VERSION ""

NS_ :

BS_:
BU_: MRR

BO_ 307 MRR_Detection_020: 64 MRR
   SG_ CAN_DET_CONFID_AZIMUTH_20_01 : 33|2@0+ (1,0) [0|3] "" IFV_VFP
   SG_ CAN_DET_SUPER_RES_TARGET_20_01 : 56|1@0+ (1,0) [0|1] "" IFV_VFP
   SG_ CAN_DET_NEW_SIGNAL_20_01 : 62|6@0+ (1,0) [0|64] "" IFV_VFP
   SG_ CAN_DET_ND_TARGET_20_01 : 48|1@0+ (1,0) [0|1] "" IFV_VFP
   SG_ CAN_DET_HOST_VEH_CLUTTER_20_01 : 49|1@0+ (1,0) [0|1] "" IFV_VFP
   SG_ CAN_DET_VALID_LEVEL_20_01 : 0|1@0+ (1,0) [0|1] "" IFV_VFP
   SG_ CAN_DET_AZIMUTH_20_01 : 47|14@0+ (0.0003834,-3.1416) [-3.1416|3.13964] "rad" IFV_VFP
   SG_ CAN_DET_RANGE_20_01 : 31|14@0+ (0.015625,0) [0|255.984] "m" IFV_VFP
   SG_ CAN_DET_RANGE_RATE_20_01 : 15|14@0+ (0.015625,-128) [-128|127.984] "m/s" IFV_VFP
   SG_ CAN_DET_AMPLITUDE_20_01 : 7|7@0+ (1,-64) [-64|63] "dBsm" IFV_VFP
   SG_ CAN_SCAN_INDEX_2LSB_20_01 : 17|2@0+ (1,0) [0|3] "" IFV_VFP
   SG_ CAN_DET_CONFID_AZIMUTH_20_02 : 105|2@0+ (1,0) [0|3] "" IFV_VFP
   SG_ CAN_DET_SUPER_RES_TARGET_20_02 : 128|1@0+ (1,0) [0|1] "" IFV_VFP
   SG_ CAN_DET_NEW_SIGNAL_20_02 : 134|6@0+ (1,0) [0|64] "" IFV_VFP
   SG_ CAN_DET_ND_TARGET_20_02 : 120|1@0+ (1,0) [0|1] "" IFV_VFP
   SG_ CAN_DET_HOST_VEH_CLUTTER_20_02 : 121|1@0+ (1,0) [0|1] "" IFV_VFP
   SG_ CAN_DET_VALID_LEVEL_20_02 : 72|1@0+ (1,0) [0|1] "" IFV_VFP
   SG_ CAN_DET_AZIMUTH_20_02 : 119|14@0+ (0.0003834,-3.1416) [-3.1416|3.13964] "rad" IFV_VFP
   SG_ CAN_DET_RANGE_20_02 : 103|14@0+ (0.015625,0) [0|255.984] "m" IFV_VFP
   SG_ CAN_DET_RANGE_RATE_20_02 : 87|14@0+ (0.015625,-128) [-128|127.984] "m/s" IFV_VFP
   SG_ CAN_DET_AMPLITUDE_20_02 : 79|7@0+ (1,-64) [-64|63] "dBsm" IFV_VFP
   SG_ CAN_SCAN_INDEX_2LSB_20_02 : 89|2@0+ (1,0) [0|3] "" IFV_VFP
   SG_ CAN_DET_CONFID_AZIMUTH_20_03 : 177|2@0+ (1,0) [0|3] "" IFV_VFP
   SG_ CAN_DET_SUPER_RES_TARGET_20_03 : 200|1@0+ (1,0) [0|1] "" IFV_VFP
   SG_ CAN_DET_NEW_SIGNAL_20_03 : 206|6@0+ (1,0) [0|64] "" IFV_VFP
   SG_ CAN_DET_ND_TARGET_20_03 : 192|1@0+ (1,0) [0|1] "" IFV_VFP
   SG_ CAN_DET_HOST_VEH_CLUTTER_20_03 : 193|1@0+ (1,0) [0|1] "" IFV_VFP
   SG_ CAN_DET_VALID_LEVEL_20_03 : 144|1@0+ (1,0) [0|1] "" IFV_VFP
   SG_ CAN_DET_AZIMUTH_20_03 : 191|14@0+ (0.0003834,-3.1416) [-3.1416|3.13964] "rad" IFV_VFP
   SG_ CAN_DET_RANGE_20_03 : 175|14@0+ (0.015625,0) [0|255.984] "m" IFV_VFP
   SG_ CAN_DET_RANGE_RATE_20_03 : 159|14@0+ (0.015625,-128) [-128|127.984] "m/s" IFV_VFP
   SG_ CAN_DET_AMPLITUDE_20_03 : 151|7@0+ (1,-64) [-64|63] "dBsm" IFV_VFP
   SG_ CAN_SCAN_INDEX_2LSB_20_03 : 161|2@0+ (1,0) [0|3] "" IFV_VFP
   SG_ CAN_DET_CONFID_AZIMUTH_20_04 : 249|2@0+ (1,0) [0|3] "" IFV_VFP
   SG_ CAN_DET_SUPER_RES_TARGET_20_04 : 272|1@0+ (1,0) [0|1] "" IFV_VFP
   SG_ CAN_DET_NEW_SIGNAL_20_04 : 278|6@0+ (1,0) [0|64] "" IFV_VFP
   SG_ CAN_DET_ND_TARGET_20_04 : 264|1@0+ (1,0) [0|1] "" IFV_VFP
   SG_ CAN_DET_HOST_VEH_CLUTTER_20_04 : 265|1@0+ (1,0) [0|1] "" IFV_VFP
   SG_ CAN_DET_VALID_LEVEL_20_04 : 216|1@0+ (1,0) [0|1] "" IFV_VFP
   SG_ CAN_DET_AZIMUTH_20_04 : 263|14@0+ (0.0003834,-3.1416) [-3.1416|3.13964] "rad" IFV_VFP
   SG_ CAN_DET_RANGE_20_04 : 247|14@0+ (0.015625,0) [0|255.984] "m" IFV_VFP
   SG_ CAN_DET_RANGE_RATE_20_04 : 231|14@0+ (0.015625,-128) [-128|127.984] "m/s" IFV_VFP
   SG_ CAN_DET_AMPLITUDE_20_04 : 223|7@0+ (1,-64) [-64|63] "dBsm" IFV_VFP
   SG_ CAN_SCAN_INDEX_2LSB_20_04 : 233|2@0+ (1,0) [0|3] "" IFV_VFP
   SG_ CAN_DET_CONFID_AZIMUTH_20_05 : 321|2@0+ (1,0) [0|3] "" IFV_VFP
   SG_ CAN_DET_SUPER_RES_TARGET_20_05 : 344|1@0+ (1,0) [0|1] "" IFV_VFP
   SG_ CAN_DET_NEW_SIGNAL_20_05 : 350|6@0+ (1,0) [0|64] "" IFV_VFP
   SG_ CAN_DET_ND_TARGET_20_05 : 336|1@0+ (1,0) [0|1] "" IFV_VFP
   SG_ CAN_DET_HOST_VEH_CLUTTER_20_05 : 337|1@0+ (1,0) [0|1] "" IFV_VFP
   SG_ CAN_DET_VALID_LEVEL_20_05 : 288|1@0+ (1,0) [0|1] "" IFV_VFP
   SG_ CAN_DET_AZIMUTH_20_05 : 335|14@0+ (0.0003834,-3.1416) [-3.1416|3.13964] "rad" IFV_VFP
   SG_ CAN_DET_RANGE_20_05 : 319|14@0+ (0.015625,0) [0|255.984] "m" IFV_VFP
   SG_ CAN_DET_RANGE_RATE_20_05 : 303|14@0+ (0.015625,-128) [-128|127.984] "m/s" IFV_VFP
   SG_ CAN_DET_AMPLITUDE_20_05 : 295|7@0+ (1,-64) [-64|63] "dBsm" IFV_VFP
   SG_ CAN_SCAN_INDEX_2LSB_20_05 : 305|2@0+ (1,0) [0|3] "" IFV_VFP
   SG_ CAN_DET_CONFID_AZIMUTH_20_06 : 393|2@0+ (1,0) [0|3] "" IFV_VFP
   SG_ CAN_DET_SUPER_RES_TARGET_20_06 : 416|1@0+ (1,0) [0|1] "" IFV_VFP
   SG_ CAN_DET_NEW_SIGNAL_20_06 : 422|6@0+ (1,0) [0|64] "" IFV_VFP
   SG_ CAN_DET_ND_TARGET_20_06 : 408|1@0+ (1,0) [0|1] "" IFV_VFP
   SG_ CAN_DET_HOST_VEH_CLUTTER_20_06 : 409|1@0+ (1,0) [0|1] "" IFV_VFP
   SG_ CAN_DET_VALID_LEVEL_20_06 : 360|1@0+ (1,0) [0|1] "" IFV_VFP
   SG_ CAN_DET_AZIMUTH_20_06 : 407|14@0+ (0.0003834,-3.1416) [-3.1416|3.13964] "rad" IFV_VFP
   SG_ CAN_DET_RANGE_20_06 : 391|14@0+ (0.015625,0) [0|255.984] "m" IFV_VFP
   SG_ CAN_DET_RANGE_RATE_20_06 : 375|14@0+ (0.015625,-128) [-128|127.984] "m/s" IFV_VFP
   SG_ CAN_DET_AMPLITUDE_20_06 : 367|7@0+ (1,-64) [-64|63] "dBsm" IFV_VFP
   SG_ CAN_SCAN_INDEX_2LSB_20_06 : 377|2@0+ (1,0) [0|3] "" IFV_VFP

BO_ 306 MRR_Detection_019: 64 MRR
   SG_ CAN_DET_CONFID_AZIMUTH_19_01 : 33|2@0+ (1,0) [0|3] "" IFV_VFP
   SG_ CAN_DET_SUPER_RES_TARGET_19_01 : 56|1@0+ (1,0) [0|1] "" IFV_VFP
   SG_ CAN_DET_NEW_SIGNAL_19_01 : 62|6@0+ (1,0) [0|64] "" IFV_VFP
   SG_ CAN_DET_ND_TARGET_19_01 : 48|1@0+ (1,0) [0|1] "" IFV_VFP
   SG_ CAN_DET_HOST_VEH_CLUTTER_19_01 : 49|1@0+ (1,0) [0|1] "" IFV_VFP
   SG_ CAN_DET_VALID_LEVEL_19_01 : 0|1@0+ (1,0) [0|1] "" IFV_VFP
   SG_ CAN_DET_AZIMUTH_19_01 : 47|14@0+ (0.0003834,-3.1416) [-3.1416|3.13964] "rad" IFV_VFP
   SG_ CAN_DET_RANGE_19_01 : 31|14@0+ (0.015625,0) [0|255.984] "m" IFV_VFP
   SG_ CAN_DET_RANGE_RATE_19_01 : 15|14@0+ (0.015625,-128) [-128|127.984] "m/s" IFV_VFP
   SG_ CAN_DET_AMPLITUDE_19_01 : 7|7@0+ (1,-64) [-64|63] "dBsm" IFV_VFP
   SG_ CAN_SCAN_INDEX_2LSB_19_01 : 17|2@0+ (1,0) [0|3] "" IFV_VFP
   SG_ CAN_DET_CONFID_AZIMUTH_19_02 : 105|2@0+ (1,0) [0|3] "" IFV_VFP
   SG_ CAN_DET_SUPER_RES_TARGET_19_02 : 128|1@0+ (1,0) [0|1] "" IFV_VFP
   SG_ CAN_DET_NEW_SIGNAL_19_02 : 134|6@0+ (1,0) [0|64] "" IFV_VFP
   SG_ CAN_DET_ND_TARGET_19_02 : 120|1@0+ (1,0) [0|1] "" IFV_VFP
   SG_ CAN_DET_HOST_VEH_CLUTTER_19_02 : 121|1@0+ (1,0) [0|1] "" IFV_VFP
   SG_ CAN_DET_VALID_LEVEL_19_02 : 72|1@0+ (1,0) [0|1] "" IFV_VFP
   SG_ CAN_DET_AZIMUTH_19_02 : 119|14@0+ (0.0003834,-3.1416) [-3.1416|3.13964] "rad" IFV_VFP
   SG_ CAN_DET_RANGE_19_02 : 103|14@0+ (0.015625,0) [0|255.984] "m" IFV_VFP
   SG_ CAN_DET_RANGE_RATE_19_02 : 87|14@0+ (0.015625,-128) [-128|127.984] "m/s" IFV_VFP
   SG_ CAN_DET_AMPLITUDE_19_02 : 79|7@0+ (1,-64) [-64|63] "dBsm" IFV_VFP
   SG_ CAN_SCAN_INDEX_2LSB_19_02 : 89|2@0+ (1,0) [0|3] "" IFV_VFP
   SG_ CAN_DET_CONFID_AZIMUTH_19_03 : 177|2@0+ (1,0) [0|3] "" IFV_VFP
   SG_ CAN_DET_SUPER_RES_TARGET_19_03 : 200|1@0+ (1,0) [0|1] "" IFV_VFP
   SG_ CAN_DET_NEW_SIGNAL_19_03 : 206|6@0+ (1,0) [0|64] "" IFV_VFP
   SG_ CAN_DET_ND_TARGET_19_03 : 192|1@0+ (1,0) [0|1] "" IFV_VFP
   SG_ CAN_DET_HOST_VEH_CLUTTER_19_03 : 193|1@0+ (1,0) [0|1] "" IFV_VFP
   SG_ CAN_DET_VALID_LEVEL_19_03 : 144|1@0+ (1,0) [0|1] "" IFV_VFP
   SG_ CAN_DET_AZIMUTH_19_03 : 191|14@0+ (0.0003834,-3.1416) [-3.1416|3.13964] "rad" IFV_VFP
   SG_ CAN_DET_RANGE_19_03 : 175|14@0+ (0.015625,0) [0|255.984] "m" IFV_VFP
   SG_ CAN_DET_RANGE_RATE_19_03 : 159|14@0+ (0.015625,-128) [-128|127.984] "m/s" IFV_VFP
   SG_ CAN_DET_AMPLITUDE_19_03 : 151|7@0+ (1,-64) [-64|63] "dBsm" IFV_VFP
   SG_ CAN_SCAN_INDEX_2LSB_19_03 : 161|2@0+ (1,0) [0|3] "" IFV_VFP
   SG_ CAN_DET_CONFID_AZIMUTH_19_04 : 249|2@0+ (1,0) [0|3] "" IFV_VFP
   SG_ CAN_DET_SUPER_RES_TARGET_19_04 : 272|1@0+ (1,0) [0|1] "" IFV_VFP
   SG_ CAN_DET_NEW_SIGNAL_19_04 : 278|6@0+ (1,0) [0|64] "" IFV_VFP
   SG_ CAN_DET_ND_TARGET_19_04 : 264|1@0+ (1,0) [0|1] "" IFV_VFP
   SG_ CAN_DET_HOST_VEH_CLUTTER_19_04 : 265|1@0+ (1,0) [0|1] "" IFV_VFP
   SG_ CAN_DET_VALID_LEVEL_19_04 : 216|1@0+ (1,0) [0|1] "" IFV_VFP
   SG_ CAN_DET_AZIMUTH_19_04 : 263|14@0+ (0.0003834,-3.1416) [-3.1416|3.13964] "rad" IFV_VFP
   SG_ CAN_DET_RANGE_19_04 : 247|14@0+ (0.015625,0) [0|255.984] "m" IFV_VFP
   SG_ CAN_DET_RANGE_RATE_19_04 : 231|14@0+ (0.015625,-128) [-128|127.984] "m/s" IFV_VFP
   SG_ CAN_DET_AMPLITUDE_19_04 : 223|7@0+ (1,-64) [-64|63] "dBsm" IFV_VFP
   SG_ CAN_SCAN_INDEX_2LSB_19_04 : 233|2@0+ (1,0) [0|3] "" IFV_VFP
   SG_ CAN_DET_CONFID_AZIMUTH_19_05 : 321|2@0+ (1,0) [0|3] "" IFV_VFP
   SG_ CAN_DET_SUPER_RES_TARGET_19_05 : 344|1@0+ (1,0) [0|1] "" IFV_VFP
   SG_ CAN_DET_NEW_SIGNAL_19_05 : 350|6@0+ (1,0) [0|64] "" IFV_VFP
   SG_ CAN_DET_ND_TARGET_19_05 : 336|1@0+ (1,0) [0|1] "" IFV_VFP
   SG_ CAN_DET_HOST_VEH_CLUTTER_19_05 : 337|1@0+ (1,0) [0|1] "" IFV_VFP
   SG_ CAN_DET_VALID_LEVEL_19_05 : 288|1@0+ (1,0) [0|1] "" IFV_VFP
   SG_ CAN_DET_AZIMUTH_19_05 : 335|14@0+ (0.0003834,-3.1416) [-3.1416|3.13964] "rad" IFV_VFP
   SG_ CAN_DET_RANGE_19_05 : 319|14@0+ (0.015625,0) [0|255.984] "m" IFV_VFP
   SG_ CAN_DET_RANGE_RATE_19_05 : 303|14@0+ (0.015625,-128) [-128|127.984] "m/s" IFV_VFP
   SG_ CAN_DET_AMPLITUDE_19_05 : 295|7@0+ (1,-64) [-64|63] "dBsm" IFV_VFP
   SG_ CAN_SCAN_INDEX_2LSB_19_05 : 305|2@0+ (1,0) [0|3] "" IFV_VFP
   SG_ CAN_DET_CONFID_AZIMUTH_19_06 : 393|2@0+ (1,0) [0|3] "" IFV_VFP
   SG_ CAN_DET_SUPER_RES_TARGET_19_06 : 416|1@0+ (1,0) [0|1] "" IFV_VFP
   SG_ CAN_DET_NEW_SIGNAL_19_06 : 422|6@0+ (1,0) [0|64] "" IFV_VFP
   SG_ CAN_DET_ND_TARGET_19_06 : 408|1@0+ (1,0) [0|1] "" IFV_VFP
   SG_ CAN_DET_HOST_VEH_CLUTTER_19_06 : 409|1@0+ (1,0) [0|1] "" IFV_VFP
   SG_ CAN_DET_VALID_LEVEL_19_06 : 360|1@0+ (1,0) [0|1] "" IFV_VFP
   SG_ CAN_DET_AZIMUTH_19_06 : 407|14@0+ (0.0003834,-3.1416) [-3.1416|3.13964] "rad" IFV_VFP
   SG_ CAN_DET_RANGE_19_06 : 391|14@0+ (0.015625,0) [0|255.984] "m" IFV_VFP
   SG_ CAN_DET_RANGE_RATE_19_06 : 375|14@0+ (0.015625,-128) [-128|127.984] "m/s" IFV_VFP
   SG_ CAN_DET_AMPLITUDE_19_06 : 367|7@0+ (1,-64) [-64|63] "dBsm" IFV_VFP
   SG_ CAN_SCAN_INDEX_2LSB_19_06 : 377|2@0+ (1,0) [0|3] "" IFV_VFP

BO_ 305 MRR_Detection_018: 64 MRR
   SG_ CAN_DET_CONFID_AZIMUTH_18_01 : 33|2@0+ (1,0) [0|3] "" IFV_VFP
   SG_ CAN_DET_SUPER_RES_TARGET_18_01 : 56|1@0+ (1,0) [0|1] "" IFV_VFP
   SG_ CAN_DET_NEW_SIGNAL_18_01 : 62|6@0+ (1,0) [0|64] "" IFV_VFP
   SG_ CAN_DET_ND_TARGET_18_01 : 48|1@0+ (1,0) [0|1] "" IFV_VFP
   SG_ CAN_DET_HOST_VEH_CLUTTER_18_01 : 49|1@0+ (1,0) [0|1] "" IFV_VFP
   SG_ CAN_DET_VALID_LEVEL_18_01 : 0|1@0+ (1,0) [0|1] "" IFV_VFP
   SG_ CAN_DET_AZIMUTH_18_01 : 47|14@0+ (0.0003834,-3.1416) [-3.1416|3.13964] "rad" IFV_VFP
   SG_ CAN_DET_RANGE_18_01 : 31|14@0+ (0.015625,0) [0|255.984] "m" IFV_VFP
   SG_ CAN_DET_RANGE_RATE_18_01 : 15|14@0+ (0.015625,-128) [-128|127.984] "m/s" IFV_VFP
   SG_ CAN_DET_AMPLITUDE_18_01 : 7|7@0+ (1,-64) [-64|63] "dBsm" IFV_VFP
   SG_ CAN_SCAN_INDEX_2LSB_18_01 : 17|2@0+ (1,0) [0|3] "" IFV_VFP
   SG_ CAN_DET_CONFID_AZIMUTH_18_02 : 105|2@0+ (1,0) [0|3] "" IFV_VFP
   SG_ CAN_DET_SUPER_RES_TARGET_18_02 : 128|1@0+ (1,0) [0|1] "" IFV_VFP
   SG_ CAN_DET_NEW_SIGNAL_18_02 : 134|6@0+ (1,0) [0|64] "" IFV_VFP
   SG_ CAN_DET_ND_TARGET_18_02 : 120|1@0+ (1,0) [0|1] "" IFV_VFP
   SG_ CAN_DET_HOST_VEH_CLUTTER_18_02 : 121|1@0+ (1,0) [0|1] "" IFV_VFP
   SG_ CAN_DET_VALID_LEVEL_18_02 : 72|1@0+ (1,0) [0|1] "" IFV_VFP
   SG_ CAN_DET_AZIMUTH_18_02 : 119|14@0+ (0.0003834,-3.1416) [-3.1416|3.13964] "rad" IFV_VFP
   SG_ CAN_DET_RANGE_18_02 : 103|14@0+ (0.015625,0) [0|255.984] "m" IFV_VFP
   SG_ CAN_DET_RANGE_RATE_18_02 : 87|14@0+ (0.015625,-128) [-128|127.984] "m/s" IFV_VFP
   SG_ CAN_DET_AMPLITUDE_18_02 : 79|7@0+ (1,-64) [-64|63] "dBsm" IFV_VFP
   SG_ CAN_SCAN_INDEX_2LSB_18_02 : 89|2@0+ (1,0) [0|3] "" IFV_VFP
   SG_ CAN_DET_CONFID_AZIMUTH_18_03 : 177|2@0+ (1,0) [0|3] "" IFV_VFP
   SG_ CAN_DET_SUPER_RES_TARGET_18_03 : 200|1@0+ (1,0) [0|1] "" IFV_VFP
   SG_ CAN_DET_NEW_SIGNAL_18_03 : 206|6@0+ (1,0) [0|64] "" IFV_VFP
   SG_ CAN_DET_ND_TARGET_18_03 : 192|1@0+ (1,0) [0|1] "" IFV_VFP
   SG_ CAN_DET_HOST_VEH_CLUTTER_18_03 : 193|1@0+ (1,0) [0|1] "" IFV_VFP
   SG_ CAN_DET_VALID_LEVEL_18_03 : 144|1@0+ (1,0) [0|1] "" IFV_VFP
   SG_ CAN_DET_AZIMUTH_18_03 : 191|14@0+ (0.0003834,-3.1416) [-3.1416|3.13964] "rad" IFV_VFP
   SG_ CAN_DET_RANGE_18_03 : 175|14@0+ (0.015625,0) [0|255.984] "m" IFV_VFP
   SG_ CAN_DET_RANGE_RATE_18_03 : 159|14@0+ (0.015625,-128) [-128|127.984] "m/s" IFV_VFP
   SG_ CAN_DET_AMPLITUDE_18_03 : 151|7@0+ (1,-64) [-64|63] "dBsm" IFV_VFP
   SG_ CAN_SCAN_INDEX_2LSB_18_03 : 161|2@0+ (1,0) [0|3] "" IFV_VFP
   SG_ CAN_DET_CONFID_AZIMUTH_18_04 : 249|2@0+ (1,0) [0|3] "" IFV_VFP
   SG_ CAN_DET_SUPER_RES_TARGET_18_04 : 272|1@0+ (1,0) [0|1] "" IFV_VFP
   SG_ CAN_DET_NEW_SIGNAL_18_04 : 278|6@0+ (1,0) [0|64] "" IFV_VFP
   SG_ CAN_DET_ND_TARGET_18_04 : 264|1@0+ (1,0) [0|1] "" IFV_VFP
   SG_ CAN_DET_HOST_VEH_CLUTTER_18_04 : 265|1@0+ (1,0) [0|1] "" IFV_VFP
   SG_ CAN_DET_VALID_LEVEL_18_04 : 216|1@0+ (1,0) [0|1] "" IFV_VFP
   SG_ CAN_DET_AZIMUTH_18_04 : 263|14@0+ (0.0003834,-3.1416) [-3.1416|3.13964] "rad" IFV_VFP
   SG_ CAN_DET_RANGE_18_04 : 247|14@0+ (0.015625,0) [0|255.984] "m" IFV_VFP
   SG_ CAN_DET_RANGE_RATE_18_04 : 231|14@0+ (0.015625,-128) [-128|127.984] "m/s" IFV_VFP
   SG_ CAN_DET_AMPLITUDE_18_04 : 223|7@0+ (1,-64) [-64|63] "dBsm" IFV_VFP
   SG_ CAN_SCAN_INDEX_2LSB_18_04 : 233|2@0+ (1,0) [0|3] "" IFV_VFP
   SG_ CAN_DET_CONFID_AZIMUTH_18_05 : 321|2@0+ (1,0) [0|3] "" IFV_VFP
   SG_ CAN_DET_SUPER_RES_TARGET_18_05 : 344|1@0+ (1,0) [0|1] "" IFV_VFP
   SG_ CAN_DET_NEW_SIGNAL_18_05 : 350|6@0+ (1,0) [0|64] "" IFV_VFP
   SG_ CAN_DET_ND_TARGET_18_05 : 336|1@0+ (1,0) [0|1] "" IFV_VFP
   SG_ CAN_DET_HOST_VEH_CLUTTER_18_05 : 337|1@0+ (1,0) [0|1] "" IFV_VFP
   SG_ CAN_DET_VALID_LEVEL_18_05 : 288|1@0+ (1,0) [0|1] "" IFV_VFP
   SG_ CAN_DET_AZIMUTH_18_05 : 335|14@0+ (0.0003834,-3.1416) [-3.1416|3.13964] "rad" IFV_VFP
   SG_ CAN_DET_RANGE_18_05 : 319|14@0+ (0.015625,0) [0|255.984] "m" IFV_VFP
   SG_ CAN_DET_RANGE_RATE_18_05 : 303|14@0+ (0.015625,-128) [-128|127.984] "m/s" IFV_VFP
   SG_ CAN_DET_AMPLITUDE_18_05 : 295|7@0+ (1,-64) [-64|63] "dBsm" IFV_VFP
   SG_ CAN_SCAN_INDEX_2LSB_18_05 : 305|2@0+ (1,0) [0|3] "" IFV_VFP
   SG_ CAN_DET_CONFID_AZIMUTH_18_06 : 393|2@0+ (1,0) [0|3] "" IFV_VFP
   SG_ CAN_DET_SUPER_RES_TARGET_18_06 : 416|1@0+ (1,0) [0|1] "" IFV_VFP
   SG_ CAN_DET_NEW_SIGNAL_18_06 : 422|6@0+ (1,0) [0|64] "" IFV_VFP
   SG_ CAN_DET_ND_TARGET_18_06 : 408|1@0+ (1,0) [0|1] "" IFV_VFP
   SG_ CAN_DET_HOST_VEH_CLUTTER_18_06 : 409|1@0+ (1,0) [0|1] "" IFV_VFP
   SG_ CAN_DET_VALID_LEVEL_18_06 : 360|1@0+ (1,0) [0|1] "" IFV_VFP
   SG_ CAN_DET_AZIMUTH_18_06 : 407|14@0+ (0.0003834,-3.1416) [-3.1416|3.13964] "rad" IFV_VFP
   SG_ CAN_DET_RANGE_18_06 : 391|14@0+ (0.015625,0) [0|255.984] "m" IFV_VFP
   SG_ CAN_DET_RANGE_RATE_18_06 : 375|14@0+ (0.015625,-128) [-128|127.984] "m/s" IFV_VFP
   SG_ CAN_DET_AMPLITUDE_18_06 : 367|7@0+ (1,-64) [-64|63] "dBsm" IFV_VFP
   SG_ CAN_SCAN_INDEX_2LSB_18_06 : 377|2@0+ (1,0) [0|3] "" IFV_VFP

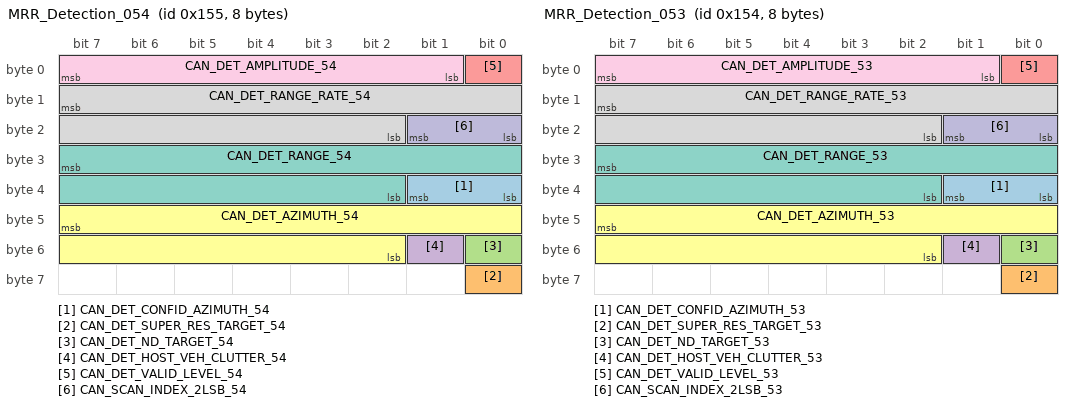
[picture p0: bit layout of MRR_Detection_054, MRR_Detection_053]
BO_ 341 MRR_Detection_054: 8 MRR
   SG_ CAN_DET_CONFID_AZIMUTH_54 : 33|2@0+ (1,0) [0|3] "" IFV_VFP
   SG_ CAN_DET_SUPER_RES_TARGET_54 : 56|1@0+ (1,0) [0|1] "" IFV_VFP
   SG_ CAN_DET_ND_TARGET_54 : 48|1@0+ (1,0) [0|1] "" IFV_VFP
   SG_ CAN_DET_HOST_VEH_CLUTTER_54 : 49|1@0+ (1,0) [0|1] "" IFV_VFP
   SG_ CAN_DET_VALID_LEVEL_54 : 0|1@0+ (1,0) [0|1] "" IFV_VFP
   SG_ CAN_DET_AZIMUTH_54 : 47|14@0+ (0.0003834,-3.1416) [-3.1416|3.13964] "rad" IFV_VFP
   SG_ CAN_DET_RANGE_54 : 31|14@0+ (0.015625,0) [0|255.984] "m" IFV_VFP
   SG_ CAN_DET_RANGE_RATE_54 : 15|14@0+ (0.015625,-128) [-128|127.984] "m/s" IFV_VFP
   SG_ CAN_DET_AMPLITUDE_54 : 7|7@0+ (1,-64) [-64|63] "dBsm" IFV_VFP
   SG_ CAN_SCAN_INDEX_2LSB_54 : 17|2@0+ (1,0) [0|3] "" IFV_VFP

BO_ 340 MRR_Detection_053: 8 MRR
   SG_ CAN_DET_CONFID_AZIMUTH_53 : 33|2@0+ (1,0) [0|3] "" IFV_VFP
   SG_ CAN_DET_SUPER_RES_TARGET_53 : 56|1@0+ (1,0) [0|1] "" IFV_VFP
   SG_ CAN_DET_ND_TARGET_53 : 48|1@0+ (1,0) [0|1] "" IFV_VFP
   SG_ CAN_DET_HOST_VEH_CLUTTER_53 : 49|1@0+ (1,0) [0|1] "" IFV_VFP
   SG_ CAN_DET_VALID_LEVEL_53 : 0|1@0+ (1,0) [0|1] "" IFV_VFP
   SG_ CAN_DET_AZIMUTH_53 : 47|14@0+ (0.0003834,-3.1416) [-3.1416|3.13964] "rad" IFV_VFP
   SG_ CAN_DET_RANGE_53 : 31|14@0+ (0.015625,0) [0|255.984] "m" IFV_VFP
   SG_ CAN_DET_RANGE_RATE_53 : 15|14@0+ (0.015625,-128) [-128|127.984] "m/s" IFV_VFP
   SG_ CAN_DET_AMPLITUDE_53 : 7|7@0+ (1,-64) [-64|63] "dBsm" IFV_VFP
   SG_ CAN_SCAN_INDEX_2LSB_53 : 17|2@0+ (1,0) [0|3] "" IFV_VFP

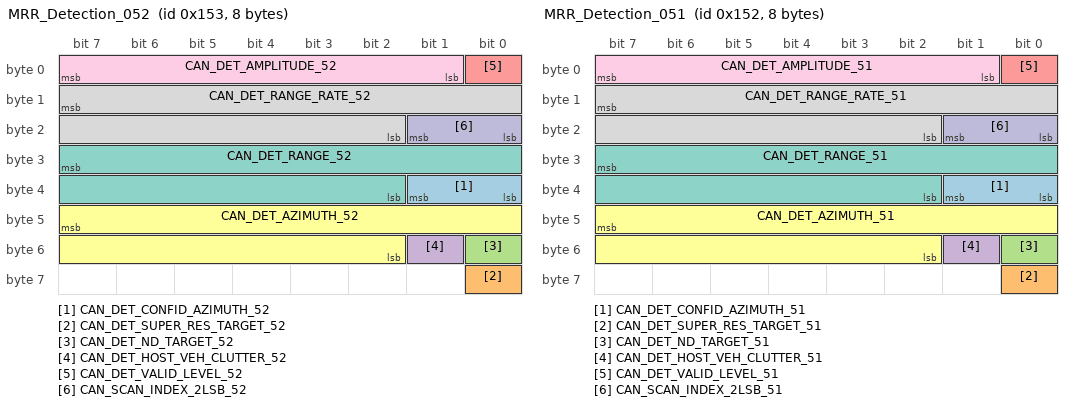
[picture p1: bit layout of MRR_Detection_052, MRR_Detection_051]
BO_ 339 MRR_Detection_052: 8 MRR
   SG_ CAN_DET_CONFID_AZIMUTH_52 : 33|2@0+ (1,0) [0|3] "" IFV_VFP
   SG_ CAN_DET_SUPER_RES_TARGET_52 : 56|1@0+ (1,0) [0|1] "" IFV_VFP
   SG_ CAN_DET_ND_TARGET_52 : 48|1@0+ (1,0) [0|1] "" IFV_VFP
   SG_ CAN_DET_HOST_VEH_CLUTTER_52 : 49|1@0+ (1,0) [0|1] "" IFV_VFP
   SG_ CAN_DET_VALID_LEVEL_52 : 0|1@0+ (1,0) [0|1] "" IFV_VFP
   SG_ CAN_DET_AZIMUTH_52 : 47|14@0+ (0.0003834,-3.1416) [-3.1416|3.13964] "rad" IFV_VFP
   SG_ CAN_DET_RANGE_52 : 31|14@0+ (0.015625,0) [0|255.984] "m" IFV_VFP
   SG_ CAN_DET_RANGE_RATE_52 : 15|14@0+ (0.015625,-128) [-128|127.984] "m/s" IFV_VFP
   SG_ CAN_DET_AMPLITUDE_52 : 7|7@0+ (1,-64) [-64|63] "dBsm" IFV_VFP
   SG_ CAN_SCAN_INDEX_2LSB_52 : 17|2@0+ (1,0) [0|3] "" IFV_VFP

BO_ 338 MRR_Detection_051: 8 MRR
   SG_ CAN_DET_CONFID_AZIMUTH_51 : 33|2@0+ (1,0) [0|3] "" IFV_VFP
   SG_ CAN_DET_SUPER_RES_TARGET_51 : 56|1@0+ (1,0) [0|1] "" IFV_VFP
   SG_ CAN_DET_ND_TARGET_51 : 48|1@0+ (1,0) [0|1] "" IFV_VFP
   SG_ CAN_DET_HOST_VEH_CLUTTER_51 : 49|1@0+ (1,0) [0|1] "" IFV_VFP
   SG_ CAN_DET_VALID_LEVEL_51 : 0|1@0+ (1,0) [0|1] "" IFV_VFP
   SG_ CAN_DET_AZIMUTH_51 : 47|14@0+ (0.0003834,-3.1416) [-3.1416|3.13964] "rad" IFV_VFP
   SG_ CAN_DET_RANGE_51 : 31|14@0+ (0.015625,0) [0|255.984] "m" IFV_VFP
   SG_ CAN_DET_RANGE_RATE_51 : 15|14@0+ (0.015625,-128) [-128|127.984] "m/s" IFV_VFP
   SG_ CAN_DET_AMPLITUDE_51 : 7|7@0+ (1,-64) [-64|63] "dBsm" IFV_VFP
   SG_ CAN_SCAN_INDEX_2LSB_51 : 17|2@0+ (1,0) [0|3] "" IFV_VFP

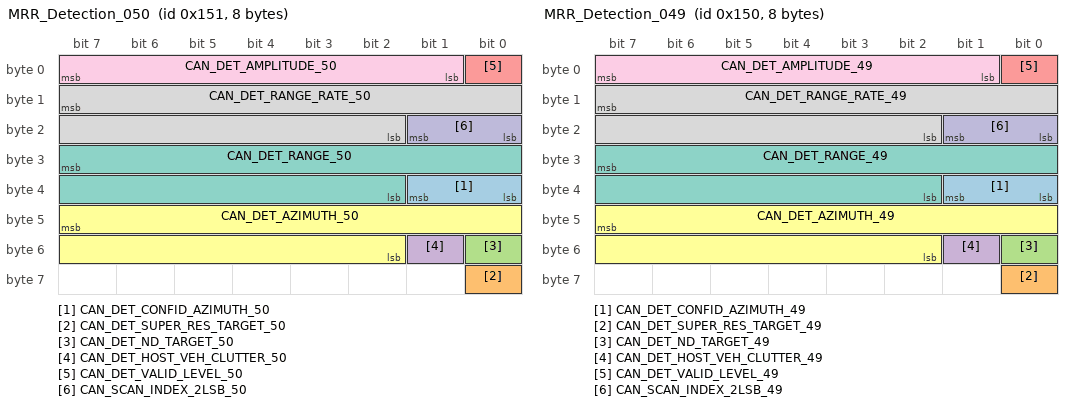
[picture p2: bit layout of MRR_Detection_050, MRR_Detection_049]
BO_ 337 MRR_Detection_050: 8 MRR
   SG_ CAN_DET_CONFID_AZIMUTH_50 : 33|2@0+ (1,0) [0|3] "" IFV_VFP
   SG_ CAN_DET_SUPER_RES_TARGET_50 : 56|1@0+ (1,0) [0|1] "" IFV_VFP
   SG_ CAN_DET_ND_TARGET_50 : 48|1@0+ (1,0) [0|1] "" IFV_VFP
   SG_ CAN_DET_HOST_VEH_CLUTTER_50 : 49|1@0+ (1,0) [0|1] "" IFV_VFP
   SG_ CAN_DET_VALID_LEVEL_50 : 0|1@0+ (1,0) [0|1] "" IFV_VFP
   SG_ CAN_DET_AZIMUTH_50 : 47|14@0+ (0.0003834,-3.1416) [-3.1416|3.13964] "rad" IFV_VFP
   SG_ CAN_DET_RANGE_50 : 31|14@0+ (0.015625,0) [0|255.984] "m" IFV_VFP
   SG_ CAN_DET_RANGE_RATE_50 : 15|14@0+ (0.015625,-128) [-128|127.984] "m/s" IFV_VFP
   SG_ CAN_DET_AMPLITUDE_50 : 7|7@0+ (1,-64) [-64|63] "dBsm" IFV_VFP
   SG_ CAN_SCAN_INDEX_2LSB_50 : 17|2@0+ (1,0) [0|3] "" IFV_VFP

BO_ 336 MRR_Detection_049: 8 MRR
   SG_ CAN_DET_CONFID_AZIMUTH_49 : 33|2@0+ (1,0) [0|3] "" IFV_VFP
   SG_ CAN_DET_SUPER_RES_TARGET_49 : 56|1@0+ (1,0) [0|1] "" IFV_VFP
   SG_ CAN_DET_ND_TARGET_49 : 48|1@0+ (1,0) [0|1] "" IFV_VFP
   SG_ CAN_DET_HOST_VEH_CLUTTER_49 : 49|1@0+ (1,0) [0|1] "" IFV_VFP
   SG_ CAN_DET_VALID_LEVEL_49 : 0|1@0+ (1,0) [0|1] "" IFV_VFP
   SG_ CAN_DET_AZIMUTH_49 : 47|14@0+ (0.0003834,-3.1416) [-3.1416|3.13964] "rad" IFV_VFP
   SG_ CAN_DET_RANGE_49 : 31|14@0+ (0.015625,0) [0|255.984] "m" IFV_VFP
   SG_ CAN_DET_RANGE_RATE_49 : 15|14@0+ (0.015625,-128) [-128|127.984] "m/s" IFV_VFP
   SG_ CAN_DET_AMPLITUDE_49 : 7|7@0+ (1,-64) [-64|63] "dBsm" IFV_VFP
   SG_ CAN_SCAN_INDEX_2LSB_49 : 17|2@0+ (1,0) [0|3] "" IFV_VFP

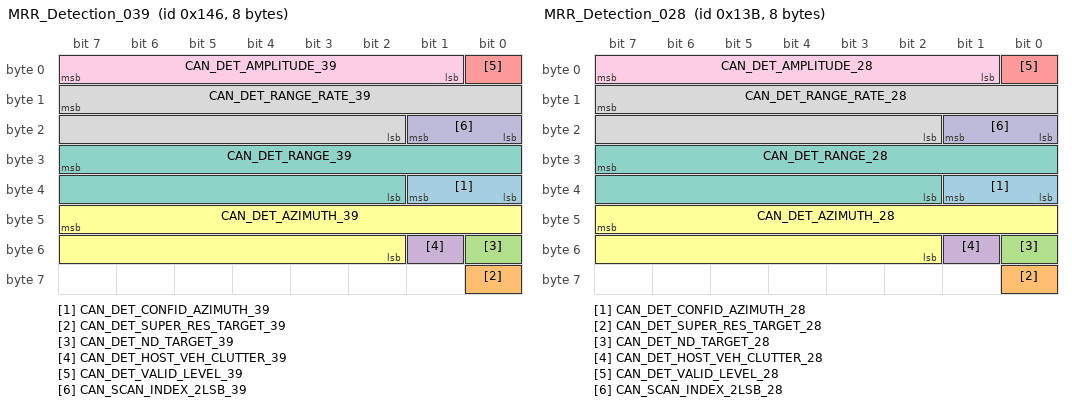
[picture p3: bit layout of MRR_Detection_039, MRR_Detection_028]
BO_ 326 MRR_Detection_039: 8 MRR
   SG_ CAN_DET_CONFID_AZIMUTH_39 : 33|2@0+ (1,0) [0|3] "" IFV_VFP
   SG_ CAN_DET_SUPER_RES_TARGET_39 : 56|1@0+ (1,0) [0|1] "" IFV_VFP
   SG_ CAN_DET_ND_TARGET_39 : 48|1@0+ (1,0) [0|1] "" IFV_VFP
   SG_ CAN_DET_HOST_VEH_CLUTTER_39 : 49|1@0+ (1,0) [0|1] "" IFV_VFP
   SG_ CAN_DET_VALID_LEVEL_39 : 0|1@0+ (1,0) [0|1] "" IFV_VFP
   SG_ CAN_DET_AZIMUTH_39 : 47|14@0+ (0.0003834,-3.1416) [-3.1416|3.13964] "rad" IFV_VFP
   SG_ CAN_DET_RANGE_39 : 31|14@0+ (0.015625,0) [0|255.984] "m" IFV_VFP
   SG_ CAN_DET_RANGE_RATE_39 : 15|14@0+ (0.015625,-128) [-128|127.984] "m/s" IFV_VFP
   SG_ CAN_DET_AMPLITUDE_39 : 7|7@0+ (1,-64) [-64|63] "dBsm" IFV_VFP
   SG_ CAN_SCAN_INDEX_2LSB_39 : 17|2@0+ (1,0) [0|3] "" IFV_VFP

BO_ 315 MRR_Detection_028: 8 MRR
   SG_ CAN_DET_CONFID_AZIMUTH_28 : 33|2@0+ (1,0) [0|3] "" IFV_VFP
   SG_ CAN_DET_SUPER_RES_TARGET_28 : 56|1@0+ (1,0) [0|1] "" IFV_VFP
   SG_ CAN_DET_ND_TARGET_28 : 48|1@0+ (1,0) [0|1] "" IFV_VFP
   SG_ CAN_DET_HOST_VEH_CLUTTER_28 : 49|1@0+ (1,0) [0|1] "" IFV_VFP
   SG_ CAN_DET_VALID_LEVEL_28 : 0|1@0+ (1,0) [0|1] "" IFV_VFP
   SG_ CAN_DET_AZIMUTH_28 : 47|14@0+ (0.0003834,-3.1416) [-3.1416|3.13964] "rad" IFV_VFP
   SG_ CAN_DET_RANGE_28 : 31|14@0+ (0.015625,0) [0|255.984] "m" IFV_VFP
   SG_ CAN_DET_RANGE_RATE_28 : 15|14@0+ (0.015625,-128) [-128|127.984] "m/s" IFV_VFP
   SG_ CAN_DET_AMPLITUDE_28 : 7|7@0+ (1,-64) [-64|63] "dBsm" IFV_VFP
   SG_ CAN_SCAN_INDEX_2LSB_28 : 17|2@0+ (1,0) [0|3] "" IFV_VFP

BO_ 304 MRR_Detection_017: 64 MRR
   SG_ CAN_DET_CONFID_AZIMUTH_17_01 : 33|2@0+ (1,0) [0|3] "" IFV_VFP
   SG_ CAN_DET_SUPER_RES_TARGET_17_01 : 56|1@0+ (1,0) [0|1] "" IFV_VFP
   SG_ CAN_DET_NEW_SIGNAL_17_01 : 62|6@0+ (1,0) [0|64] "" IFV_VFP
   SG_ CAN_DET_ND_TARGET_17_01 : 48|1@0+ (1,0) [0|1] "" IFV_VFP
   SG_ CAN_DET_HOST_VEH_CLUTTER_17_01 : 49|1@0+ (1,0) [0|1] "" IFV_VFP
   SG_ CAN_DET_VALID_LEVEL_17_01 : 0|1@0+ (1,0) [0|1] "" IFV_VFP
   SG_ CAN_DET_AZIMUTH_17_01 : 47|14@0+ (0.0003834,-3.1416) [-3.1416|3.13964] "rad" IFV_VFP
   SG_ CAN_DET_RANGE_17_01 : 31|14@0+ (0.015625,0) [0|255.984] "m" IFV_VFP
   SG_ CAN_DET_RANGE_RATE_17_01 : 15|14@0+ (0.015625,-128) [-128|127.984] "m/s" IFV_VFP
   SG_ CAN_DET_AMPLITUDE_17_01 : 7|7@0+ (1,-64) [-64|63] "dBsm" IFV_VFP
   SG_ CAN_SCAN_INDEX_2LSB_17_01 : 17|2@0+ (1,0) [0|3] "" IFV_VFP
   SG_ CAN_DET_CONFID_AZIMUTH_17_02 : 105|2@0+ (1,0) [0|3] "" IFV_VFP
   SG_ CAN_DET_SUPER_RES_TARGET_17_02 : 128|1@0+ (1,0) [0|1] "" IFV_VFP
   SG_ CAN_DET_NEW_SIGNAL_17_02 : 134|6@0+ (1,0) [0|64] "" IFV_VFP
   SG_ CAN_DET_ND_TARGET_17_02 : 120|1@0+ (1,0) [0|1] "" IFV_VFP
   SG_ CAN_DET_HOST_VEH_CLUTTER_17_02 : 121|1@0+ (1,0) [0|1] "" IFV_VFP
   SG_ CAN_DET_VALID_LEVEL_17_02 : 72|1@0+ (1,0) [0|1] "" IFV_VFP
   SG_ CAN_DET_AZIMUTH_17_02 : 119|14@0+ (0.0003834,-3.1416) [-3.1416|3.13964] "rad" IFV_VFP
   SG_ CAN_DET_RANGE_17_02 : 103|14@0+ (0.015625,0) [0|255.984] "m" IFV_VFP
   SG_ CAN_DET_RANGE_RATE_17_02 : 87|14@0+ (0.015625,-128) [-128|127.984] "m/s" IFV_VFP
   SG_ CAN_DET_AMPLITUDE_17_02 : 79|7@0+ (1,-64) [-64|63] "dBsm" IFV_VFP
   SG_ CAN_SCAN_INDEX_2LSB_17_02 : 89|2@0+ (1,0) [0|3] "" IFV_VFP
   SG_ CAN_DET_CONFID_AZIMUTH_17_03 : 177|2@0+ (1,0) [0|3] "" IFV_VFP
   SG_ CAN_DET_SUPER_RES_TARGET_17_03 : 200|1@0+ (1,0) [0|1] "" IFV_VFP
   SG_ CAN_DET_NEW_SIGNAL_17_03 : 206|6@0+ (1,0) [0|64] "" IFV_VFP
   SG_ CAN_DET_ND_TARGET_17_03 : 192|1@0+ (1,0) [0|1] "" IFV_VFP
   SG_ CAN_DET_HOST_VEH_CLUTTER_17_03 : 193|1@0+ (1,0) [0|1] "" IFV_VFP
   SG_ CAN_DET_VALID_LEVEL_17_03 : 144|1@0+ (1,0) [0|1] "" IFV_VFP
   SG_ CAN_DET_AZIMUTH_17_03 : 191|14@0+ (0.0003834,-3.1416) [-3.1416|3.13964] "rad" IFV_VFP
   SG_ CAN_DET_RANGE_17_03 : 175|14@0+ (0.015625,0) [0|255.984] "m" IFV_VFP
   SG_ CAN_DET_RANGE_RATE_17_03 : 159|14@0+ (0.015625,-128) [-128|127.984] "m/s" IFV_VFP
   SG_ CAN_DET_AMPLITUDE_17_03 : 151|7@0+ (1,-64) [-64|63] "dBsm" IFV_VFP
   SG_ CAN_SCAN_INDEX_2LSB_17_03 : 161|2@0+ (1,0) [0|3] "" IFV_VFP
   SG_ CAN_DET_CONFID_AZIMUTH_17_04 : 249|2@0+ (1,0) [0|3] "" IFV_VFP
   SG_ CAN_DET_SUPER_RES_TARGET_17_04 : 272|1@0+ (1,0) [0|1] "" IFV_VFP
   SG_ CAN_DET_NEW_SIGNAL_17_04 : 278|6@0+ (1,0) [0|64] "" IFV_VFP
   SG_ CAN_DET_ND_TARGET_17_04 : 264|1@0+ (1,0) [0|1] "" IFV_VFP
   SG_ CAN_DET_HOST_VEH_CLUTTER_17_04 : 265|1@0+ (1,0) [0|1] "" IFV_VFP
   SG_ CAN_DET_VALID_LEVEL_17_04 : 216|1@0+ (1,0) [0|1] "" IFV_VFP
   SG_ CAN_DET_AZIMUTH_17_04 : 263|14@0+ (0.0003834,-3.1416) [-3.1416|3.13964] "rad" IFV_VFP
   SG_ CAN_DET_RANGE_17_04 : 247|14@0+ (0.015625,0) [0|255.984] "m" IFV_VFP
   SG_ CAN_DET_RANGE_RATE_17_04 : 231|14@0+ (0.015625,-128) [-128|127.984] "m/s" IFV_VFP
   SG_ CAN_DET_AMPLITUDE_17_04 : 223|7@0+ (1,-64) [-64|63] "dBsm" IFV_VFP
   SG_ CAN_SCAN_INDEX_2LSB_17_04 : 233|2@0+ (1,0) [0|3] "" IFV_VFP
   SG_ CAN_DET_CONFID_AZIMUTH_17_05 : 321|2@0+ (1,0) [0|3] "" IFV_VFP
   SG_ CAN_DET_SUPER_RES_TARGET_17_05 : 344|1@0+ (1,0) [0|1] "" IFV_VFP
   SG_ CAN_DET_NEW_SIGNAL_17_05 : 350|6@0+ (1,0) [0|64] "" IFV_VFP
   SG_ CAN_DET_ND_TARGET_17_05 : 336|1@0+ (1,0) [0|1] "" IFV_VFP
   SG_ CAN_DET_HOST_VEH_CLUTTER_17_05 : 337|1@0+ (1,0) [0|1] "" IFV_VFP
   SG_ CAN_DET_VALID_LEVEL_17_05 : 288|1@0+ (1,0) [0|1] "" IFV_VFP
   SG_ CAN_DET_AZIMUTH_17_05 : 335|14@0+ (0.0003834,-3.1416) [-3.1416|3.13964] "rad" IFV_VFP
   SG_ CAN_DET_RANGE_17_05 : 319|14@0+ (0.015625,0) [0|255.984] "m" IFV_VFP
   SG_ CAN_DET_RANGE_RATE_17_05 : 303|14@0+ (0.015625,-128) [-128|127.984] "m/s" IFV_VFP
   SG_ CAN_DET_AMPLITUDE_17_05 : 295|7@0+ (1,-64) [-64|63] "dBsm" IFV_VFP
   SG_ CAN_SCAN_INDEX_2LSB_17_05 : 305|2@0+ (1,0) [0|3] "" IFV_VFP
   SG_ CAN_DET_CONFID_AZIMUTH_17_06 : 393|2@0+ (1,0) [0|3] "" IFV_VFP
   SG_ CAN_DET_SUPER_RES_TARGET_17_06 : 416|1@0+ (1,0) [0|1] "" IFV_VFP
   SG_ CAN_DET_NEW_SIGNAL_17_06 : 422|6@0+ (1,0) [0|64] "" IFV_VFP
   SG_ CAN_DET_ND_TARGET_17_06 : 408|1@0+ (1,0) [0|1] "" IFV_VFP
   SG_ CAN_DET_HOST_VEH_CLUTTER_17_06 : 409|1@0+ (1,0) [0|1] "" IFV_VFP
   SG_ CAN_DET_VALID_LEVEL_17_06 : 360|1@0+ (1,0) [0|1] "" IFV_VFP
   SG_ CAN_DET_AZIMUTH_17_06 : 407|14@0+ (0.0003834,-3.1416) [-3.1416|3.13964] "rad" IFV_VFP
   SG_ CAN_DET_RANGE_17_06 : 391|14@0+ (0.015625,0) [0|255.984] "m" IFV_VFP
   SG_ CAN_DET_RANGE_RATE_17_06 : 375|14@0+ (0.015625,-128) [-128|127.984] "m/s" IFV_VFP
   SG_ CAN_DET_AMPLITUDE_17_06 : 367|7@0+ (1,-64) [-64|63] "dBsm" IFV_VFP
   SG_ CAN_SCAN_INDEX_2LSB_17_06 : 377|2@0+ (1,0) [0|3] "" IFV_VFP

BO_ 303 MRR_Detection_016: 64 MRR
   SG_ CAN_DET_CONFID_AZIMUTH_16_01 : 33|2@0+ (1,0) [0|3] "" IFV_VFP
   SG_ CAN_DET_SUPER_RES_TARGET_16_01 : 56|1@0+ (1,0) [0|1] "" IFV_VFP
   SG_ CAN_DET_NEW_SIGNAL_16_01 : 62|6@0+ (1,0) [0|64] "" IFV_VFP
   SG_ CAN_DET_ND_TARGET_16_01 : 48|1@0+ (1,0) [0|1] "" IFV_VFP
   SG_ CAN_DET_HOST_VEH_CLUTTER_16_01 : 49|1@0+ (1,0) [0|1] "" IFV_VFP
   SG_ CAN_DET_VALID_LEVEL_16_01 : 0|1@0+ (1,0) [0|1] "" IFV_VFP
   SG_ CAN_DET_AZIMUTH_16_01 : 47|14@0+ (0.0003834,-3.1416) [-3.1416|3.13964] "rad" IFV_VFP
   SG_ CAN_DET_RANGE_16_01 : 31|14@0+ (0.015625,0) [0|255.984] "m" IFV_VFP
   SG_ CAN_DET_RANGE_RATE_16_01 : 15|14@0+ (0.015625,-128) [-128|127.984] "m/s" IFV_VFP
   SG_ CAN_DET_AMPLITUDE_16_01 : 7|7@0+ (1,-64) [-64|63] "dBsm" IFV_VFP
   SG_ CAN_SCAN_INDEX_2LSB_16_01 : 17|2@0+ (1,0) [0|3] "" IFV_VFP
   SG_ CAN_DET_CONFID_AZIMUTH_16_02 : 105|2@0+ (1,0) [0|3] "" IFV_VFP
   SG_ CAN_DET_SUPER_RES_TARGET_16_02 : 128|1@0+ (1,0) [0|1] "" IFV_VFP
   SG_ CAN_DET_NEW_SIGNAL_16_02 : 134|6@0+ (1,0) [0|64] "" IFV_VFP
   SG_ CAN_DET_ND_TARGET_16_02 : 120|1@0+ (1,0) [0|1] "" IFV_VFP
   SG_ CAN_DET_HOST_VEH_CLUTTER_16_02 : 121|1@0+ (1,0) [0|1] "" IFV_VFP
   SG_ CAN_DET_VALID_LEVEL_16_02 : 72|1@0+ (1,0) [0|1] "" IFV_VFP
   SG_ CAN_DET_AZIMUTH_16_02 : 119|14@0+ (0.0003834,-3.1416) [-3.1416|3.13964] "rad" IFV_VFP
   SG_ CAN_DET_RANGE_16_02 : 103|14@0+ (0.015625,0) [0|255.984] "m" IFV_VFP
   SG_ CAN_DET_RANGE_RATE_16_02 : 87|14@0+ (0.015625,-128) [-128|127.984] "m/s" IFV_VFP
   SG_ CAN_DET_AMPLITUDE_16_02 : 79|7@0+ (1,-64) [-64|63] "dBsm" IFV_VFP
   SG_ CAN_SCAN_INDEX_2LSB_16_02 : 89|2@0+ (1,0) [0|3] "" IFV_VFP
   SG_ CAN_DET_CONFID_AZIMUTH_16_03 : 177|2@0+ (1,0) [0|3] "" IFV_VFP
   SG_ CAN_DET_SUPER_RES_TARGET_16_03 : 200|1@0+ (1,0) [0|1] "" IFV_VFP
   SG_ CAN_DET_NEW_SIGNAL_16_03 : 206|6@0+ (1,0) [0|64] "" IFV_VFP
   SG_ CAN_DET_ND_TARGET_16_03 : 192|1@0+ (1,0) [0|1] "" IFV_VFP
   SG_ CAN_DET_HOST_VEH_CLUTTER_16_03 : 193|1@0+ (1,0) [0|1] "" IFV_VFP
   SG_ CAN_DET_VALID_LEVEL_16_03 : 144|1@0+ (1,0) [0|1] "" IFV_VFP
   SG_ CAN_DET_AZIMUTH_16_03 : 191|14@0+ (0.0003834,-3.1416) [-3.1416|3.13964] "rad" IFV_VFP
   SG_ CAN_DET_RANGE_16_03 : 175|14@0+ (0.015625,0) [0|255.984] "m" IFV_VFP
   SG_ CAN_DET_RANGE_RATE_16_03 : 159|14@0+ (0.015625,-128) [-128|127.984] "m/s" IFV_VFP
   SG_ CAN_DET_AMPLITUDE_16_03 : 151|7@0+ (1,-64) [-64|63] "dBsm" IFV_VFP
   SG_ CAN_SCAN_INDEX_2LSB_16_03 : 161|2@0+ (1,0) [0|3] "" IFV_VFP
   SG_ CAN_DET_CONFID_AZIMUTH_16_04 : 249|2@0+ (1,0) [0|3] "" IFV_VFP
   SG_ CAN_DET_SUPER_RES_TARGET_16_04 : 272|1@0+ (1,0) [0|1] "" IFV_VFP
   SG_ CAN_DET_NEW_SIGNAL_16_04 : 278|6@0+ (1,0) [0|64] "" IFV_VFP
   SG_ CAN_DET_ND_TARGET_16_04 : 264|1@0+ (1,0) [0|1] "" IFV_VFP
   SG_ CAN_DET_HOST_VEH_CLUTTER_16_04 : 265|1@0+ (1,0) [0|1] "" IFV_VFP
   SG_ CAN_DET_VALID_LEVEL_16_04 : 216|1@0+ (1,0) [0|1] "" IFV_VFP
   SG_ CAN_DET_AZIMUTH_16_04 : 263|14@0+ (0.0003834,-3.1416) [-3.1416|3.13964] "rad" IFV_VFP
   SG_ CAN_DET_RANGE_16_04 : 247|14@0+ (0.015625,0) [0|255.984] "m" IFV_VFP
   SG_ CAN_DET_RANGE_RATE_16_04 : 231|14@0+ (0.015625,-128) [-128|127.984] "m/s" IFV_VFP
   SG_ CAN_DET_AMPLITUDE_16_04 : 223|7@0+ (1,-64) [-64|63] "dBsm" IFV_VFP
   SG_ CAN_SCAN_INDEX_2LSB_16_04 : 233|2@0+ (1,0) [0|3] "" IFV_VFP
   SG_ CAN_DET_CONFID_AZIMUTH_16_05 : 321|2@0+ (1,0) [0|3] "" IFV_VFP
   SG_ CAN_DET_SUPER_RES_TARGET_16_05 : 344|1@0+ (1,0) [0|1] "" IFV_VFP
   SG_ CAN_DET_NEW_SIGNAL_16_05 : 350|6@0+ (1,0) [0|64] "" IFV_VFP
   SG_ CAN_DET_ND_TARGET_16_05 : 336|1@0+ (1,0) [0|1] "" IFV_VFP
   SG_ CAN_DET_HOST_VEH_CLUTTER_16_05 : 337|1@0+ (1,0) [0|1] "" IFV_VFP
   SG_ CAN_DET_VALID_LEVEL_16_05 : 288|1@0+ (1,0) [0|1] "" IFV_VFP
   SG_ CAN_DET_AZIMUTH_16_05 : 335|14@0+ (0.0003834,-3.1416) [-3.1416|3.13964] "rad" IFV_VFP
   SG_ CAN_DET_RANGE_16_05 : 319|14@0+ (0.015625,0) [0|255.984] "m" IFV_VFP
   SG_ CAN_DET_RANGE_RATE_16_05 : 303|14@0+ (0.015625,-128) [-128|127.984] "m/s" IFV_VFP
   SG_ CAN_DET_AMPLITUDE_16_05 : 295|7@0+ (1,-64) [-64|63] "dBsm" IFV_VFP
   SG_ CAN_SCAN_INDEX_2LSB_16_05 : 305|2@0+ (1,0) [0|3] "" IFV_VFP
   SG_ CAN_DET_CONFID_AZIMUTH_16_06 : 393|2@0+ (1,0) [0|3] "" IFV_VFP
   SG_ CAN_DET_SUPER_RES_TARGET_16_06 : 416|1@0+ (1,0) [0|1] "" IFV_VFP
   SG_ CAN_DET_NEW_SIGNAL_16_06 : 422|6@0+ (1,0) [0|64] "" IFV_VFP
   SG_ CAN_DET_ND_TARGET_16_06 : 408|1@0+ (1,0) [0|1] "" IFV_VFP
   SG_ CAN_DET_HOST_VEH_CLUTTER_16_06 : 409|1@0+ (1,0) [0|1] "" IFV_VFP
   SG_ CAN_DET_VALID_LEVEL_16_06 : 360|1@0+ (1,0) [0|1] "" IFV_VFP
   SG_ CAN_DET_AZIMUTH_16_06 : 407|14@0+ (0.0003834,-3.1416) [-3.1416|3.13964] "rad" IFV_VFP
   SG_ CAN_DET_RANGE_16_06 : 391|14@0+ (0.015625,0) [0|255.984] "m" IFV_VFP
   SG_ CAN_DET_RANGE_RATE_16_06 : 375|14@0+ (0.015625,-128) [-128|127.984] "m/s" IFV_VFP
   SG_ CAN_DET_AMPLITUDE_16_06 : 367|7@0+ (1,-64) [-64|63] "dBsm" IFV_VFP
   SG_ CAN_SCAN_INDEX_2LSB_16_06 : 377|2@0+ (1,0) [0|3] "" IFV_VFP

BO_ 302 MRR_Detection_015: 64 MRR
   SG_ CAN_DET_CONFID_AZIMUTH_15_01 : 33|2@0+ (1,0) [0|3] "" IFV_VFP
   SG_ CAN_DET_SUPER_RES_TARGET_15_01 : 56|1@0+ (1,0) [0|1] "" IFV_VFP
   SG_ CAN_DET_NEW_SIGNAL_15_01 : 62|6@0+ (1,0) [0|64] "" IFV_VFP
   SG_ CAN_DET_ND_TARGET_15_01 : 48|1@0+ (1,0) [0|1] "" IFV_VFP
   SG_ CAN_DET_HOST_VEH_CLUTTER_15_01 : 49|1@0+ (1,0) [0|1] "" IFV_VFP
   SG_ CAN_DET_VALID_LEVEL_15_01 : 0|1@0+ (1,0) [0|1] "" IFV_VFP
   SG_ CAN_DET_AZIMUTH_15_01 : 47|14@0+ (0.0003834,-3.1416) [-3.1416|3.13964] "rad" IFV_VFP
   SG_ CAN_DET_RANGE_15_01 : 31|14@0+ (0.015625,0) [0|255.984] "m" IFV_VFP
   SG_ CAN_DET_RANGE_RATE_15_01 : 15|14@0+ (0.015625,-128) [-128|127.984] "m/s" IFV_VFP
   SG_ CAN_DET_AMPLITUDE_15_01 : 7|7@0+ (1,-64) [-64|63] "dBsm" IFV_VFP
   SG_ CAN_SCAN_INDEX_2LSB_15_01 : 17|2@0+ (1,0) [0|3] "" IFV_VFP
   SG_ CAN_DET_CONFID_AZIMUTH_15_02 : 105|2@0+ (1,0) [0|3] "" IFV_VFP
   SG_ CAN_DET_SUPER_RES_TARGET_15_02 : 128|1@0+ (1,0) [0|1] "" IFV_VFP
   SG_ CAN_DET_NEW_SIGNAL_15_02 : 134|6@0+ (1,0) [0|64] "" IFV_VFP
   SG_ CAN_DET_ND_TARGET_15_02 : 120|1@0+ (1,0) [0|1] "" IFV_VFP
   SG_ CAN_DET_HOST_VEH_CLUTTER_15_02 : 121|1@0+ (1,0) [0|1] "" IFV_VFP
   SG_ CAN_DET_VALID_LEVEL_15_02 : 72|1@0+ (1,0) [0|1] "" IFV_VFP
   SG_ CAN_DET_AZIMUTH_15_02 : 119|14@0+ (0.0003834,-3.1416) [-3.1416|3.13964] "rad" IFV_VFP
   SG_ CAN_DET_RANGE_15_02 : 103|14@0+ (0.015625,0) [0|255.984] "m" IFV_VFP
   SG_ CAN_DET_RANGE_RATE_15_02 : 87|14@0+ (0.015625,-128) [-128|127.984] "m/s" IFV_VFP
   SG_ CAN_DET_AMPLITUDE_15_02 : 79|7@0+ (1,-64) [-64|63] "dBsm" IFV_VFP
   SG_ CAN_SCAN_INDEX_2LSB_15_02 : 89|2@0+ (1,0) [0|3] "" IFV_VFP
   SG_ CAN_DET_CONFID_AZIMUTH_15_03 : 177|2@0+ (1,0) [0|3] "" IFV_VFP
   SG_ CAN_DET_SUPER_RES_TARGET_15_03 : 200|1@0+ (1,0) [0|1] "" IFV_VFP
   SG_ CAN_DET_NEW_SIGNAL_15_03 : 206|6@0+ (1,0) [0|64] "" IFV_VFP
   SG_ CAN_DET_ND_TARGET_15_03 : 192|1@0+ (1,0) [0|1] "" IFV_VFP
   SG_ CAN_DET_HOST_VEH_CLUTTER_15_03 : 193|1@0+ (1,0) [0|1] "" IFV_VFP
   SG_ CAN_DET_VALID_LEVEL_15_03 : 144|1@0+ (1,0) [0|1] "" IFV_VFP
   SG_ CAN_DET_AZIMUTH_15_03 : 191|14@0+ (0.0003834,-3.1416) [-3.1416|3.13964] "rad" IFV_VFP
   SG_ CAN_DET_RANGE_15_03 : 175|14@0+ (0.015625,0) [0|255.984] "m" IFV_VFP
   SG_ CAN_DET_RANGE_RATE_15_03 : 159|14@0+ (0.015625,-128) [-128|127.984] "m/s" IFV_VFP
   SG_ CAN_DET_AMPLITUDE_15_03 : 151|7@0+ (1,-64) [-64|63] "dBsm" IFV_VFP
   SG_ CAN_SCAN_INDEX_2LSB_15_03 : 161|2@0+ (1,0) [0|3] "" IFV_VFP
   SG_ CAN_DET_CONFID_AZIMUTH_15_04 : 249|2@0+ (1,0) [0|3] "" IFV_VFP
   SG_ CAN_DET_SUPER_RES_TARGET_15_04 : 272|1@0+ (1,0) [0|1] "" IFV_VFP
   SG_ CAN_DET_NEW_SIGNAL_15_04 : 278|6@0+ (1,0) [0|64] "" IFV_VFP
   SG_ CAN_DET_ND_TARGET_15_04 : 264|1@0+ (1,0) [0|1] "" IFV_VFP
   SG_ CAN_DET_HOST_VEH_CLUTTER_15_04 : 265|1@0+ (1,0) [0|1] "" IFV_VFP
   SG_ CAN_DET_VALID_LEVEL_15_04 : 216|1@0+ (1,0) [0|1] "" IFV_VFP
   SG_ CAN_DET_AZIMUTH_15_04 : 263|14@0+ (0.0003834,-3.1416) [-3.1416|3.13964] "rad" IFV_VFP
   SG_ CAN_DET_RANGE_15_04 : 247|14@0+ (0.015625,0) [0|255.984] "m" IFV_VFP
   SG_ CAN_DET_RANGE_RATE_15_04 : 231|14@0+ (0.015625,-128) [-128|127.984] "m/s" IFV_VFP
   SG_ CAN_DET_AMPLITUDE_15_04 : 223|7@0+ (1,-64) [-64|63] "dBsm" IFV_VFP
   SG_ CAN_SCAN_INDEX_2LSB_15_04 : 233|2@0+ (1,0) [0|3] "" IFV_VFP
   SG_ CAN_DET_CONFID_AZIMUTH_15_05 : 321|2@0+ (1,0) [0|3] "" IFV_VFP
   SG_ CAN_DET_SUPER_RES_TARGET_15_05 : 344|1@0+ (1,0) [0|1] "" IFV_VFP
   SG_ CAN_DET_NEW_SIGNAL_15_05 : 350|6@0+ (1,0) [0|64] "" IFV_VFP
   SG_ CAN_DET_ND_TARGET_15_05 : 336|1@0+ (1,0) [0|1] "" IFV_VFP
   SG_ CAN_DET_HOST_VEH_CLUTTER_15_05 : 337|1@0+ (1,0) [0|1] "" IFV_VFP
   SG_ CAN_DET_VALID_LEVEL_15_05 : 288|1@0+ (1,0) [0|1] "" IFV_VFP
   SG_ CAN_DET_AZIMUTH_15_05 : 335|14@0+ (0.0003834,-3.1416) [-3.1416|3.13964] "rad" IFV_VFP
   SG_ CAN_DET_RANGE_15_05 : 319|14@0+ (0.015625,0) [0|255.984] "m" IFV_VFP
   SG_ CAN_DET_RANGE_RATE_15_05 : 303|14@0+ (0.015625,-128) [-128|127.984] "m/s" IFV_VFP
   SG_ CAN_DET_AMPLITUDE_15_05 : 295|7@0+ (1,-64) [-64|63] "dBsm" IFV_VFP
   SG_ CAN_SCAN_INDEX_2LSB_15_05 : 305|2@0+ (1,0) [0|3] "" IFV_VFP
   SG_ CAN_DET_CONFID_AZIMUTH_15_06 : 393|2@0+ (1,0) [0|3] "" IFV_VFP
   SG_ CAN_DET_SUPER_RES_TARGET_15_06 : 416|1@0+ (1,0) [0|1] "" IFV_VFP
   SG_ CAN_DET_NEW_SIGNAL_15_06 : 422|6@0+ (1,0) [0|64] "" IFV_VFP
   SG_ CAN_DET_ND_TARGET_15_06 : 408|1@0+ (1,0) [0|1] "" IFV_VFP
   SG_ CAN_DET_HOST_VEH_CLUTTER_15_06 : 409|1@0+ (1,0) [0|1] "" IFV_VFP
   SG_ CAN_DET_VALID_LEVEL_15_06 : 360|1@0+ (1,0) [0|1] "" IFV_VFP
   SG_ CAN_DET_AZIMUTH_15_06 : 407|14@0+ (0.0003834,-3.1416) [-3.1416|3.13964] "rad" IFV_VFP
   SG_ CAN_DET_RANGE_15_06 : 391|14@0+ (0.015625,0) [0|255.984] "m" IFV_VFP
   SG_ CAN_DET_RANGE_RATE_15_06 : 375|14@0+ (0.015625,-128) [-128|127.984] "m/s" IFV_VFP
   SG_ CAN_DET_AMPLITUDE_15_06 : 367|7@0+ (1,-64) [-64|63] "dBsm" IFV_VFP
   SG_ CAN_SCAN_INDEX_2LSB_15_06 : 377|2@0+ (1,0) [0|3] "" IFV_VFP

BO_ 301 MRR_Detection_014: 64 MRR
   SG_ CAN_DET_CONFID_AZIMUTH_14_01 : 33|2@0+ (1,0) [0|3] "" IFV_VFP
   SG_ CAN_DET_SUPER_RES_TARGET_14_01 : 56|1@0+ (1,0) [0|1] "" IFV_VFP
   SG_ CAN_DET_NEW_SIGNAL_14_01 : 62|6@0+ (1,0) [0|64] "" IFV_VFP
   SG_ CAN_DET_ND_TARGET_14_01 : 48|1@0+ (1,0) [0|1] "" IFV_VFP
   SG_ CAN_DET_HOST_VEH_CLUTTER_14_01 : 49|1@0+ (1,0) [0|1] "" IFV_VFP
   SG_ CAN_DET_VALID_LEVEL_14_01 : 0|1@0+ (1,0) [0|1] "" IFV_VFP
   SG_ CAN_DET_AZIMUTH_14_01 : 47|14@0+ (0.0003834,-3.1416) [-3.1416|3.13964] "rad" IFV_VFP
   SG_ CAN_DET_RANGE_14_01 : 31|14@0+ (0.015625,0) [0|255.984] "m" IFV_VFP
   SG_ CAN_DET_RANGE_RATE_14_01 : 15|14@0+ (0.015625,-128) [-128|127.984] "m/s" IFV_VFP
   SG_ CAN_DET_AMPLITUDE_14_01 : 7|7@0+ (1,-64) [-64|63] "dBsm" IFV_VFP
   SG_ CAN_SCAN_INDEX_2LSB_14_01 : 17|2@0+ (1,0) [0|3] "" IFV_VFP
   SG_ CAN_DET_CONFID_AZIMUTH_14_02 : 105|2@0+ (1,0) [0|3] "" IFV_VFP
   SG_ CAN_DET_SUPER_RES_TARGET_14_02 : 128|1@0+ (1,0) [0|1] "" IFV_VFP
   SG_ CAN_DET_NEW_SIGNAL_14_02 : 134|6@0+ (1,0) [0|64] "" IFV_VFP
   SG_ CAN_DET_ND_TARGET_14_02 : 120|1@0+ (1,0) [0|1] "" IFV_VFP
   SG_ CAN_DET_HOST_VEH_CLUTTER_14_02 : 121|1@0+ (1,0) [0|1] "" IFV_VFP
   SG_ CAN_DET_VALID_LEVEL_14_02 : 72|1@0+ (1,0) [0|1] "" IFV_VFP
   SG_ CAN_DET_AZIMUTH_14_02 : 119|14@0+ (0.0003834,-3.1416) [-3.1416|3.13964] "rad" IFV_VFP
   SG_ CAN_DET_RANGE_14_02 : 103|14@0+ (0.015625,0) [0|255.984] "m" IFV_VFP
   SG_ CAN_DET_RANGE_RATE_14_02 : 87|14@0+ (0.015625,-128) [-128|127.984] "m/s" IFV_VFP
   SG_ CAN_DET_AMPLITUDE_14_02 : 79|7@0+ (1,-64) [-64|63] "dBsm" IFV_VFP
   SG_ CAN_SCAN_INDEX_2LSB_14_02 : 89|2@0+ (1,0) [0|3] "" IFV_VFP
   SG_ CAN_DET_CONFID_AZIMUTH_14_03 : 177|2@0+ (1,0) [0|3] "" IFV_VFP
   SG_ CAN_DET_SUPER_RES_TARGET_14_03 : 200|1@0+ (1,0) [0|1] "" IFV_VFP
   SG_ CAN_DET_NEW_SIGNAL_14_03 : 206|6@0+ (1,0) [0|64] "" IFV_VFP
   SG_ CAN_DET_ND_TARGET_14_03 : 192|1@0+ (1,0) [0|1] "" IFV_VFP
   SG_ CAN_DET_HOST_VEH_CLUTTER_14_03 : 193|1@0+ (1,0) [0|1] "" IFV_VFP
   SG_ CAN_DET_VALID_LEVEL_14_03 : 144|1@0+ (1,0) [0|1] "" IFV_VFP
   SG_ CAN_DET_AZIMUTH_14_03 : 191|14@0+ (0.0003834,-3.1416) [-3.1416|3.13964] "rad" IFV_VFP
   SG_ CAN_DET_RANGE_14_03 : 175|14@0+ (0.015625,0) [0|255.984] "m" IFV_VFP
   SG_ CAN_DET_RANGE_RATE_14_03 : 159|14@0+ (0.015625,-128) [-128|127.984] "m/s" IFV_VFP
   SG_ CAN_DET_AMPLITUDE_14_03 : 151|7@0+ (1,-64) [-64|63] "dBsm" IFV_VFP
   SG_ CAN_SCAN_INDEX_2LSB_14_03 : 161|2@0+ (1,0) [0|3] "" IFV_VFP
   SG_ CAN_DET_CONFID_AZIMUTH_14_04 : 249|2@0+ (1,0) [0|3] "" IFV_VFP
   SG_ CAN_DET_SUPER_RES_TARGET_14_04 : 272|1@0+ (1,0) [0|1] "" IFV_VFP
   SG_ CAN_DET_NEW_SIGNAL_14_04 : 278|6@0+ (1,0) [0|64] "" IFV_VFP
   SG_ CAN_DET_ND_TARGET_14_04 : 264|1@0+ (1,0) [0|1] "" IFV_VFP
   SG_ CAN_DET_HOST_VEH_CLUTTER_14_04 : 265|1@0+ (1,0) [0|1] "" IFV_VFP
   SG_ CAN_DET_VALID_LEVEL_14_04 : 216|1@0+ (1,0) [0|1] "" IFV_VFP
   SG_ CAN_DET_AZIMUTH_14_04 : 263|14@0+ (0.0003834,-3.1416) [-3.1416|3.13964] "rad" IFV_VFP
   SG_ CAN_DET_RANGE_14_04 : 247|14@0+ (0.015625,0) [0|255.984] "m" IFV_VFP
   SG_ CAN_DET_RANGE_RATE_14_04 : 231|14@0+ (0.015625,-128) [-128|127.984] "m/s" IFV_VFP
   SG_ CAN_DET_AMPLITUDE_14_04 : 223|7@0+ (1,-64) [-64|63] "dBsm" IFV_VFP
   SG_ CAN_SCAN_INDEX_2LSB_14_04 : 233|2@0+ (1,0) [0|3] "" IFV_VFP
   SG_ CAN_DET_CONFID_AZIMUTH_14_05 : 321|2@0+ (1,0) [0|3] "" IFV_VFP
   SG_ CAN_DET_SUPER_RES_TARGET_14_05 : 344|1@0+ (1,0) [0|1] "" IFV_VFP
   SG_ CAN_DET_NEW_SIGNAL_14_05 : 350|6@0+ (1,0) [0|64] "" IFV_VFP
   SG_ CAN_DET_ND_TARGET_14_05 : 336|1@0+ (1,0) [0|1] "" IFV_VFP
   SG_ CAN_DET_HOST_VEH_CLUTTER_14_05 : 337|1@0+ (1,0) [0|1] "" IFV_VFP
   SG_ CAN_DET_VALID_LEVEL_14_05 : 288|1@0+ (1,0) [0|1] "" IFV_VFP
   SG_ CAN_DET_AZIMUTH_14_05 : 335|14@0+ (0.0003834,-3.1416) [-3.1416|3.13964] "rad" IFV_VFP
   SG_ CAN_DET_RANGE_14_05 : 319|14@0+ (0.015625,0) [0|255.984] "m" IFV_VFP
   SG_ CAN_DET_RANGE_RATE_14_05 : 303|14@0+ (0.015625,-128) [-128|127.984] "m/s" IFV_VFP
   SG_ CAN_DET_AMPLITUDE_14_05 : 295|7@0+ (1,-64) [-64|63] "dBsm" IFV_VFP
   SG_ CAN_SCAN_INDEX_2LSB_14_05 : 305|2@0+ (1,0) [0|3] "" IFV_VFP
   SG_ CAN_DET_CONFID_AZIMUTH_14_06 : 393|2@0+ (1,0) [0|3] "" IFV_VFP
   SG_ CAN_DET_SUPER_RES_TARGET_14_06 : 416|1@0+ (1,0) [0|1] "" IFV_VFP
   SG_ CAN_DET_NEW_SIGNAL_14_06 : 422|6@0+ (1,0) [0|64] "" IFV_VFP
   SG_ CAN_DET_ND_TARGET_14_06 : 408|1@0+ (1,0) [0|1] "" IFV_VFP
   SG_ CAN_DET_HOST_VEH_CLUTTER_14_06 : 409|1@0+ (1,0) [0|1] "" IFV_VFP
   SG_ CAN_DET_VALID_LEVEL_14_06 : 360|1@0+ (1,0) [0|1] "" IFV_VFP
   SG_ CAN_DET_AZIMUTH_14_06 : 407|14@0+ (0.0003834,-3.1416) [-3.1416|3.13964] "rad" IFV_VFP
   SG_ CAN_DET_RANGE_14_06 : 391|14@0+ (0.015625,0) [0|255.984] "m" IFV_VFP
   SG_ CAN_DET_RANGE_RATE_14_06 : 375|14@0+ (0.015625,-128) [-128|127.984] "m/s" IFV_VFP
   SG_ CAN_DET_AMPLITUDE_14_06 : 367|7@0+ (1,-64) [-64|63] "dBsm" IFV_VFP
   SG_ CAN_SCAN_INDEX_2LSB_14_06 : 377|2@0+ (1,0) [0|3] "" IFV_VFP

BO_ 300 MRR_Detection_013: 64 MRR
   SG_ CAN_DET_CONFID_AZIMUTH_13_01 : 33|2@0+ (1,0) [0|3] "" IFV_VFP
   SG_ CAN_DET_SUPER_RES_TARGET_13_01 : 56|1@0+ (1,0) [0|1] "" IFV_VFP
   SG_ CAN_DET_NEW_SIGNAL_13_01 : 62|6@0+ (1,0) [0|64] "" IFV_VFP
   SG_ CAN_DET_ND_TARGET_13_01 : 48|1@0+ (1,0) [0|1] "" IFV_VFP
   SG_ CAN_DET_HOST_VEH_CLUTTER_13_01 : 49|1@0+ (1,0) [0|1] "" IFV_VFP
   SG_ CAN_DET_VALID_LEVEL_13_01 : 0|1@0+ (1,0) [0|1] "" IFV_VFP
   SG_ CAN_DET_AZIMUTH_13_01 : 47|14@0+ (0.0003834,-3.1416) [-3.1416|3.13964] "rad" IFV_VFP
   SG_ CAN_DET_RANGE_13_01 : 31|14@0+ (0.015625,0) [0|255.984] "m" IFV_VFP
   SG_ CAN_DET_RANGE_RATE_13_01 : 15|14@0+ (0.015625,-128) [-128|127.984] "m/s" IFV_VFP
   SG_ CAN_DET_AMPLITUDE_13_01 : 7|7@0+ (1,-64) [-64|63] "dBsm" IFV_VFP
   SG_ CAN_SCAN_INDEX_2LSB_13_01 : 17|2@0+ (1,0) [0|3] "" IFV_VFP
   SG_ CAN_DET_CONFID_AZIMUTH_13_02 : 105|2@0+ (1,0) [0|3] "" IFV_VFP
   SG_ CAN_DET_SUPER_RES_TARGET_13_02 : 128|1@0+ (1,0) [0|1] "" IFV_VFP
   SG_ CAN_DET_NEW_SIGNAL_13_02 : 134|6@0+ (1,0) [0|64] "" IFV_VFP
   SG_ CAN_DET_ND_TARGET_13_02 : 120|1@0+ (1,0) [0|1] "" IFV_VFP
   SG_ CAN_DET_HOST_VEH_CLUTTER_13_02 : 121|1@0+ (1,0) [0|1] "" IFV_VFP
   SG_ CAN_DET_VALID_LEVEL_13_02 : 72|1@0+ (1,0) [0|1] "" IFV_VFP
   SG_ CAN_DET_AZIMUTH_13_02 : 119|14@0+ (0.0003834,-3.1416) [-3.1416|3.13964] "rad" IFV_VFP
   SG_ CAN_DET_RANGE_13_02 : 103|14@0+ (0.015625,0) [0|255.984] "m" IFV_VFP
   SG_ CAN_DET_RANGE_RATE_13_02 : 87|14@0+ (0.015625,-128) [-128|127.984] "m/s" IFV_VFP
   SG_ CAN_DET_AMPLITUDE_13_02 : 79|7@0+ (1,-64) [-64|63] "dBsm" IFV_VFP
   SG_ CAN_SCAN_INDEX_2LSB_13_02 : 89|2@0+ (1,0) [0|3] "" IFV_VFP
   SG_ CAN_DET_CONFID_AZIMUTH_13_03 : 177|2@0+ (1,0) [0|3] "" IFV_VFP
   SG_ CAN_DET_SUPER_RES_TARGET_13_03 : 200|1@0+ (1,0) [0|1] "" IFV_VFP
   SG_ CAN_DET_NEW_SIGNAL_13_03 : 206|6@0+ (1,0) [0|64] "" IFV_VFP
   SG_ CAN_DET_ND_TARGET_13_03 : 192|1@0+ (1,0) [0|1] "" IFV_VFP
   SG_ CAN_DET_HOST_VEH_CLUTTER_13_03 : 193|1@0+ (1,0) [0|1] "" IFV_VFP
   SG_ CAN_DET_VALID_LEVEL_13_03 : 144|1@0+ (1,0) [0|1] "" IFV_VFP
   SG_ CAN_DET_AZIMUTH_13_03 : 191|14@0+ (0.0003834,-3.1416) [-3.1416|3.13964] "rad" IFV_VFP
   SG_ CAN_DET_RANGE_13_03 : 175|14@0+ (0.015625,0) [0|255.984] "m" IFV_VFP
   SG_ CAN_DET_RANGE_RATE_13_03 : 159|14@0+ (0.015625,-128) [-128|127.984] "m/s" IFV_VFP
   SG_ CAN_DET_AMPLITUDE_13_03 : 151|7@0+ (1,-64) [-64|63] "dBsm" IFV_VFP
   SG_ CAN_SCAN_INDEX_2LSB_13_03 : 161|2@0+ (1,0) [0|3] "" IFV_VFP
   SG_ CAN_DET_CONFID_AZIMUTH_13_04 : 249|2@0+ (1,0) [0|3] "" IFV_VFP
   SG_ CAN_DET_SUPER_RES_TARGET_13_04 : 272|1@0+ (1,0) [0|1] "" IFV_VFP
   SG_ CAN_DET_NEW_SIGNAL_13_04 : 278|6@0+ (1,0) [0|64] "" IFV_VFP
   SG_ CAN_DET_ND_TARGET_13_04 : 264|1@0+ (1,0) [0|1] "" IFV_VFP
   SG_ CAN_DET_HOST_VEH_CLUTTER_13_04 : 265|1@0+ (1,0) [0|1] "" IFV_VFP
   SG_ CAN_DET_VALID_LEVEL_13_04 : 216|1@0+ (1,0) [0|1] "" IFV_VFP
   SG_ CAN_DET_AZIMUTH_13_04 : 263|14@0+ (0.0003834,-3.1416) [-3.1416|3.13964] "rad" IFV_VFP
   SG_ CAN_DET_RANGE_13_04 : 247|14@0+ (0.015625,0) [0|255.984] "m" IFV_VFP
   SG_ CAN_DET_RANGE_RATE_13_04 : 231|14@0+ (0.015625,-128) [-128|127.984] "m/s" IFV_VFP
   SG_ CAN_DET_AMPLITUDE_13_04 : 223|7@0+ (1,-64) [-64|63] "dBsm" IFV_VFP
   SG_ CAN_SCAN_INDEX_2LSB_13_04 : 233|2@0+ (1,0) [0|3] "" IFV_VFP
   SG_ CAN_DET_CONFID_AZIMUTH_13_05 : 321|2@0+ (1,0) [0|3] "" IFV_VFP
   SG_ CAN_DET_SUPER_RES_TARGET_13_05 : 344|1@0+ (1,0) [0|1] "" IFV_VFP
   SG_ CAN_DET_NEW_SIGNAL_13_05 : 350|6@0+ (1,0) [0|64] "" IFV_VFP
   SG_ CAN_DET_ND_TARGET_13_05 : 336|1@0+ (1,0) [0|1] "" IFV_VFP
   SG_ CAN_DET_HOST_VEH_CLUTTER_13_05 : 337|1@0+ (1,0) [0|1] "" IFV_VFP
   SG_ CAN_DET_VALID_LEVEL_13_05 : 288|1@0+ (1,0) [0|1] "" IFV_VFP
   SG_ CAN_DET_AZIMUTH_13_05 : 335|14@0+ (0.0003834,-3.1416) [-3.1416|3.13964] "rad" IFV_VFP
   SG_ CAN_DET_RANGE_13_05 : 319|14@0+ (0.015625,0) [0|255.984] "m" IFV_VFP
   SG_ CAN_DET_RANGE_RATE_13_05 : 303|14@0+ (0.015625,-128) [-128|127.984] "m/s" IFV_VFP
   SG_ CAN_DET_AMPLITUDE_13_05 : 295|7@0+ (1,-64) [-64|63] "dBsm" IFV_VFP
   SG_ CAN_SCAN_INDEX_2LSB_13_05 : 305|2@0+ (1,0) [0|3] "" IFV_VFP
   SG_ CAN_DET_CONFID_AZIMUTH_13_06 : 393|2@0+ (1,0) [0|3] "" IFV_VFP
   SG_ CAN_DET_SUPER_RES_TARGET_13_06 : 416|1@0+ (1,0) [0|1] "" IFV_VFP
   SG_ CAN_DET_NEW_SIGNAL_13_06 : 422|6@0+ (1,0) [0|64] "" IFV_VFP
   SG_ CAN_DET_ND_TARGET_13_06 : 408|1@0+ (1,0) [0|1] "" IFV_VFP
   SG_ CAN_DET_HOST_VEH_CLUTTER_13_06 : 409|1@0+ (1,0) [0|1] "" IFV_VFP
   SG_ CAN_DET_VALID_LEVEL_13_06 : 360|1@0+ (1,0) [0|1] "" IFV_VFP
   SG_ CAN_DET_AZIMUTH_13_06 : 407|14@0+ (0.0003834,-3.1416) [-3.1416|3.13964] "rad" IFV_VFP
   SG_ CAN_DET_RANGE_13_06 : 391|14@0+ (0.015625,0) [0|255.984] "m" IFV_VFP
   SG_ CAN_DET_RANGE_RATE_13_06 : 375|14@0+ (0.015625,-128) [-128|127.984] "m/s" IFV_VFP
   SG_ CAN_DET_AMPLITUDE_13_06 : 367|7@0+ (1,-64) [-64|63] "dBsm" IFV_VFP
   SG_ CAN_SCAN_INDEX_2LSB_13_06 : 377|2@0+ (1,0) [0|3] "" IFV_VFP

BO_ 299 MRR_Detection_012: 64 MRR
   SG_ CAN_DET_CONFID_AZIMUTH_12_01 : 33|2@0+ (1,0) [0|3] "" IFV_VFP
   SG_ CAN_DET_SUPER_RES_TARGET_12_01 : 56|1@0+ (1,0) [0|1] "" IFV_VFP
   SG_ CAN_DET_NEW_SIGNAL_12_01 : 62|6@0+ (1,0) [0|64] "" IFV_VFP
   SG_ CAN_DET_ND_TARGET_12_01 : 48|1@0+ (1,0) [0|1] "" IFV_VFP
   SG_ CAN_DET_HOST_VEH_CLUTTER_12_01 : 49|1@0+ (1,0) [0|1] "" IFV_VFP
   SG_ CAN_DET_VALID_LEVEL_12_01 : 0|1@0+ (1,0) [0|1] "" IFV_VFP
   SG_ CAN_DET_AZIMUTH_12_01 : 47|14@0+ (0.0003834,-3.1416) [-3.1416|3.13964] "rad" IFV_VFP
   SG_ CAN_DET_RANGE_12_01 : 31|14@0+ (0.015625,0) [0|255.984] "m" IFV_VFP
   SG_ CAN_DET_RANGE_RATE_12_01 : 15|14@0+ (0.015625,-128) [-128|127.984] "m/s" IFV_VFP
   SG_ CAN_DET_AMPLITUDE_12_01 : 7|7@0+ (1,-64) [-64|63] "dBsm" IFV_VFP
   SG_ CAN_SCAN_INDEX_2LSB_12_01 : 17|2@0+ (1,0) [0|3] "" IFV_VFP
   SG_ CAN_DET_CONFID_AZIMUTH_12_02 : 105|2@0+ (1,0) [0|3] "" IFV_VFP
   SG_ CAN_DET_SUPER_RES_TARGET_12_02 : 128|1@0+ (1,0) [0|1] "" IFV_VFP
   SG_ CAN_DET_NEW_SIGNAL_12_02 : 134|6@0+ (1,0) [0|64] "" IFV_VFP
   SG_ CAN_DET_ND_TARGET_12_02 : 120|1@0+ (1,0) [0|1] "" IFV_VFP
   SG_ CAN_DET_HOST_VEH_CLUTTER_12_02 : 121|1@0+ (1,0) [0|1] "" IFV_VFP
   SG_ CAN_DET_VALID_LEVEL_12_02 : 72|1@0+ (1,0) [0|1] "" IFV_VFP
   SG_ CAN_DET_AZIMUTH_12_02 : 119|14@0+ (0.0003834,-3.1416) [-3.1416|3.13964] "rad" IFV_VFP
   SG_ CAN_DET_RANGE_12_02 : 103|14@0+ (0.015625,0) [0|255.984] "m" IFV_VFP
   SG_ CAN_DET_RANGE_RATE_12_02 : 87|14@0+ (0.015625,-128) [-128|127.984] "m/s" IFV_VFP
   SG_ CAN_DET_AMPLITUDE_12_02 : 79|7@0+ (1,-64) [-64|63] "dBsm" IFV_VFP
   SG_ CAN_SCAN_INDEX_2LSB_12_02 : 89|2@0+ (1,0) [0|3] "" IFV_VFP
   SG_ CAN_DET_CONFID_AZIMUTH_12_03 : 177|2@0+ (1,0) [0|3] "" IFV_VFP
   SG_ CAN_DET_SUPER_RES_TARGET_12_03 : 200|1@0+ (1,0) [0|1] "" IFV_VFP
   SG_ CAN_DET_NEW_SIGNAL_12_03 : 206|6@0+ (1,0) [0|64] "" IFV_VFP
   SG_ CAN_DET_ND_TARGET_12_03 : 192|1@0+ (1,0) [0|1] "" IFV_VFP
   SG_ CAN_DET_HOST_VEH_CLUTTER_12_03 : 193|1@0+ (1,0) [0|1] "" IFV_VFP
   SG_ CAN_DET_VALID_LEVEL_12_03 : 144|1@0+ (1,0) [0|1] "" IFV_VFP
   SG_ CAN_DET_AZIMUTH_12_03 : 191|14@0+ (0.0003834,-3.1416) [-3.1416|3.13964] "rad" IFV_VFP
   SG_ CAN_DET_RANGE_12_03 : 175|14@0+ (0.015625,0) [0|255.984] "m" IFV_VFP
   SG_ CAN_DET_RANGE_RATE_12_03 : 159|14@0+ (0.015625,-128) [-128|127.984] "m/s" IFV_VFP
   SG_ CAN_DET_AMPLITUDE_12_03 : 151|7@0+ (1,-64) [-64|63] "dBsm" IFV_VFP
   SG_ CAN_SCAN_INDEX_2LSB_12_03 : 161|2@0+ (1,0) [0|3] "" IFV_VFP
   SG_ CAN_DET_CONFID_AZIMUTH_12_04 : 249|2@0+ (1,0) [0|3] "" IFV_VFP
   SG_ CAN_DET_SUPER_RES_TARGET_12_04 : 272|1@0+ (1,0) [0|1] "" IFV_VFP
   SG_ CAN_DET_NEW_SIGNAL_12_04 : 278|6@0+ (1,0) [0|64] "" IFV_VFP
   SG_ CAN_DET_ND_TARGET_12_04 : 264|1@0+ (1,0) [0|1] "" IFV_VFP
   SG_ CAN_DET_HOST_VEH_CLUTTER_12_04 : 265|1@0+ (1,0) [0|1] "" IFV_VFP
   SG_ CAN_DET_VALID_LEVEL_12_04 : 216|1@0+ (1,0) [0|1] "" IFV_VFP
   SG_ CAN_DET_AZIMUTH_12_04 : 263|14@0+ (0.0003834,-3.1416) [-3.1416|3.13964] "rad" IFV_VFP
   SG_ CAN_DET_RANGE_12_04 : 247|14@0+ (0.015625,0) [0|255.984] "m" IFV_VFP
   SG_ CAN_DET_RANGE_RATE_12_04 : 231|14@0+ (0.015625,-128) [-128|127.984] "m/s" IFV_VFP
   SG_ CAN_DET_AMPLITUDE_12_04 : 223|7@0+ (1,-64) [-64|63] "dBsm" IFV_VFP
   SG_ CAN_SCAN_INDEX_2LSB_12_04 : 233|2@0+ (1,0) [0|3] "" IFV_VFP
   SG_ CAN_DET_CONFID_AZIMUTH_12_05 : 321|2@0+ (1,0) [0|3] "" IFV_VFP
   SG_ CAN_DET_SUPER_RES_TARGET_12_05 : 344|1@0+ (1,0) [0|1] "" IFV_VFP
   SG_ CAN_DET_NEW_SIGNAL_12_05 : 350|6@0+ (1,0) [0|64] "" IFV_VFP
   SG_ CAN_DET_ND_TARGET_12_05 : 336|1@0+ (1,0) [0|1] "" IFV_VFP
   SG_ CAN_DET_HOST_VEH_CLUTTER_12_05 : 337|1@0+ (1,0) [0|1] "" IFV_VFP
   SG_ CAN_DET_VALID_LEVEL_12_05 : 288|1@0+ (1,0) [0|1] "" IFV_VFP
   SG_ CAN_DET_AZIMUTH_12_05 : 335|14@0+ (0.0003834,-3.1416) [-3.1416|3.13964] "rad" IFV_VFP
   SG_ CAN_DET_RANGE_12_05 : 319|14@0+ (0.015625,0) [0|255.984] "m" IFV_VFP
   SG_ CAN_DET_RANGE_RATE_12_05 : 303|14@0+ (0.015625,-128) [-128|127.984] "m/s" IFV_VFP
   SG_ CAN_DET_AMPLITUDE_12_05 : 295|7@0+ (1,-64) [-64|63] "dBsm" IFV_VFP
   SG_ CAN_SCAN_INDEX_2LSB_12_05 : 305|2@0+ (1,0) [0|3] "" IFV_VFP
   SG_ CAN_DET_CONFID_AZIMUTH_12_06 : 393|2@0+ (1,0) [0|3] "" IFV_VFP
   SG_ CAN_DET_SUPER_RES_TARGET_12_06 : 416|1@0+ (1,0) [0|1] "" IFV_VFP
   SG_ CAN_DET_NEW_SIGNAL_12_06 : 422|6@0+ (1,0) [0|64] "" IFV_VFP
   SG_ CAN_DET_ND_TARGET_12_06 : 408|1@0+ (1,0) [0|1] "" IFV_VFP
   SG_ CAN_DET_HOST_VEH_CLUTTER_12_06 : 409|1@0+ (1,0) [0|1] "" IFV_VFP
   SG_ CAN_DET_VALID_LEVEL_12_06 : 360|1@0+ (1,0) [0|1] "" IFV_VFP
   SG_ CAN_DET_AZIMUTH_12_06 : 407|14@0+ (0.0003834,-3.1416) [-3.1416|3.13964] "rad" IFV_VFP
   SG_ CAN_DET_RANGE_12_06 : 391|14@0+ (0.015625,0) [0|255.984] "m" IFV_VFP
   SG_ CAN_DET_RANGE_RATE_12_06 : 375|14@0+ (0.015625,-128) [-128|127.984] "m/s" IFV_VFP
   SG_ CAN_DET_AMPLITUDE_12_06 : 367|7@0+ (1,-64) [-64|63] "dBsm" IFV_VFP
   SG_ CAN_SCAN_INDEX_2LSB_12_06 : 377|2@0+ (1,0) [0|3] "" IFV_VFP

BA_DEF_ SG_ "UsedOnPgmDBC" ENUM "No","Yes","No","Yes","No","Yes";
BA_DEF_ BO_ "DiagResponse" ENUM "No","Yes","No","Yes","No","Yes","No","Yes","No","Yes","No","Yes";
BA_DEF_ BO_ "EventRateOfChange" INT 10 10000;
BA_DEF_ SG_ "GenSigVtName" STRING ;
BA_DEF_ SG_ "GenSigVtEn" STRING ;
BA_DEF_ SG_ "GenSigCmt" STRING ;
BA_DEF_ SG_ "GenSigSendType" ENUM "No","Yes","No","Yes","No","Yes","No","Yes","No","Yes","No","Yes","No","Yes","No","Yes","No","Yes","No","Yes","No","Yes","Cyclic","OnWrite","vector_leerstring","OnChange","vector_leerstring","IfActive","vector_leerstring","NoSigSendType";
BA_DEF_ SG_ "GenSigStartValue" INT 0 1e+09;
BA_DEF_ BO_ "GenMsgILSupport" ENUM "No","Yes","No","Yes","No","Yes","No","Yes","No","Yes","No","Yes","No","Yes","No","Yes","No","Yes","No","Yes","No","Yes","Cyclic","OnWrite","vector_leerstring","OnChange","vector_leerstring","IfActive","vector_leerstring","NoSigSendType","No","Yes","No","Yes";
BA_DEF_ BO_ "GenMsgSendType" ENUM "No","Yes","No","Yes","No","Yes","No","Yes","No","Yes","No","Yes","No","Yes","No","Yes","No","Yes","No","Yes","No","Yes","Cyclic","OnWrite","vector_leerstring","OnChange","vector_leerstring","IfActive","vector_leerstring","NoSigSendType","No","Yes","No","Yes","No","Yes","FixedPeriodic","Event","EnabledPeriodic","NotUsed","NotUsed","EventPeriodic","NotUsed","NotUsed","NoMsgSendType";
BA_DEF_ BO_ "GenMsgCycleTime" INT 0 100000;
BA_DEF_ BO_ "GenMsgDelayTime" INT 0 1000;
BA_DEF_ BO_ "GenMsgNrOfRepetition" INT 0 100;
BA_DEF_ BO_ "NetworkInitialization" ENUM "No","Yes","No","Yes","No","Yes","No","Yes","No","Yes","No","Yes","No","Yes","No","Yes","No","Yes","No","Yes","No","Yes","Cyclic","OnWrite","vector_leerstring","OnChange","vector_leerstring","IfActive","vector_leerstring","NoSigSendType","No","Yes","No","Yes","No","Yes","FixedPeriodic","Event","EnabledPeriodic","NotUsed","NotUsed","EventPeriodic","NotUsed","NotUsed","NoMsgSendType","No","Yes";
BA_DEF_ BO_ "GenMsgBackgroundColor" STRING ;
BA_DEF_ BO_ "GenMsgForegroundColor" STRING ;
BA_ "GenMsgSendType" BO_ 307 1;
BA_ "GenSigVtEn" SG_ 307 CAN_DET_CONFID_AZIMUTH_20_01 "CAN_DET_CONFID_AZIMUTH_20_01";
BA_ "GenSigVtName" SG_ 307 CAN_DET_CONFID_AZIMUTH_20_01 "CAN_DET_CONFID_AZIMUTH_20_01";
BA_ "GenSigSendType" SG_ 307 CAN_DET_CONFID_AZIMUTH_20_01 0;
BA_ "GenSigCmt" SG_ 307 CAN_DET_CONFID_AZIMUTH_20_01 "CAN_DET_CONFID_AZIMUTH_20_01";
BA_ "GenSigSendType" SG_ 307 CAN_DET_SUPER_RES_TARGET_20_01 0;
BA_ "GenSigCmt" SG_ 307 CAN_DET_SUPER_RES_TARGET_20_01 "CAN_DET_SUPER_RES_TARGET_20_01";
BA_ "GenSigSendType" SG_ 307 CAN_DET_ND_TARGET_20_01 0;
BA_ "GenSigCmt" SG_ 307 CAN_DET_ND_TARGET_20_01 "CAN_DET_ND_TARGET_20_01";
BA_ "GenSigSendType" SG_ 307 CAN_DET_HOST_VEH_CLUTTER_20_01 0;
BA_ "GenSigCmt" SG_ 307 CAN_DET_HOST_VEH_CLUTTER_20_01 "CAN_DET_HOST_VEH_CLUTTER_20_01";
BA_ "GenSigSendType" SG_ 307 CAN_DET_VALID_LEVEL_20_01 0;
BA_ "GenSigCmt" SG_ 307 CAN_DET_VALID_LEVEL_20_01 "CAN_DET_VALID_LEVEL_20_01";
BA_ "GenSigSendType" SG_ 307 CAN_DET_AZIMUTH_20_01 0;
BA_ "GenSigCmt" SG_ 307 CAN_DET_AZIMUTH_20_01 "CAN_DET_AZIMUTH_20_01";
BA_ "GenSigSendType" SG_ 307 CAN_DET_RANGE_20_01 0;
BA_ "GenSigCmt" SG_ 307 CAN_DET_RANGE_20_01 "CAN_DET_RANGE_20_01";
BA_ "GenSigSendType" SG_ 307 CAN_DET_RANGE_RATE_20_01 0;
BA_ "GenSigCmt" SG_ 307 CAN_DET_RANGE_RATE_20_01 "CAN_DET_RANGE_RATE_20_01";
BA_ "GenSigSendType" SG_ 307 CAN_DET_AMPLITUDE_20_01 0;
BA_ "GenSigCmt" SG_ 307 CAN_DET_AMPLITUDE_20_01 "CAN_DET_AMPLITUDE_20_01";
BA_ "GenSigSendType" SG_ 307 CAN_SCAN_INDEX_2LSB_20_01 0;
BA_ "GenSigCmt" SG_ 307 CAN_SCAN_INDEX_2LSB_20_01 "CAN_SCAN_INDEX_2LSB_20_01";
BA_ "GenSigVtEn" SG_ 307 CAN_DET_CONFID_AZIMUTH_20_02 "CAN_DET_CONFID_AZIMUTH_20_02";
BA_ "GenSigVtName" SG_ 307 CAN_DET_CONFID_AZIMUTH_20_02 "CAN_DET_CONFID_AZIMUTH_20_02";
BA_ "GenSigSendType" SG_ 307 CAN_DET_CONFID_AZIMUTH_20_02 0;
BA_ "GenSigCmt" SG_ 307 CAN_DET_CONFID_AZIMUTH_20_02 "CAN_DET_CONFID_AZIMUTH_20_02";
BA_ "GenSigSendType" SG_ 307 CAN_DET_SUPER_RES_TARGET_20_02 0;
BA_ "GenSigCmt" SG_ 307 CAN_DET_SUPER_RES_TARGET_20_02 "CAN_DET_SUPER_RES_TARGET_20_02";
BA_ "GenSigSendType" SG_ 307 CAN_DET_ND_TARGET_20_02 0;
BA_ "GenSigCmt" SG_ 307 CAN_DET_ND_TARGET_20_02 "CAN_DET_ND_TARGET_20_02";
BA_ "GenSigSendType" SG_ 307 CAN_DET_HOST_VEH_CLUTTER_20_02 0;
BA_ "GenSigCmt" SG_ 307 CAN_DET_HOST_VEH_CLUTTER_20_02 "CAN_DET_HOST_VEH_CLUTTER_20_02";
BA_ "GenSigSendType" SG_ 307 CAN_DET_VALID_LEVEL_20_02 0;
BA_ "GenSigCmt" SG_ 307 CAN_DET_VALID_LEVEL_20_02 "CAN_DET_VALID_LEVEL_20_02";
BA_ "GenSigSendType" SG_ 307 CAN_DET_AZIMUTH_20_02 0;
BA_ "GenSigCmt" SG_ 307 CAN_DET_AZIMUTH_20_02 "CAN_DET_AZIMUTH_20_02";
BA_ "GenSigSendType" SG_ 307 CAN_DET_RANGE_20_02 0;
BA_ "GenSigCmt" SG_ 307 CAN_DET_RANGE_20_02 "CAN_DET_RANGE_20_02";
BA_ "GenSigSendType" SG_ 307 CAN_DET_RANGE_RATE_20_02 0;
BA_ "GenSigCmt" SG_ 307 CAN_DET_RANGE_RATE_20_02 "CAN_DET_RANGE_RATE_20_02";
BA_ "GenSigSendType" SG_ 307 CAN_DET_AMPLITUDE_20_02 0;
BA_ "GenSigCmt" SG_ 307 CAN_DET_AMPLITUDE_20_02 "CAN_DET_AMPLITUDE_20_02";
BA_ "GenSigSendType" SG_ 307 CAN_SCAN_INDEX_2LSB_20_02 0;
BA_ "GenSigCmt" SG_ 307 CAN_SCAN_INDEX_2LSB_20_02 "CAN_SCAN_INDEX_2LSB_20_02";
BA_ "GenSigVtEn" SG_ 307 CAN_DET_CONFID_AZIMUTH_20_03 "CAN_DET_CONFID_AZIMUTH_20_03";
BA_ "GenSigVtName" SG_ 307 CAN_DET_CONFID_AZIMUTH_20_03 "CAN_DET_CONFID_AZIMUTH_20_03";
BA_ "GenSigSendType" SG_ 307 CAN_DET_CONFID_AZIMUTH_20_03 0;
BA_ "GenSigCmt" SG_ 307 CAN_DET_CONFID_AZIMUTH_20_03 "CAN_DET_CONFID_AZIMUTH_20_03";
BA_ "GenSigSendType" SG_ 307 CAN_DET_SUPER_RES_TARGET_20_03 0;
BA_ "GenSigCmt" SG_ 307 CAN_DET_SUPER_RES_TARGET_20_03 "CAN_DET_SUPER_RES_TARGET_20_03";
BA_ "GenSigSendType" SG_ 307 CAN_DET_ND_TARGET_20_03 0;
BA_ "GenSigCmt" SG_ 307 CAN_DET_ND_TARGET_20_03 "CAN_DET_ND_TARGET_20_03";
BA_ "GenSigSendType" SG_ 307 CAN_DET_HOST_VEH_CLUTTER_20_03 0;
BA_ "GenSigCmt" SG_ 307 CAN_DET_HOST_VEH_CLUTTER_20_03 "CAN_DET_HOST_VEH_CLUTTER_20_03";
BA_ "GenSigSendType" SG_ 307 CAN_DET_VALID_LEVEL_20_03 0;
BA_ "GenSigCmt" SG_ 307 CAN_DET_VALID_LEVEL_20_03 "CAN_DET_VALID_LEVEL_20_03";
BA_ "GenSigSendType" SG_ 307 CAN_DET_AZIMUTH_20_03 0;
BA_ "GenSigCmt" SG_ 307 CAN_DET_AZIMUTH_20_03 "CAN_DET_AZIMUTH_20_03";
BA_ "GenSigSendType" SG_ 307 CAN_DET_RANGE_20_03 0;
BA_ "GenSigCmt" SG_ 307 CAN_DET_RANGE_20_03 "CAN_DET_RANGE_20_03";
BA_ "GenSigSendType" SG_ 307 CAN_DET_RANGE_RATE_20_03 0;
BA_ "GenSigCmt" SG_ 307 CAN_DET_RANGE_RATE_20_03 "CAN_DET_RANGE_RATE_20_03";
BA_ "GenSigSendType" SG_ 307 CAN_DET_AMPLITUDE_20_03 0;
BA_ "GenSigCmt" SG_ 307 CAN_DET_AMPLITUDE_20_03 "CAN_DET_AMPLITUDE_20_03";
BA_ "GenSigSendType" SG_ 307 CAN_SCAN_INDEX_2LSB_20_03 0;
BA_ "GenSigCmt" SG_ 307 CAN_SCAN_INDEX_2LSB_20_03 "CAN_SCAN_INDEX_2LSB_20_03";
BA_ "GenSigVtEn" SG_ 307 CAN_DET_CONFID_AZIMUTH_20_04 "CAN_DET_CONFID_AZIMUTH_20_04";
BA_ "GenSigVtName" SG_ 307 CAN_DET_CONFID_AZIMUTH_20_04 "CAN_DET_CONFID_AZIMUTH_20_04";
BA_ "GenSigSendType" SG_ 307 CAN_DET_CONFID_AZIMUTH_20_04 0;
BA_ "GenSigCmt" SG_ 307 CAN_DET_CONFID_AZIMUTH_20_04 "CAN_DET_CONFID_AZIMUTH_20_04";
BA_ "GenSigSendType" SG_ 307 CAN_DET_SUPER_RES_TARGET_20_04 0;
BA_ "GenSigCmt" SG_ 307 CAN_DET_SUPER_RES_TARGET_20_04 "CAN_DET_SUPER_RES_TARGET_20_04";
BA_ "GenSigSendType" SG_ 307 CAN_DET_ND_TARGET_20_04 0;
BA_ "GenSigCmt" SG_ 307 CAN_DET_ND_TARGET_20_04 "CAN_DET_ND_TARGET_20_04";
BA_ "GenSigSendType" SG_ 307 CAN_DET_HOST_VEH_CLUTTER_20_04 0;
BA_ "GenSigCmt" SG_ 307 CAN_DET_HOST_VEH_CLUTTER_20_04 "CAN_DET_HOST_VEH_CLUTTER_20_04";
BA_ "GenSigSendType" SG_ 307 CAN_DET_VALID_LEVEL_20_04 0;
BA_ "GenSigCmt" SG_ 307 CAN_DET_VALID_LEVEL_20_04 "CAN_DET_VALID_LEVEL_20_04";
BA_ "GenSigSendType" SG_ 307 CAN_DET_AZIMUTH_20_04 0;
BA_ "GenSigCmt" SG_ 307 CAN_DET_AZIMUTH_20_04 "CAN_DET_AZIMUTH_20_04";
BA_ "GenSigSendType" SG_ 307 CAN_DET_RANGE_20_04 0;
BA_ "GenSigCmt" SG_ 307 CAN_DET_RANGE_20_04 "CAN_DET_RANGE_20_04";
BA_ "GenSigSendType" SG_ 307 CAN_DET_RANGE_RATE_20_04 0;
BA_ "GenSigCmt" SG_ 307 CAN_DET_RANGE_RATE_20_04 "CAN_DET_RANGE_RATE_20_04";
BA_ "GenSigSendType" SG_ 307 CAN_DET_AMPLITUDE_20_04 0;
BA_ "GenSigCmt" SG_ 307 CAN_DET_AMPLITUDE_20_04 "CAN_DET_AMPLITUDE_20_04";
BA_ "GenSigSendType" SG_ 307 CAN_SCAN_INDEX_2LSB_20_04 0;
BA_ "GenSigCmt" SG_ 307 CAN_SCAN_INDEX_2LSB_20_04 "CAN_SCAN_INDEX_2LSB_20_04";
BA_ "GenSigVtEn" SG_ 307 CAN_DET_CONFID_AZIMUTH_20_05 "CAN_DET_CONFID_AZIMUTH_20_05";
BA_ "GenSigVtName" SG_ 307 CAN_DET_CONFID_AZIMUTH_20_05 "CAN_DET_CONFID_AZIMUTH_20_05";
BA_ "GenSigSendType" SG_ 307 CAN_DET_CONFID_AZIMUTH_20_05 0;
BA_ "GenSigCmt" SG_ 307 CAN_DET_CONFID_AZIMUTH_20_05 "CAN_DET_CONFID_AZIMUTH_20_05";
BA_ "GenSigSendType" SG_ 307 CAN_DET_SUPER_RES_TARGET_20_05 0;
BA_ "GenSigCmt" SG_ 307 CAN_DET_SUPER_RES_TARGET_20_05 "CAN_DET_SUPER_RES_TARGET_20_05";
BA_ "GenSigSendType" SG_ 307 CAN_DET_ND_TARGET_20_05 0;
BA_ "GenSigCmt" SG_ 307 CAN_DET_ND_TARGET_20_05 "CAN_DET_ND_TARGET_20_05";
BA_ "GenSigSendType" SG_ 307 CAN_DET_HOST_VEH_CLUTTER_20_05 0;
BA_ "GenSigCmt" SG_ 307 CAN_DET_HOST_VEH_CLUTTER_20_05 "CAN_DET_HOST_VEH_CLUTTER_20_05";
BA_ "GenSigSendType" SG_ 307 CAN_DET_VALID_LEVEL_20_05 0;
BA_ "GenSigCmt" SG_ 307 CAN_DET_VALID_LEVEL_20_05 "CAN_DET_VALID_LEVEL_20_05";
BA_ "GenSigSendType" SG_ 307 CAN_DET_AZIMUTH_20_05 0;
BA_ "GenSigCmt" SG_ 307 CAN_DET_AZIMUTH_20_05 "CAN_DET_AZIMUTH_20_05";
BA_ "GenSigSendType" SG_ 307 CAN_DET_RANGE_20_05 0;
BA_ "GenSigCmt" SG_ 307 CAN_DET_RANGE_20_05 "CAN_DET_RANGE_20_05";
BA_ "GenSigSendType" SG_ 307 CAN_DET_RANGE_RATE_20_05 0;
BA_ "GenSigCmt" SG_ 307 CAN_DET_RANGE_RATE_20_05 "CAN_DET_RANGE_RATE_20_05";
BA_ "GenSigSendType" SG_ 307 CAN_DET_AMPLITUDE_20_05 0;
BA_ "GenSigCmt" SG_ 307 CAN_DET_AMPLITUDE_20_05 "CAN_DET_AMPLITUDE_20_05";
BA_ "GenSigSendType" SG_ 307 CAN_SCAN_INDEX_2LSB_20_05 0;
BA_ "GenSigCmt" SG_ 307 CAN_SCAN_INDEX_2LSB_20_05 "CAN_SCAN_INDEX_2LSB_20_05";
BA_ "GenSigVtEn" SG_ 307 CAN_DET_CONFID_AZIMUTH_20_06 "CAN_DET_CONFID_AZIMUTH_20_06";
BA_ "GenSigVtName" SG_ 307 CAN_DET_CONFID_AZIMUTH_20_06 "CAN_DET_CONFID_AZIMUTH_20_06";
BA_ "GenSigSendType" SG_ 307 CAN_DET_CONFID_AZIMUTH_20_06 0;
BA_ "GenSigCmt" SG_ 307 CAN_DET_CONFID_AZIMUTH_20_06 "CAN_DET_CONFID_AZIMUTH_20_06";
BA_ "GenSigSendType" SG_ 307 CAN_DET_SUPER_RES_TARGET_20_06 0;
BA_ "GenSigCmt" SG_ 307 CAN_DET_SUPER_RES_TARGET_20_06 "CAN_DET_SUPER_RES_TARGET_20_06";
BA_ "GenSigSendType" SG_ 307 CAN_DET_ND_TARGET_20_06 0;
BA_ "GenSigCmt" SG_ 307 CAN_DET_ND_TARGET_20_06 "CAN_DET_ND_TARGET_20_06";
BA_ "GenSigSendType" SG_ 307 CAN_DET_HOST_VEH_CLUTTER_20_06 0;
BA_ "GenSigCmt" SG_ 307 CAN_DET_HOST_VEH_CLUTTER_20_06 "CAN_DET_HOST_VEH_CLUTTER_20_06";
BA_ "GenSigSendType" SG_ 307 CAN_DET_VALID_LEVEL_20_06 0;
BA_ "GenSigCmt" SG_ 307 CAN_DET_VALID_LEVEL_20_06 "CAN_DET_VALID_LEVEL_20_06";
BA_ "GenSigSendType" SG_ 307 CAN_DET_AZIMUTH_20_06 0;
BA_ "GenSigCmt" SG_ 307 CAN_DET_AZIMUTH_20_06 "CAN_DET_AZIMUTH_20_06";
BA_ "GenSigSendType" SG_ 307 CAN_DET_RANGE_20_06 0;
BA_ "GenSigCmt" SG_ 307 CAN_DET_RANGE_20_06 "CAN_DET_RANGE_20_06";
BA_ "GenSigSendType" SG_ 307 CAN_DET_RANGE_RATE_20_06 0;
BA_ "GenSigCmt" SG_ 307 CAN_DET_RANGE_RATE_20_06 "CAN_DET_RANGE_RATE_20_06";
BA_ "GenSigSendType" SG_ 307 CAN_DET_AMPLITUDE_20_06 0;
BA_ "GenSigCmt" SG_ 307 CAN_DET_AMPLITUDE_20_06 "CAN_DET_AMPLITUDE_20_06";
BA_ "GenSigSendType" SG_ 307 CAN_SCAN_INDEX_2LSB_20_06 0;
BA_ "GenSigCmt" SG_ 307 CAN_SCAN_INDEX_2LSB_20_06 "CAN_SCAN_INDEX_2LSB_20_06";
BA_ "GenMsgSendType" BO_ 306 1;
BA_ "GenSigVtEn" SG_ 306 CAN_DET_CONFID_AZIMUTH_19_01 "CAN_DET_CONFID_AZIMUTH_19_01";
BA_ "GenSigVtName" SG_ 306 CAN_DET_CONFID_AZIMUTH_19_01 "CAN_DET_CONFID_AZIMUTH_19_01";
BA_ "GenSigSendType" SG_ 306 CAN_DET_CONFID_AZIMUTH_19_01 0;
BA_ "GenSigCmt" SG_ 306 CAN_DET_CONFID_AZIMUTH_19_01 "CAN_DET_CONFID_AZIMUTH_19_01";
BA_ "GenSigSendType" SG_ 306 CAN_DET_SUPER_RES_TARGET_19_01 0;
BA_ "GenSigCmt" SG_ 306 CAN_DET_SUPER_RES_TARGET_19_01 "CAN_DET_SUPER_RES_TARGET_19_01";
BA_ "GenSigSendType" SG_ 306 CAN_DET_ND_TARGET_19_01 0;
BA_ "GenSigCmt" SG_ 306 CAN_DET_ND_TARGET_19_01 "CAN_DET_ND_TARGET_19_01";
BA_ "GenSigSendType" SG_ 306 CAN_DET_HOST_VEH_CLUTTER_19_01 0;
BA_ "GenSigCmt" SG_ 306 CAN_DET_HOST_VEH_CLUTTER_19_01 "CAN_DET_HOST_VEH_CLUTTER_19_01";
BA_ "GenSigSendType" SG_ 306 CAN_DET_VALID_LEVEL_19_01 0;
BA_ "GenSigCmt" SG_ 306 CAN_DET_VALID_LEVEL_19_01 "CAN_DET_VALID_LEVEL_19_01";
BA_ "GenSigSendType" SG_ 306 CAN_DET_AZIMUTH_19_01 0;
BA_ "GenSigCmt" SG_ 306 CAN_DET_AZIMUTH_19_01 "CAN_DET_AZIMUTH_19_01";
BA_ "GenSigSendType" SG_ 306 CAN_DET_RANGE_19_01 0;
BA_ "GenSigCmt" SG_ 306 CAN_DET_RANGE_19_01 "CAN_DET_RANGE_19_01";
BA_ "GenSigSendType" SG_ 306 CAN_DET_RANGE_RATE_19_01 0;
BA_ "GenSigCmt" SG_ 306 CAN_DET_RANGE_RATE_19_01 "CAN_DET_RANGE_RATE_19_01";
BA_ "GenSigSendType" SG_ 306 CAN_DET_AMPLITUDE_19_01 0;
BA_ "GenSigCmt" SG_ 306 CAN_DET_AMPLITUDE_19_01 "CAN_DET_AMPLITUDE_19_01";
BA_ "GenSigSendType" SG_ 306 CAN_SCAN_INDEX_2LSB_19_01 0;
BA_ "GenSigCmt" SG_ 306 CAN_SCAN_INDEX_2LSB_19_01 "CAN_SCAN_INDEX_2LSB_19_01";
BA_ "GenSigVtEn" SG_ 306 CAN_DET_CONFID_AZIMUTH_19_02 "CAN_DET_CONFID_AZIMUTH_19_02";
BA_ "GenSigVtName" SG_ 306 CAN_DET_CONFID_AZIMUTH_19_02 "CAN_DET_CONFID_AZIMUTH_19_02";
BA_ "GenSigSendType" SG_ 306 CAN_DET_CONFID_AZIMUTH_19_02 0;
BA_ "GenSigCmt" SG_ 306 CAN_DET_CONFID_AZIMUTH_19_02 "CAN_DET_CONFID_AZIMUTH_19_02";
BA_ "GenSigSendType" SG_ 306 CAN_DET_SUPER_RES_TARGET_19_02 0;
BA_ "GenSigCmt" SG_ 306 CAN_DET_SUPER_RES_TARGET_19_02 "CAN_DET_SUPER_RES_TARGET_19_02";
BA_ "GenSigSendType" SG_ 306 CAN_DET_ND_TARGET_19_02 0;
BA_ "GenSigCmt" SG_ 306 CAN_DET_ND_TARGET_19_02 "CAN_DET_ND_TARGET_19_02";
BA_ "GenSigSendType" SG_ 306 CAN_DET_HOST_VEH_CLUTTER_19_02 0;
BA_ "GenSigCmt" SG_ 306 CAN_DET_HOST_VEH_CLUTTER_19_02 "CAN_DET_HOST_VEH_CLUTTER_19_02";
BA_ "GenSigSendType" SG_ 306 CAN_DET_VALID_LEVEL_19_02 0;
BA_ "GenSigCmt" SG_ 306 CAN_DET_VALID_LEVEL_19_02 "CAN_DET_VALID_LEVEL_19_02";
BA_ "GenSigSendType" SG_ 306 CAN_DET_AZIMUTH_19_02 0;
BA_ "GenSigCmt" SG_ 306 CAN_DET_AZIMUTH_19_02 "CAN_DET_AZIMUTH_19_02";
BA_ "GenSigSendType" SG_ 306 CAN_DET_RANGE_19_02 0;
BA_ "GenSigCmt" SG_ 306 CAN_DET_RANGE_19_02 "CAN_DET_RANGE_19_02";
BA_ "GenSigSendType" SG_ 306 CAN_DET_RANGE_RATE_19_02 0;
BA_ "GenSigCmt" SG_ 306 CAN_DET_RANGE_RATE_19_02 "CAN_DET_RANGE_RATE_19_02";
BA_ "GenSigSendType" SG_ 306 CAN_DET_AMPLITUDE_19_02 0;
BA_ "GenSigCmt" SG_ 306 CAN_DET_AMPLITUDE_19_02 "CAN_DET_AMPLITUDE_19_02";
BA_ "GenSigSendType" SG_ 306 CAN_SCAN_INDEX_2LSB_19_02 0;
BA_ "GenSigCmt" SG_ 306 CAN_SCAN_INDEX_2LSB_19_02 "CAN_SCAN_INDEX_2LSB_19_02";
BA_ "GenSigVtEn" SG_ 306 CAN_DET_CONFID_AZIMUTH_19_03 "CAN_DET_CONFID_AZIMUTH_19_03";
BA_ "GenSigVtName" SG_ 306 CAN_DET_CONFID_AZIMUTH_19_03 "CAN_DET_CONFID_AZIMUTH_19_03";
BA_ "GenSigSendType" SG_ 306 CAN_DET_CONFID_AZIMUTH_19_03 0;
BA_ "GenSigCmt" SG_ 306 CAN_DET_CONFID_AZIMUTH_19_03 "CAN_DET_CONFID_AZIMUTH_19_03";
BA_ "GenSigSendType" SG_ 306 CAN_DET_SUPER_RES_TARGET_19_03 0;
BA_ "GenSigCmt" SG_ 306 CAN_DET_SUPER_RES_TARGET_19_03 "CAN_DET_SUPER_RES_TARGET_19_03";
BA_ "GenSigSendType" SG_ 306 CAN_DET_ND_TARGET_19_03 0;
BA_ "GenSigCmt" SG_ 306 CAN_DET_ND_TARGET_19_03 "CAN_DET_ND_TARGET_19_03";
BA_ "GenSigSendType" SG_ 306 CAN_DET_HOST_VEH_CLUTTER_19_03 0;
BA_ "GenSigCmt" SG_ 306 CAN_DET_HOST_VEH_CLUTTER_19_03 "CAN_DET_HOST_VEH_CLUTTER_19_03";
BA_ "GenSigSendType" SG_ 306 CAN_DET_VALID_LEVEL_19_03 0;
BA_ "GenSigCmt" SG_ 306 CAN_DET_VALID_LEVEL_19_03 "CAN_DET_VALID_LEVEL_19_03";
BA_ "GenSigSendType" SG_ 306 CAN_DET_AZIMUTH_19_03 0;
BA_ "GenSigCmt" SG_ 306 CAN_DET_AZIMUTH_19_03 "CAN_DET_AZIMUTH_19_03";
BA_ "GenSigSendType" SG_ 306 CAN_DET_RANGE_19_03 0;
BA_ "GenSigCmt" SG_ 306 CAN_DET_RANGE_19_03 "CAN_DET_RANGE_19_03";
BA_ "GenSigSendType" SG_ 306 CAN_DET_RANGE_RATE_19_03 0;
BA_ "GenSigCmt" SG_ 306 CAN_DET_RANGE_RATE_19_03 "CAN_DET_RANGE_RATE_19_03";
BA_ "GenSigSendType" SG_ 306 CAN_DET_AMPLITUDE_19_03 0;
BA_ "GenSigCmt" SG_ 306 CAN_DET_AMPLITUDE_19_03 "CAN_DET_AMPLITUDE_19_03";
BA_ "GenSigSendType" SG_ 306 CAN_SCAN_INDEX_2LSB_19_03 0;
BA_ "GenSigCmt" SG_ 306 CAN_SCAN_INDEX_2LSB_19_03 "CAN_SCAN_INDEX_2LSB_19_03";
BA_ "GenSigVtEn" SG_ 306 CAN_DET_CONFID_AZIMUTH_19_04 "CAN_DET_CONFID_AZIMUTH_19_04";
BA_ "GenSigVtName" SG_ 306 CAN_DET_CONFID_AZIMUTH_19_04 "CAN_DET_CONFID_AZIMUTH_19_04";
BA_ "GenSigSendType" SG_ 306 CAN_DET_CONFID_AZIMUTH_19_04 0;
BA_ "GenSigCmt" SG_ 306 CAN_DET_CONFID_AZIMUTH_19_04 "CAN_DET_CONFID_AZIMUTH_19_04";
BA_ "GenSigSendType" SG_ 306 CAN_DET_SUPER_RES_TARGET_19_04 0;
BA_ "GenSigCmt" SG_ 306 CAN_DET_SUPER_RES_TARGET_19_04 "CAN_DET_SUPER_RES_TARGET_19_04";
BA_ "GenSigSendType" SG_ 306 CAN_DET_ND_TARGET_19_04 0;
BA_ "GenSigCmt" SG_ 306 CAN_DET_ND_TARGET_19_04 "CAN_DET_ND_TARGET_19_04";
BA_ "GenSigSendType" SG_ 306 CAN_DET_HOST_VEH_CLUTTER_19_04 0;
BA_ "GenSigCmt" SG_ 306 CAN_DET_HOST_VEH_CLUTTER_19_04 "CAN_DET_HOST_VEH_CLUTTER_19_04";
BA_ "GenSigSendType" SG_ 306 CAN_DET_VALID_LEVEL_19_04 0;
BA_ "GenSigCmt" SG_ 306 CAN_DET_VALID_LEVEL_19_04 "CAN_DET_VALID_LEVEL_19_04";
BA_ "GenSigSendType" SG_ 306 CAN_DET_AZIMUTH_19_04 0;
BA_ "GenSigCmt" SG_ 306 CAN_DET_AZIMUTH_19_04 "CAN_DET_AZIMUTH_19_04";
BA_ "GenSigSendType" SG_ 306 CAN_DET_RANGE_19_04 0;
BA_ "GenSigCmt" SG_ 306 CAN_DET_RANGE_19_04 "CAN_DET_RANGE_19_04";
BA_ "GenSigSendType" SG_ 306 CAN_DET_RANGE_RATE_19_04 0;
BA_ "GenSigCmt" SG_ 306 CAN_DET_RANGE_RATE_19_04 "CAN_DET_RANGE_RATE_19_04";
BA_ "GenSigSendType" SG_ 306 CAN_DET_AMPLITUDE_19_04 0;
BA_ "GenSigCmt" SG_ 306 CAN_DET_AMPLITUDE_19_04 "CAN_DET_AMPLITUDE_19_04";
BA_ "GenSigSendType" SG_ 306 CAN_SCAN_INDEX_2LSB_19_04 0;
BA_ "GenSigCmt" SG_ 306 CAN_SCAN_INDEX_2LSB_19_04 "CAN_SCAN_INDEX_2LSB_19_04";
BA_ "GenSigVtEn" SG_ 306 CAN_DET_CONFID_AZIMUTH_19_05 "CAN_DET_CONFID_AZIMUTH_19_05";
BA_ "GenSigVtName" SG_ 306 CAN_DET_CONFID_AZIMUTH_19_05 "CAN_DET_CONFID_AZIMUTH_19_05";
BA_ "GenSigSendType" SG_ 306 CAN_DET_CONFID_AZIMUTH_19_05 0;
BA_ "GenSigCmt" SG_ 306 CAN_DET_CONFID_AZIMUTH_19_05 "CAN_DET_CONFID_AZIMUTH_19_05";
BA_ "GenSigSendType" SG_ 306 CAN_DET_SUPER_RES_TARGET_19_05 0;
BA_ "GenSigCmt" SG_ 306 CAN_DET_SUPER_RES_TARGET_19_05 "CAN_DET_SUPER_RES_TARGET_19_05";
BA_ "GenSigSendType" SG_ 306 CAN_DET_ND_TARGET_19_05 0;
BA_ "GenSigCmt" SG_ 306 CAN_DET_ND_TARGET_19_05 "CAN_DET_ND_TARGET_19_05";
BA_ "GenSigSendType" SG_ 306 CAN_DET_HOST_VEH_CLUTTER_19_05 0;
BA_ "GenSigCmt" SG_ 306 CAN_DET_HOST_VEH_CLUTTER_19_05 "CAN_DET_HOST_VEH_CLUTTER_19_05";
BA_ "GenSigSendType" SG_ 306 CAN_DET_VALID_LEVEL_19_05 0;
BA_ "GenSigCmt" SG_ 306 CAN_DET_VALID_LEVEL_19_05 "CAN_DET_VALID_LEVEL_19_05";
BA_ "GenSigSendType" SG_ 306 CAN_DET_AZIMUTH_19_05 0;
BA_ "GenSigCmt" SG_ 306 CAN_DET_AZIMUTH_19_05 "CAN_DET_AZIMUTH_19_05";
BA_ "GenSigSendType" SG_ 306 CAN_DET_RANGE_19_05 0;
BA_ "GenSigCmt" SG_ 306 CAN_DET_RANGE_19_05 "CAN_DET_RANGE_19_05";
BA_ "GenSigSendType" SG_ 306 CAN_DET_RANGE_RATE_19_05 0;
BA_ "GenSigCmt" SG_ 306 CAN_DET_RANGE_RATE_19_05 "CAN_DET_RANGE_RATE_19_05";
BA_ "GenSigSendType" SG_ 306 CAN_DET_AMPLITUDE_19_05 0;
BA_ "GenSigCmt" SG_ 306 CAN_DET_AMPLITUDE_19_05 "CAN_DET_AMPLITUDE_19_05";
BA_ "GenSigSendType" SG_ 306 CAN_SCAN_INDEX_2LSB_19_05 0;
BA_ "GenSigCmt" SG_ 306 CAN_SCAN_INDEX_2LSB_19_05 "CAN_SCAN_INDEX_2LSB_19_05";
BA_ "GenSigVtEn" SG_ 306 CAN_DET_CONFID_AZIMUTH_19_06 "CAN_DET_CONFID_AZIMUTH_19_06";
BA_ "GenSigVtName" SG_ 306 CAN_DET_CONFID_AZIMUTH_19_06 "CAN_DET_CONFID_AZIMUTH_19_06";
BA_ "GenSigSendType" SG_ 306 CAN_DET_CONFID_AZIMUTH_19_06 0;
BA_ "GenSigCmt" SG_ 306 CAN_DET_CONFID_AZIMUTH_19_06 "CAN_DET_CONFID_AZIMUTH_19_06";
BA_ "GenSigSendType" SG_ 306 CAN_DET_SUPER_RES_TARGET_19_06 0;
BA_ "GenSigCmt" SG_ 306 CAN_DET_SUPER_RES_TARGET_19_06 "CAN_DET_SUPER_RES_TARGET_19_06";
BA_ "GenSigSendType" SG_ 306 CAN_DET_ND_TARGET_19_06 0;
BA_ "GenSigCmt" SG_ 306 CAN_DET_ND_TARGET_19_06 "CAN_DET_ND_TARGET_19_06";
BA_ "GenSigSendType" SG_ 306 CAN_DET_HOST_VEH_CLUTTER_19_06 0;
BA_ "GenSigCmt" SG_ 306 CAN_DET_HOST_VEH_CLUTTER_19_06 "CAN_DET_HOST_VEH_CLUTTER_19_06";
BA_ "GenSigSendType" SG_ 306 CAN_DET_VALID_LEVEL_19_06 0;
BA_ "GenSigCmt" SG_ 306 CAN_DET_VALID_LEVEL_19_06 "CAN_DET_VALID_LEVEL_19_06";
BA_ "GenSigSendType" SG_ 306 CAN_DET_AZIMUTH_19_06 0;
BA_ "GenSigCmt" SG_ 306 CAN_DET_AZIMUTH_19_06 "CAN_DET_AZIMUTH_19_06";
BA_ "GenSigSendType" SG_ 306 CAN_DET_RANGE_19_06 0;
BA_ "GenSigCmt" SG_ 306 CAN_DET_RANGE_19_06 "CAN_DET_RANGE_19_06";
BA_ "GenSigSendType" SG_ 306 CAN_DET_RANGE_RATE_19_06 0;
BA_ "GenSigCmt" SG_ 306 CAN_DET_RANGE_RATE_19_06 "CAN_DET_RANGE_RATE_19_06";
BA_ "GenSigSendType" SG_ 306 CAN_DET_AMPLITUDE_19_06 0;
BA_ "GenSigCmt" SG_ 306 CAN_DET_AMPLITUDE_19_06 "CAN_DET_AMPLITUDE_19_06";
BA_ "GenSigSendType" SG_ 306 CAN_SCAN_INDEX_2LSB_19_06 0;
BA_ "GenSigCmt" SG_ 306 CAN_SCAN_INDEX_2LSB_19_06 "CAN_SCAN_INDEX_2LSB_19_06";
BA_ "GenMsgSendType" BO_ 305 1;
BA_ "GenSigVtEn" SG_ 305 CAN_DET_CONFID_AZIMUTH_18_01 "CAN_DET_CONFID_AZIMUTH_18_01";
BA_ "GenSigVtName" SG_ 305 CAN_DET_CONFID_AZIMUTH_18_01 "CAN_DET_CONFID_AZIMUTH_18_01";
BA_ "GenSigSendType" SG_ 305 CAN_DET_CONFID_AZIMUTH_18_01 0;
BA_ "GenSigCmt" SG_ 305 CAN_DET_CONFID_AZIMUTH_18_01 "CAN_DET_CONFID_AZIMUTH_18_01";
BA_ "GenSigSendType" SG_ 305 CAN_DET_SUPER_RES_TARGET_18_01 0;
BA_ "GenSigCmt" SG_ 305 CAN_DET_SUPER_RES_TARGET_18_01 "CAN_DET_SUPER_RES_TARGET_18_01";
BA_ "GenSigSendType" SG_ 305 CAN_DET_ND_TARGET_18_01 0;
BA_ "GenSigCmt" SG_ 305 CAN_DET_ND_TARGET_18_01 "CAN_DET_ND_TARGET_18_01";
BA_ "GenSigSendType" SG_ 305 CAN_DET_HOST_VEH_CLUTTER_18_01 0;
BA_ "GenSigCmt" SG_ 305 CAN_DET_HOST_VEH_CLUTTER_18_01 "CAN_DET_HOST_VEH_CLUTTER_18_01";
BA_ "GenSigSendType" SG_ 305 CAN_DET_VALID_LEVEL_18_01 0;
BA_ "GenSigCmt" SG_ 305 CAN_DET_VALID_LEVEL_18_01 "CAN_DET_VALID_LEVEL_18_01";
BA_ "GenSigSendType" SG_ 305 CAN_DET_AZIMUTH_18_01 0;
BA_ "GenSigCmt" SG_ 305 CAN_DET_AZIMUTH_18_01 "CAN_DET_AZIMUTH_18_01";
BA_ "GenSigSendType" SG_ 305 CAN_DET_RANGE_18_01 0;
BA_ "GenSigCmt" SG_ 305 CAN_DET_RANGE_18_01 "CAN_DET_RANGE_18_01";
BA_ "GenSigSendType" SG_ 305 CAN_DET_RANGE_RATE_18_01 0;
BA_ "GenSigCmt" SG_ 305 CAN_DET_RANGE_RATE_18_01 "CAN_DET_RANGE_RATE_18_01";
BA_ "GenSigSendType" SG_ 305 CAN_DET_AMPLITUDE_18_01 0;
BA_ "GenSigCmt" SG_ 305 CAN_DET_AMPLITUDE_18_01 "CAN_DET_AMPLITUDE_18_01";
BA_ "GenSigSendType" SG_ 305 CAN_SCAN_INDEX_2LSB_18_01 0;
BA_ "GenSigCmt" SG_ 305 CAN_SCAN_INDEX_2LSB_18_01 "CAN_SCAN_INDEX_2LSB_18_01";
BA_ "GenSigVtEn" SG_ 305 CAN_DET_CONFID_AZIMUTH_18_02 "CAN_DET_CONFID_AZIMUTH_18_02";
BA_ "GenSigVtName" SG_ 305 CAN_DET_CONFID_AZIMUTH_18_02 "CAN_DET_CONFID_AZIMUTH_18_02";
BA_ "GenSigSendType" SG_ 305 CAN_DET_CONFID_AZIMUTH_18_02 0;
BA_ "GenSigCmt" SG_ 305 CAN_DET_CONFID_AZIMUTH_18_02 "CAN_DET_CONFID_AZIMUTH_18_02";
BA_ "GenSigSendType" SG_ 305 CAN_DET_SUPER_RES_TARGET_18_02 0;
BA_ "GenSigCmt" SG_ 305 CAN_DET_SUPER_RES_TARGET_18_02 "CAN_DET_SUPER_RES_TARGET_18_02";
BA_ "GenSigSendType" SG_ 305 CAN_DET_ND_TARGET_18_02 0;
BA_ "GenSigCmt" SG_ 305 CAN_DET_ND_TARGET_18_02 "CAN_DET_ND_TARGET_18_02";
BA_ "GenSigSendType" SG_ 305 CAN_DET_HOST_VEH_CLUTTER_18_02 0;
BA_ "GenSigCmt" SG_ 305 CAN_DET_HOST_VEH_CLUTTER_18_02 "CAN_DET_HOST_VEH_CLUTTER_18_02";
BA_ "GenSigSendType" SG_ 305 CAN_DET_VALID_LEVEL_18_02 0;
BA_ "GenSigCmt" SG_ 305 CAN_DET_VALID_LEVEL_18_02 "CAN_DET_VALID_LEVEL_18_02";
BA_ "GenSigSendType" SG_ 305 CAN_DET_AZIMUTH_18_02 0;
BA_ "GenSigCmt" SG_ 305 CAN_DET_AZIMUTH_18_02 "CAN_DET_AZIMUTH_18_02";
BA_ "GenSigSendType" SG_ 305 CAN_DET_RANGE_18_02 0;
BA_ "GenSigCmt" SG_ 305 CAN_DET_RANGE_18_02 "CAN_DET_RANGE_18_02";
BA_ "GenSigSendType" SG_ 305 CAN_DET_RANGE_RATE_18_02 0;
BA_ "GenSigCmt" SG_ 305 CAN_DET_RANGE_RATE_18_02 "CAN_DET_RANGE_RATE_18_02";
BA_ "GenSigSendType" SG_ 305 CAN_DET_AMPLITUDE_18_02 0;
BA_ "GenSigCmt" SG_ 305 CAN_DET_AMPLITUDE_18_02 "CAN_DET_AMPLITUDE_18_02";
BA_ "GenSigSendType" SG_ 305 CAN_SCAN_INDEX_2LSB_18_02 0;
BA_ "GenSigCmt" SG_ 305 CAN_SCAN_INDEX_2LSB_18_02 "CAN_SCAN_INDEX_2LSB_18_02";
BA_ "GenSigVtEn" SG_ 305 CAN_DET_CONFID_AZIMUTH_18_03 "CAN_DET_CONFID_AZIMUTH_18_03";
BA_ "GenSigVtName" SG_ 305 CAN_DET_CONFID_AZIMUTH_18_03 "CAN_DET_CONFID_AZIMUTH_18_03";
BA_ "GenSigSendType" SG_ 305 CAN_DET_CONFID_AZIMUTH_18_03 0;
BA_ "GenSigCmt" SG_ 305 CAN_DET_CONFID_AZIMUTH_18_03 "CAN_DET_CONFID_AZIMUTH_18_03";
BA_ "GenSigSendType" SG_ 305 CAN_DET_SUPER_RES_TARGET_18_03 0;
BA_ "GenSigCmt" SG_ 305 CAN_DET_SUPER_RES_TARGET_18_03 "CAN_DET_SUPER_RES_TARGET_18_03";
BA_ "GenSigSendType" SG_ 305 CAN_DET_ND_TARGET_18_03 0;
BA_ "GenSigCmt" SG_ 305 CAN_DET_ND_TARGET_18_03 "CAN_DET_ND_TARGET_18_03";
BA_ "GenSigSendType" SG_ 305 CAN_DET_HOST_VEH_CLUTTER_18_03 0;
BA_ "GenSigCmt" SG_ 305 CAN_DET_HOST_VEH_CLUTTER_18_03 "CAN_DET_HOST_VEH_CLUTTER_18_03";
BA_ "GenSigSendType" SG_ 305 CAN_DET_VALID_LEVEL_18_03 0;
BA_ "GenSigCmt" SG_ 305 CAN_DET_VALID_LEVEL_18_03 "CAN_DET_VALID_LEVEL_18_03";
BA_ "GenSigSendType" SG_ 305 CAN_DET_AZIMUTH_18_03 0;
BA_ "GenSigCmt" SG_ 305 CAN_DET_AZIMUTH_18_03 "CAN_DET_AZIMUTH_18_03";
BA_ "GenSigSendType" SG_ 305 CAN_DET_RANGE_18_03 0;
BA_ "GenSigCmt" SG_ 305 CAN_DET_RANGE_18_03 "CAN_DET_RANGE_18_03";
BA_ "GenSigSendType" SG_ 305 CAN_DET_RANGE_RATE_18_03 0;
BA_ "GenSigCmt" SG_ 305 CAN_DET_RANGE_RATE_18_03 "CAN_DET_RANGE_RATE_18_03";
BA_ "GenSigSendType" SG_ 305 CAN_DET_AMPLITUDE_18_03 0;
BA_ "GenSigCmt" SG_ 305 CAN_DET_AMPLITUDE_18_03 "CAN_DET_AMPLITUDE_18_03";
BA_ "GenSigSendType" SG_ 305 CAN_SCAN_INDEX_2LSB_18_03 0;
BA_ "GenSigCmt" SG_ 305 CAN_SCAN_INDEX_2LSB_18_03 "CAN_SCAN_INDEX_2LSB_18_03";
BA_ "GenSigVtEn" SG_ 305 CAN_DET_CONFID_AZIMUTH_18_04 "CAN_DET_CONFID_AZIMUTH_18_04";
BA_ "GenSigVtName" SG_ 305 CAN_DET_CONFID_AZIMUTH_18_04 "CAN_DET_CONFID_AZIMUTH_18_04";
BA_ "GenSigSendType" SG_ 305 CAN_DET_CONFID_AZIMUTH_18_04 0;
BA_ "GenSigCmt" SG_ 305 CAN_DET_CONFID_AZIMUTH_18_04 "CAN_DET_CONFID_AZIMUTH_18_04";
BA_ "GenSigSendType" SG_ 305 CAN_DET_SUPER_RES_TARGET_18_04 0;
BA_ "GenSigCmt" SG_ 305 CAN_DET_SUPER_RES_TARGET_18_04 "CAN_DET_SUPER_RES_TARGET_18_04";
BA_ "GenSigSendType" SG_ 305 CAN_DET_ND_TARGET_18_04 0;
BA_ "GenSigCmt" SG_ 305 CAN_DET_ND_TARGET_18_04 "CAN_DET_ND_TARGET_18_04";
BA_ "GenSigSendType" SG_ 305 CAN_DET_HOST_VEH_CLUTTER_18_04 0;
BA_ "GenSigCmt" SG_ 305 CAN_DET_HOST_VEH_CLUTTER_18_04 "CAN_DET_HOST_VEH_CLUTTER_18_04";
BA_ "GenSigSendType" SG_ 305 CAN_DET_VALID_LEVEL_18_04 0;
BA_ "GenSigCmt" SG_ 305 CAN_DET_VALID_LEVEL_18_04 "CAN_DET_VALID_LEVEL_18_04";
BA_ "GenSigSendType" SG_ 305 CAN_DET_AZIMUTH_18_04 0;
BA_ "GenSigCmt" SG_ 305 CAN_DET_AZIMUTH_18_04 "CAN_DET_AZIMUTH_18_04";
BA_ "GenSigSendType" SG_ 305 CAN_DET_RANGE_18_04 0;
BA_ "GenSigCmt" SG_ 305 CAN_DET_RANGE_18_04 "CAN_DET_RANGE_18_04";
BA_ "GenSigSendType" SG_ 305 CAN_DET_RANGE_RATE_18_04 0;
BA_ "GenSigCmt" SG_ 305 CAN_DET_RANGE_RATE_18_04 "CAN_DET_RANGE_RATE_18_04";
BA_ "GenSigSendType" SG_ 305 CAN_DET_AMPLITUDE_18_04 0;
BA_ "GenSigCmt" SG_ 305 CAN_DET_AMPLITUDE_18_04 "CAN_DET_AMPLITUDE_18_04";
BA_ "GenSigSendType" SG_ 305 CAN_SCAN_INDEX_2LSB_18_04 0;
BA_ "GenSigCmt" SG_ 305 CAN_SCAN_INDEX_2LSB_18_04 "CAN_SCAN_INDEX_2LSB_18_04";
BA_ "GenSigVtEn" SG_ 305 CAN_DET_CONFID_AZIMUTH_18_05 "CAN_DET_CONFID_AZIMUTH_18_05";
BA_ "GenSigVtName" SG_ 305 CAN_DET_CONFID_AZIMUTH_18_05 "CAN_DET_CONFID_AZIMUTH_18_05";
BA_ "GenSigSendType" SG_ 305 CAN_DET_CONFID_AZIMUTH_18_05 0;
BA_ "GenSigCmt" SG_ 305 CAN_DET_CONFID_AZIMUTH_18_05 "CAN_DET_CONFID_AZIMUTH_18_05";
BA_ "GenSigSendType" SG_ 305 CAN_DET_SUPER_RES_TARGET_18_05 0;
BA_ "GenSigCmt" SG_ 305 CAN_DET_SUPER_RES_TARGET_18_05 "CAN_DET_SUPER_RES_TARGET_18_05";
BA_ "GenSigSendType" SG_ 305 CAN_DET_ND_TARGET_18_05 0;
BA_ "GenSigCmt" SG_ 305 CAN_DET_ND_TARGET_18_05 "CAN_DET_ND_TARGET_18_05";
BA_ "GenSigSendType" SG_ 305 CAN_DET_HOST_VEH_CLUTTER_18_05 0;
BA_ "GenSigCmt" SG_ 305 CAN_DET_HOST_VEH_CLUTTER_18_05 "CAN_DET_HOST_VEH_CLUTTER_18_05";
BA_ "GenSigSendType" SG_ 305 CAN_DET_VALID_LEVEL_18_05 0;
BA_ "GenSigCmt" SG_ 305 CAN_DET_VALID_LEVEL_18_05 "CAN_DET_VALID_LEVEL_18_05";
BA_ "GenSigSendType" SG_ 305 CAN_DET_AZIMUTH_18_05 0;
BA_ "GenSigCmt" SG_ 305 CAN_DET_AZIMUTH_18_05 "CAN_DET_AZIMUTH_18_05";
BA_ "GenSigSendType" SG_ 305 CAN_DET_RANGE_18_05 0;
BA_ "GenSigCmt" SG_ 305 CAN_DET_RANGE_18_05 "CAN_DET_RANGE_18_05";
BA_ "GenSigSendType" SG_ 305 CAN_DET_RANGE_RATE_18_05 0;
BA_ "GenSigCmt" SG_ 305 CAN_DET_RANGE_RATE_18_05 "CAN_DET_RANGE_RATE_18_05";
BA_ "GenSigSendType" SG_ 305 CAN_DET_AMPLITUDE_18_05 0;
BA_ "GenSigCmt" SG_ 305 CAN_DET_AMPLITUDE_18_05 "CAN_DET_AMPLITUDE_18_05";
BA_ "GenSigSendType" SG_ 305 CAN_SCAN_INDEX_2LSB_18_05 0;
BA_ "GenSigCmt" SG_ 305 CAN_SCAN_INDEX_2LSB_18_05 "CAN_SCAN_INDEX_2LSB_18_05";
BA_ "GenSigVtEn" SG_ 305 CAN_DET_CONFID_AZIMUTH_18_06 "CAN_DET_CONFID_AZIMUTH_18_06";
BA_ "GenSigVtName" SG_ 305 CAN_DET_CONFID_AZIMUTH_18_06 "CAN_DET_CONFID_AZIMUTH_18_06";
BA_ "GenSigSendType" SG_ 305 CAN_DET_CONFID_AZIMUTH_18_06 0;
BA_ "GenSigCmt" SG_ 305 CAN_DET_CONFID_AZIMUTH_18_06 "CAN_DET_CONFID_AZIMUTH_18_06";
BA_ "GenSigSendType" SG_ 305 CAN_DET_SUPER_RES_TARGET_18_06 0;
BA_ "GenSigCmt" SG_ 305 CAN_DET_SUPER_RES_TARGET_18_06 "CAN_DET_SUPER_RES_TARGET_18_06";
BA_ "GenSigSendType" SG_ 305 CAN_DET_ND_TARGET_18_06 0;
BA_ "GenSigCmt" SG_ 305 CAN_DET_ND_TARGET_18_06 "CAN_DET_ND_TARGET_18_06";
BA_ "GenSigSendType" SG_ 305 CAN_DET_HOST_VEH_CLUTTER_18_06 0;
BA_ "GenSigCmt" SG_ 305 CAN_DET_HOST_VEH_CLUTTER_18_06 "CAN_DET_HOST_VEH_CLUTTER_18_06";
BA_ "GenSigSendType" SG_ 305 CAN_DET_VALID_LEVEL_18_06 0;
BA_ "GenSigCmt" SG_ 305 CAN_DET_VALID_LEVEL_18_06 "CAN_DET_VALID_LEVEL_18_06";
BA_ "GenSigSendType" SG_ 305 CAN_DET_AZIMUTH_18_06 0;
BA_ "GenSigCmt" SG_ 305 CAN_DET_AZIMUTH_18_06 "CAN_DET_AZIMUTH_18_06";
BA_ "GenSigSendType" SG_ 305 CAN_DET_RANGE_18_06 0;
BA_ "GenSigCmt" SG_ 305 CAN_DET_RANGE_18_06 "CAN_DET_RANGE_18_06";
BA_ "GenSigSendType" SG_ 305 CAN_DET_RANGE_RATE_18_06 0;
BA_ "GenSigCmt" SG_ 305 CAN_DET_RANGE_RATE_18_06 "CAN_DET_RANGE_RATE_18_06";
BA_ "GenSigSendType" SG_ 305 CAN_DET_AMPLITUDE_18_06 0;
BA_ "GenSigCmt" SG_ 305 CAN_DET_AMPLITUDE_18_06 "CAN_DET_AMPLITUDE_18_06";
BA_ "GenSigSendType" SG_ 305 CAN_SCAN_INDEX_2LSB_18_06 0;
BA_ "GenSigCmt" SG_ 305 CAN_SCAN_INDEX_2LSB_18_06 "CAN_SCAN_INDEX_2LSB_18_06";
BA_ "GenMsgSendType" BO_ 341 1;
BA_ "GenSigVtEn" SG_ 341 CAN_DET_CONFID_AZIMUTH_54 "CAN_DET_CONFID_AZIMUTH_54";
BA_ "GenSigVtName" SG_ 341 CAN_DET_CONFID_AZIMUTH_54 "CAN_DET_CONFID_AZIMUTH_54";
BA_ "GenSigSendType" SG_ 341 CAN_DET_CONFID_AZIMUTH_54 0;
BA_ "GenSigCmt" SG_ 341 CAN_DET_CONFID_AZIMUTH_54 "CAN_DET_CONFID_AZIMUTH_54";
BA_ "GenSigSendType" SG_ 341 CAN_DET_SUPER_RES_TARGET_54 0;
BA_ "GenSigCmt" SG_ 341 CAN_DET_SUPER_RES_TARGET_54 "CAN_DET_SUPER_RES_TARGET_54";
BA_ "GenSigSendType" SG_ 341 CAN_DET_ND_TARGET_54 0;
BA_ "GenSigCmt" SG_ 341 CAN_DET_ND_TARGET_54 "CAN_DET_ND_TARGET_54";
BA_ "GenSigSendType" SG_ 341 CAN_DET_HOST_VEH_CLUTTER_54 0;
BA_ "GenSigCmt" SG_ 341 CAN_DET_HOST_VEH_CLUTTER_54 "CAN_DET_HOST_VEH_CLUTTER_54";
BA_ "GenSigSendType" SG_ 341 CAN_DET_VALID_LEVEL_54 0;
BA_ "GenSigCmt" SG_ 341 CAN_DET_VALID_LEVEL_54 "CAN_DET_VALID_LEVEL_54";
BA_ "GenSigSendType" SG_ 341 CAN_DET_AZIMUTH_54 0;
BA_ "GenSigCmt" SG_ 341 CAN_DET_AZIMUTH_54 "CAN_DET_AZIMUTH_54";
BA_ "GenSigSendType" SG_ 341 CAN_DET_RANGE_54 0;
BA_ "GenSigCmt" SG_ 341 CAN_DET_RANGE_54 "CAN_DET_RANGE_54";
BA_ "GenSigSendType" SG_ 341 CAN_DET_RANGE_RATE_54 0;
BA_ "GenSigCmt" SG_ 341 CAN_DET_RANGE_RATE_54 "CAN_DET_RANGE_RATE_54";
BA_ "GenSigSendType" SG_ 341 CAN_DET_AMPLITUDE_54 0;
BA_ "GenSigCmt" SG_ 341 CAN_DET_AMPLITUDE_54 "CAN_DET_AMPLITUDE_54";
BA_ "GenSigSendType" SG_ 341 CAN_SCAN_INDEX_2LSB_54 0;
BA_ "GenSigCmt" SG_ 341 CAN_SCAN_INDEX_2LSB_54 "CAN_SCAN_INDEX_2LSB_54";
BA_ "GenMsgSendType" BO_ 340 1;
BA_ "GenSigVtEn" SG_ 340 CAN_DET_CONFID_AZIMUTH_53 "CAN_DET_CONFID_AZIMUTH_53";
BA_ "GenSigVtName" SG_ 340 CAN_DET_CONFID_AZIMUTH_53 "CAN_DET_CONFID_AZIMUTH_53";
BA_ "GenSigSendType" SG_ 340 CAN_DET_CONFID_AZIMUTH_53 0;
BA_ "GenSigCmt" SG_ 340 CAN_DET_CONFID_AZIMUTH_53 "CAN_DET_CONFID_AZIMUTH_53";
BA_ "GenSigSendType" SG_ 340 CAN_DET_SUPER_RES_TARGET_53 0;
BA_ "GenSigCmt" SG_ 340 CAN_DET_SUPER_RES_TARGET_53 "CAN_DET_SUPER_RES_TARGET_53";
BA_ "GenSigSendType" SG_ 340 CAN_DET_ND_TARGET_53 0;
BA_ "GenSigCmt" SG_ 340 CAN_DET_ND_TARGET_53 "CAN_DET_ND_TARGET_53";
BA_ "GenSigSendType" SG_ 340 CAN_DET_HOST_VEH_CLUTTER_53 0;
BA_ "GenSigCmt" SG_ 340 CAN_DET_HOST_VEH_CLUTTER_53 "CAN_DET_HOST_VEH_CLUTTER_53";
BA_ "GenSigSendType" SG_ 340 CAN_DET_VALID_LEVEL_53 0;
BA_ "GenSigCmt" SG_ 340 CAN_DET_VALID_LEVEL_53 "CAN_DET_VALID_LEVEL_53";
BA_ "GenSigSendType" SG_ 340 CAN_DET_AZIMUTH_53 0;
BA_ "GenSigCmt" SG_ 340 CAN_DET_AZIMUTH_53 "CAN_DET_AZIMUTH_53";
BA_ "GenSigSendType" SG_ 340 CAN_DET_RANGE_53 0;
BA_ "GenSigCmt" SG_ 340 CAN_DET_RANGE_53 "CAN_DET_RANGE_53";
BA_ "GenSigSendType" SG_ 340 CAN_DET_RANGE_RATE_53 0;
BA_ "GenSigCmt" SG_ 340 CAN_DET_RANGE_RATE_53 "CAN_DET_RANGE_RATE_53";
BA_ "GenSigSendType" SG_ 340 CAN_DET_AMPLITUDE_53 0;
BA_ "GenSigCmt" SG_ 340 CAN_DET_AMPLITUDE_53 "CAN_DET_AMPLITUDE_53";
BA_ "GenSigSendType" SG_ 340 CAN_SCAN_INDEX_2LSB_53 0;
BA_ "GenSigCmt" SG_ 340 CAN_SCAN_INDEX_2LSB_53 "CAN_SCAN_INDEX_2LSB_53";
BA_ "GenMsgSendType" BO_ 339 1;
BA_ "GenSigVtEn" SG_ 339 CAN_DET_CONFID_AZIMUTH_52 "CAN_DET_CONFID_AZIMUTH_52";
BA_ "GenSigVtName" SG_ 339 CAN_DET_CONFID_AZIMUTH_52 "CAN_DET_CONFID_AZIMUTH_52";
BA_ "GenSigSendType" SG_ 339 CAN_DET_CONFID_AZIMUTH_52 0;
BA_ "GenSigCmt" SG_ 339 CAN_DET_CONFID_AZIMUTH_52 "CAN_DET_CONFID_AZIMUTH_52";
BA_ "GenSigSendType" SG_ 339 CAN_DET_SUPER_RES_TARGET_52 0;
BA_ "GenSigCmt" SG_ 339 CAN_DET_SUPER_RES_TARGET_52 "CAN_DET_SUPER_RES_TARGET_52";
BA_ "GenSigSendType" SG_ 339 CAN_DET_ND_TARGET_52 0;
BA_ "GenSigCmt" SG_ 339 CAN_DET_ND_TARGET_52 "CAN_DET_ND_TARGET_52";
BA_ "GenSigSendType" SG_ 339 CAN_DET_HOST_VEH_CLUTTER_52 0;
BA_ "GenSigCmt" SG_ 339 CAN_DET_HOST_VEH_CLUTTER_52 "CAN_DET_HOST_VEH_CLUTTER_52";
BA_ "GenSigSendType" SG_ 339 CAN_DET_VALID_LEVEL_52 0;
BA_ "GenSigCmt" SG_ 339 CAN_DET_VALID_LEVEL_52 "CAN_DET_VALID_LEVEL_52";
BA_ "GenSigSendType" SG_ 339 CAN_DET_AZIMUTH_52 0;
BA_ "GenSigCmt" SG_ 339 CAN_DET_AZIMUTH_52 "CAN_DET_AZIMUTH_52";
BA_ "GenSigSendType" SG_ 339 CAN_DET_RANGE_52 0;
BA_ "GenSigCmt" SG_ 339 CAN_DET_RANGE_52 "CAN_DET_RANGE_52";
BA_ "GenSigSendType" SG_ 339 CAN_DET_RANGE_RATE_52 0;
BA_ "GenSigCmt" SG_ 339 CAN_DET_RANGE_RATE_52 "CAN_DET_RANGE_RATE_52";
BA_ "GenSigSendType" SG_ 339 CAN_DET_AMPLITUDE_52 0;
BA_ "GenSigCmt" SG_ 339 CAN_DET_AMPLITUDE_52 "CAN_DET_AMPLITUDE_52";
BA_ "GenSigSendType" SG_ 339 CAN_SCAN_INDEX_2LSB_52 0;
BA_ "GenSigCmt" SG_ 339 CAN_SCAN_INDEX_2LSB_52 "CAN_SCAN_INDEX_2LSB_52";
BA_ "GenMsgSendType" BO_ 338 1;
BA_ "GenSigVtEn" SG_ 338 CAN_DET_CONFID_AZIMUTH_51 "CAN_DET_CONFID_AZIMUTH_51";
BA_ "GenSigVtName" SG_ 338 CAN_DET_CONFID_AZIMUTH_51 "CAN_DET_CONFID_AZIMUTH_51";
BA_ "GenSigSendType" SG_ 338 CAN_DET_CONFID_AZIMUTH_51 0;
BA_ "GenSigCmt" SG_ 338 CAN_DET_CONFID_AZIMUTH_51 "CAN_DET_CONFID_AZIMUTH_51";
BA_ "GenSigSendType" SG_ 338 CAN_DET_SUPER_RES_TARGET_51 0;
BA_ "GenSigCmt" SG_ 338 CAN_DET_SUPER_RES_TARGET_51 "CAN_DET_SUPER_RES_TARGET_51";
BA_ "GenSigSendType" SG_ 338 CAN_DET_ND_TARGET_51 0;
BA_ "GenSigCmt" SG_ 338 CAN_DET_ND_TARGET_51 "CAN_DET_ND_TARGET_51";
BA_ "GenSigSendType" SG_ 338 CAN_DET_HOST_VEH_CLUTTER_51 0;
BA_ "GenSigCmt" SG_ 338 CAN_DET_HOST_VEH_CLUTTER_51 "CAN_DET_HOST_VEH_CLUTTER_51";
BA_ "GenSigSendType" SG_ 338 CAN_DET_VALID_LEVEL_51 0;
BA_ "GenSigCmt" SG_ 338 CAN_DET_VALID_LEVEL_51 "CAN_DET_VALID_LEVEL_51";
BA_ "GenSigSendType" SG_ 338 CAN_DET_AZIMUTH_51 0;
BA_ "GenSigCmt" SG_ 338 CAN_DET_AZIMUTH_51 "CAN_DET_AZIMUTH_51";
BA_ "GenSigSendType" SG_ 338 CAN_DET_RANGE_51 0;
BA_ "GenSigCmt" SG_ 338 CAN_DET_RANGE_51 "CAN_DET_RANGE_51";
BA_ "GenSigSendType" SG_ 338 CAN_DET_RANGE_RATE_51 0;
BA_ "GenSigCmt" SG_ 338 CAN_DET_RANGE_RATE_51 "CAN_DET_RANGE_RATE_51";
BA_ "GenSigSendType" SG_ 338 CAN_DET_AMPLITUDE_51 0;
BA_ "GenSigCmt" SG_ 338 CAN_DET_AMPLITUDE_51 "CAN_DET_AMPLITUDE_51";
BA_ "GenSigSendType" SG_ 338 CAN_SCAN_INDEX_2LSB_51 0;
BA_ "GenSigCmt" SG_ 338 CAN_SCAN_INDEX_2LSB_51 "CAN_SCAN_INDEX_2LSB_51";
BA_ "GenMsgSendType" BO_ 337 1;
BA_ "GenSigVtEn" SG_ 337 CAN_DET_CONFID_AZIMUTH_50 "CAN_DET_CONFID_AZIMUTH_50";
BA_ "GenSigVtName" SG_ 337 CAN_DET_CONFID_AZIMUTH_50 "CAN_DET_CONFID_AZIMUTH_50";
BA_ "GenSigSendType" SG_ 337 CAN_DET_CONFID_AZIMUTH_50 0;
BA_ "GenSigCmt" SG_ 337 CAN_DET_CONFID_AZIMUTH_50 "CAN_DET_CONFID_AZIMUTH_50";
BA_ "GenSigSendType" SG_ 337 CAN_DET_SUPER_RES_TARGET_50 0;
BA_ "GenSigCmt" SG_ 337 CAN_DET_SUPER_RES_TARGET_50 "CAN_DET_SUPER_RES_TARGET_50";
BA_ "GenSigSendType" SG_ 337 CAN_DET_ND_TARGET_50 0;
BA_ "GenSigCmt" SG_ 337 CAN_DET_ND_TARGET_50 "CAN_DET_ND_TARGET_50";
BA_ "GenSigSendType" SG_ 337 CAN_DET_HOST_VEH_CLUTTER_50 0;
BA_ "GenSigCmt" SG_ 337 CAN_DET_HOST_VEH_CLUTTER_50 "CAN_DET_HOST_VEH_CLUTTER_50";
BA_ "GenSigSendType" SG_ 337 CAN_DET_VALID_LEVEL_50 0;
BA_ "GenSigCmt" SG_ 337 CAN_DET_VALID_LEVEL_50 "CAN_DET_VALID_LEVEL_50";
BA_ "GenSigSendType" SG_ 337 CAN_DET_AZIMUTH_50 0;
BA_ "GenSigCmt" SG_ 337 CAN_DET_AZIMUTH_50 "CAN_DET_AZIMUTH_50";
BA_ "GenSigSendType" SG_ 337 CAN_DET_RANGE_50 0;
BA_ "GenSigCmt" SG_ 337 CAN_DET_RANGE_50 "CAN_DET_RANGE_50";
BA_ "GenSigSendType" SG_ 337 CAN_DET_RANGE_RATE_50 0;
BA_ "GenSigCmt" SG_ 337 CAN_DET_RANGE_RATE_50 "CAN_DET_RANGE_RATE_50";
BA_ "GenSigSendType" SG_ 337 CAN_DET_AMPLITUDE_50 0;
BA_ "GenSigCmt" SG_ 337 CAN_DET_AMPLITUDE_50 "CAN_DET_AMPLITUDE_50";
BA_ "GenSigSendType" SG_ 337 CAN_SCAN_INDEX_2LSB_50 0;
BA_ "GenSigCmt" SG_ 337 CAN_SCAN_INDEX_2LSB_50 "CAN_SCAN_INDEX_2LSB_50";
BA_ "GenMsgSendType" BO_ 336 1;
BA_ "GenSigVtEn" SG_ 336 CAN_DET_CONFID_AZIMUTH_49 "CAN_DET_CONFID_AZIMUTH_49";
BA_ "GenSigVtName" SG_ 336 CAN_DET_CONFID_AZIMUTH_49 "CAN_DET_CONFID_AZIMUTH_49";
BA_ "GenSigSendType" SG_ 336 CAN_DET_CONFID_AZIMUTH_49 0;
BA_ "GenSigCmt" SG_ 336 CAN_DET_CONFID_AZIMUTH_49 "CAN_DET_CONFID_AZIMUTH_49";
BA_ "GenSigSendType" SG_ 336 CAN_DET_SUPER_RES_TARGET_49 0;
BA_ "GenSigCmt" SG_ 336 CAN_DET_SUPER_RES_TARGET_49 "CAN_DET_SUPER_RES_TARGET_49";
BA_ "GenSigSendType" SG_ 336 CAN_DET_ND_TARGET_49 0;
BA_ "GenSigCmt" SG_ 336 CAN_DET_ND_TARGET_49 "CAN_DET_ND_TARGET_49";
BA_ "GenSigSendType" SG_ 336 CAN_DET_HOST_VEH_CLUTTER_49 0;
BA_ "GenSigCmt" SG_ 336 CAN_DET_HOST_VEH_CLUTTER_49 "CAN_DET_HOST_VEH_CLUTTER_49";
BA_ "GenSigSendType" SG_ 336 CAN_DET_VALID_LEVEL_49 0;
BA_ "GenSigCmt" SG_ 336 CAN_DET_VALID_LEVEL_49 "CAN_DET_VALID_LEVEL_49";
BA_ "GenSigSendType" SG_ 336 CAN_DET_AZIMUTH_49 0;
BA_ "GenSigCmt" SG_ 336 CAN_DET_AZIMUTH_49 "CAN_DET_AZIMUTH_49";
BA_ "GenSigSendType" SG_ 336 CAN_DET_RANGE_49 0;
BA_ "GenSigCmt" SG_ 336 CAN_DET_RANGE_49 "CAN_DET_RANGE_49";
BA_ "GenSigSendType" SG_ 336 CAN_DET_RANGE_RATE_49 0;
BA_ "GenSigCmt" SG_ 336 CAN_DET_RANGE_RATE_49 "CAN_DET_RANGE_RATE_49";
BA_ "GenSigSendType" SG_ 336 CAN_DET_AMPLITUDE_49 0;
BA_ "GenSigCmt" SG_ 336 CAN_DET_AMPLITUDE_49 "CAN_DET_AMPLITUDE_49";
BA_ "GenSigSendType" SG_ 336 CAN_SCAN_INDEX_2LSB_49 0;
BA_ "GenSigCmt" SG_ 336 CAN_SCAN_INDEX_2LSB_49 "CAN_SCAN_INDEX_2LSB_49";
BA_ "GenMsgSendType" BO_ 326 1;
BA_ "GenSigVtEn" SG_ 326 CAN_DET_CONFID_AZIMUTH_39 "CAN_DET_CONFID_AZIMUTH_39";
BA_ "GenSigVtName" SG_ 326 CAN_DET_CONFID_AZIMUTH_39 "CAN_DET_CONFID_AZIMUTH_39";
BA_ "GenSigSendType" SG_ 326 CAN_DET_CONFID_AZIMUTH_39 0;
BA_ "GenSigCmt" SG_ 326 CAN_DET_CONFID_AZIMUTH_39 "CAN_DET_CONFID_AZIMUTH_39";
BA_ "GenSigSendType" SG_ 326 CAN_DET_SUPER_RES_TARGET_39 0;
BA_ "GenSigCmt" SG_ 326 CAN_DET_SUPER_RES_TARGET_39 "CAN_DET_SUPER_RES_TARGET_39";
BA_ "GenSigSendType" SG_ 326 CAN_DET_ND_TARGET_39 0;
BA_ "GenSigCmt" SG_ 326 CAN_DET_ND_TARGET_39 "CAN_DET_ND_TARGET_39";
BA_ "GenSigSendType" SG_ 326 CAN_DET_HOST_VEH_CLUTTER_39 0;
BA_ "GenSigCmt" SG_ 326 CAN_DET_HOST_VEH_CLUTTER_39 "CAN_DET_HOST_VEH_CLUTTER_39";
BA_ "GenSigSendType" SG_ 326 CAN_DET_VALID_LEVEL_39 0;
BA_ "GenSigCmt" SG_ 326 CAN_DET_VALID_LEVEL_39 "CAN_DET_VALID_LEVEL_39";
BA_ "GenSigSendType" SG_ 326 CAN_DET_AZIMUTH_39 0;
BA_ "GenSigCmt" SG_ 326 CAN_DET_AZIMUTH_39 "CAN_DET_AZIMUTH_39";
BA_ "GenSigSendType" SG_ 326 CAN_DET_RANGE_39 0;
BA_ "GenSigCmt" SG_ 326 CAN_DET_RANGE_39 "CAN_DET_RANGE_39";
BA_ "GenSigSendType" SG_ 326 CAN_DET_RANGE_RATE_39 0;
BA_ "GenSigCmt" SG_ 326 CAN_DET_RANGE_RATE_39 "CAN_DET_RANGE_RATE_39";
BA_ "GenSigSendType" SG_ 326 CAN_DET_AMPLITUDE_39 0;
BA_ "GenSigCmt" SG_ 326 CAN_DET_AMPLITUDE_39 "CAN_DET_AMPLITUDE_39";
BA_ "GenSigSendType" SG_ 326 CAN_SCAN_INDEX_2LSB_39 0;
BA_ "GenSigCmt" SG_ 326 CAN_SCAN_INDEX_2LSB_39 "CAN_SCAN_INDEX_2LSB_39";
BA_ "GenMsgSendType" BO_ 315 1;
BA_ "GenSigVtEn" SG_ 315 CAN_DET_CONFID_AZIMUTH_28 "CAN_DET_CONFID_AZIMUTH_28";
BA_ "GenSigVtName" SG_ 315 CAN_DET_CONFID_AZIMUTH_28 "CAN_DET_CONFID_AZIMUTH_28";
BA_ "GenSigSendType" SG_ 315 CAN_DET_CONFID_AZIMUTH_28 0;
BA_ "GenSigCmt" SG_ 315 CAN_DET_CONFID_AZIMUTH_28 "CAN_DET_CONFID_AZIMUTH_28";
BA_ "GenSigSendType" SG_ 315 CAN_DET_SUPER_RES_TARGET_28 0;
BA_ "GenSigCmt" SG_ 315 CAN_DET_SUPER_RES_TARGET_28 "CAN_DET_SUPER_RES_TARGET_28";
BA_ "GenSigSendType" SG_ 315 CAN_DET_ND_TARGET_28 0;
BA_ "GenSigCmt" SG_ 315 CAN_DET_ND_TARGET_28 "CAN_DET_ND_TARGET_28";
BA_ "GenSigSendType" SG_ 315 CAN_DET_HOST_VEH_CLUTTER_28 0;
BA_ "GenSigCmt" SG_ 315 CAN_DET_HOST_VEH_CLUTTER_28 "CAN_DET_HOST_VEH_CLUTTER_28";
BA_ "GenSigSendType" SG_ 315 CAN_DET_VALID_LEVEL_28 0;
BA_ "GenSigCmt" SG_ 315 CAN_DET_VALID_LEVEL_28 "CAN_DET_VALID_LEVEL_28";
BA_ "GenSigSendType" SG_ 315 CAN_DET_AZIMUTH_28 0;
BA_ "GenSigCmt" SG_ 315 CAN_DET_AZIMUTH_28 "CAN_DET_AZIMUTH_28";
BA_ "GenSigSendType" SG_ 315 CAN_DET_RANGE_28 0;
BA_ "GenSigCmt" SG_ 315 CAN_DET_RANGE_28 "CAN_DET_RANGE_28";
BA_ "GenSigSendType" SG_ 315 CAN_DET_RANGE_RATE_28 0;
BA_ "GenSigCmt" SG_ 315 CAN_DET_RANGE_RATE_28 "CAN_DET_RANGE_RATE_28";
BA_ "GenSigSendType" SG_ 315 CAN_DET_AMPLITUDE_28 0;
BA_ "GenSigCmt" SG_ 315 CAN_DET_AMPLITUDE_28 "CAN_DET_AMPLITUDE_28";
BA_ "GenSigSendType" SG_ 315 CAN_SCAN_INDEX_2LSB_28 0;
BA_ "GenSigCmt" SG_ 315 CAN_SCAN_INDEX_2LSB_28 "CAN_SCAN_INDEX_2LSB_28";
BA_ "GenMsgSendType" BO_ 304 1;
BA_ "GenSigVtEn" SG_ 304 CAN_DET_CONFID_AZIMUTH_17_01 "CAN_DET_CONFID_AZIMUTH_17_01";
BA_ "GenSigVtName" SG_ 304 CAN_DET_CONFID_AZIMUTH_17_01 "CAN_DET_CONFID_AZIMUTH_17_01";
BA_ "GenSigSendType" SG_ 304 CAN_DET_CONFID_AZIMUTH_17_01 0;
BA_ "GenSigCmt" SG_ 304 CAN_DET_CONFID_AZIMUTH_17_01 "CAN_DET_CONFID_AZIMUTH_17_01";
BA_ "GenSigSendType" SG_ 304 CAN_DET_SUPER_RES_TARGET_17_01 0;
BA_ "GenSigCmt" SG_ 304 CAN_DET_SUPER_RES_TARGET_17_01 "CAN_DET_SUPER_RES_TARGET_17_01";
BA_ "GenSigSendType" SG_ 304 CAN_DET_ND_TARGET_17_01 0;
BA_ "GenSigCmt" SG_ 304 CAN_DET_ND_TARGET_17_01 "CAN_DET_ND_TARGET_17_01";
BA_ "GenSigSendType" SG_ 304 CAN_DET_HOST_VEH_CLUTTER_17_01 0;
BA_ "GenSigCmt" SG_ 304 CAN_DET_HOST_VEH_CLUTTER_17_01 "CAN_DET_HOST_VEH_CLUTTER_17_01";
BA_ "GenSigSendType" SG_ 304 CAN_DET_VALID_LEVEL_17_01 0;
BA_ "GenSigCmt" SG_ 304 CAN_DET_VALID_LEVEL_17_01 "CAN_DET_VALID_LEVEL_17_01";
BA_ "GenSigSendType" SG_ 304 CAN_DET_AZIMUTH_17_01 0;
BA_ "GenSigCmt" SG_ 304 CAN_DET_AZIMUTH_17_01 "CAN_DET_AZIMUTH_17_01";
BA_ "GenSigSendType" SG_ 304 CAN_DET_RANGE_17_01 0;
BA_ "GenSigCmt" SG_ 304 CAN_DET_RANGE_17_01 "CAN_DET_RANGE_17_01";
BA_ "GenSigSendType" SG_ 304 CAN_DET_RANGE_RATE_17_01 0;
BA_ "GenSigCmt" SG_ 304 CAN_DET_RANGE_RATE_17_01 "CAN_DET_RANGE_RATE_17_01";
BA_ "GenSigSendType" SG_ 304 CAN_DET_AMPLITUDE_17_01 0;
BA_ "GenSigCmt" SG_ 304 CAN_DET_AMPLITUDE_17_01 "CAN_DET_AMPLITUDE_17_01";
BA_ "GenSigSendType" SG_ 304 CAN_SCAN_INDEX_2LSB_17_01 0;
BA_ "GenSigCmt" SG_ 304 CAN_SCAN_INDEX_2LSB_17_01 "CAN_SCAN_INDEX_2LSB_17_01";
BA_ "GenSigVtEn" SG_ 304 CAN_DET_CONFID_AZIMUTH_17_02 "CAN_DET_CONFID_AZIMUTH_17_02";
BA_ "GenSigVtName" SG_ 304 CAN_DET_CONFID_AZIMUTH_17_02 "CAN_DET_CONFID_AZIMUTH_17_02";
BA_ "GenSigSendType" SG_ 304 CAN_DET_CONFID_AZIMUTH_17_02 0;
BA_ "GenSigCmt" SG_ 304 CAN_DET_CONFID_AZIMUTH_17_02 "CAN_DET_CONFID_AZIMUTH_17_02";
BA_ "GenSigSendType" SG_ 304 CAN_DET_SUPER_RES_TARGET_17_02 0;
BA_ "GenSigCmt" SG_ 304 CAN_DET_SUPER_RES_TARGET_17_02 "CAN_DET_SUPER_RES_TARGET_17_02";
BA_ "GenSigSendType" SG_ 304 CAN_DET_ND_TARGET_17_02 0;
BA_ "GenSigCmt" SG_ 304 CAN_DET_ND_TARGET_17_02 "CAN_DET_ND_TARGET_17_02";
BA_ "GenSigSendType" SG_ 304 CAN_DET_HOST_VEH_CLUTTER_17_02 0;
BA_ "GenSigCmt" SG_ 304 CAN_DET_HOST_VEH_CLUTTER_17_02 "CAN_DET_HOST_VEH_CLUTTER_17_02";
BA_ "GenSigSendType" SG_ 304 CAN_DET_VALID_LEVEL_17_02 0;
BA_ "GenSigCmt" SG_ 304 CAN_DET_VALID_LEVEL_17_02 "CAN_DET_VALID_LEVEL_17_02";
BA_ "GenSigSendType" SG_ 304 CAN_DET_AZIMUTH_17_02 0;
BA_ "GenSigCmt" SG_ 304 CAN_DET_AZIMUTH_17_02 "CAN_DET_AZIMUTH_17_02";
BA_ "GenSigSendType" SG_ 304 CAN_DET_RANGE_17_02 0;
BA_ "GenSigCmt" SG_ 304 CAN_DET_RANGE_17_02 "CAN_DET_RANGE_17_02";
BA_ "GenSigSendType" SG_ 304 CAN_DET_RANGE_RATE_17_02 0;
BA_ "GenSigCmt" SG_ 304 CAN_DET_RANGE_RATE_17_02 "CAN_DET_RANGE_RATE_17_02";
BA_ "GenSigSendType" SG_ 304 CAN_DET_AMPLITUDE_17_02 0;
BA_ "GenSigCmt" SG_ 304 CAN_DET_AMPLITUDE_17_02 "CAN_DET_AMPLITUDE_17_02";
BA_ "GenSigSendType" SG_ 304 CAN_SCAN_INDEX_2LSB_17_02 0;
BA_ "GenSigCmt" SG_ 304 CAN_SCAN_INDEX_2LSB_17_02 "CAN_SCAN_INDEX_2LSB_17_02";
BA_ "GenSigVtEn" SG_ 304 CAN_DET_CONFID_AZIMUTH_17_03 "CAN_DET_CONFID_AZIMUTH_17_03";
BA_ "GenSigVtName" SG_ 304 CAN_DET_CONFID_AZIMUTH_17_03 "CAN_DET_CONFID_AZIMUTH_17_03";
BA_ "GenSigSendType" SG_ 304 CAN_DET_CONFID_AZIMUTH_17_03 0;
BA_ "GenSigCmt" SG_ 304 CAN_DET_CONFID_AZIMUTH_17_03 "CAN_DET_CONFID_AZIMUTH_17_03";
BA_ "GenSigSendType" SG_ 304 CAN_DET_SUPER_RES_TARGET_17_03 0;
BA_ "GenSigCmt" SG_ 304 CAN_DET_SUPER_RES_TARGET_17_03 "CAN_DET_SUPER_RES_TARGET_17_03";
BA_ "GenSigSendType" SG_ 304 CAN_DET_ND_TARGET_17_03 0;
BA_ "GenSigCmt" SG_ 304 CAN_DET_ND_TARGET_17_03 "CAN_DET_ND_TARGET_17_03";
BA_ "GenSigSendType" SG_ 304 CAN_DET_HOST_VEH_CLUTTER_17_03 0;
BA_ "GenSigCmt" SG_ 304 CAN_DET_HOST_VEH_CLUTTER_17_03 "CAN_DET_HOST_VEH_CLUTTER_17_03";
BA_ "GenSigSendType" SG_ 304 CAN_DET_VALID_LEVEL_17_03 0;
BA_ "GenSigCmt" SG_ 304 CAN_DET_VALID_LEVEL_17_03 "CAN_DET_VALID_LEVEL_17_03";
BA_ "GenSigSendType" SG_ 304 CAN_DET_AZIMUTH_17_03 0;
BA_ "GenSigCmt" SG_ 304 CAN_DET_AZIMUTH_17_03 "CAN_DET_AZIMUTH_17_03";
BA_ "GenSigSendType" SG_ 304 CAN_DET_RANGE_17_03 0;
BA_ "GenSigCmt" SG_ 304 CAN_DET_RANGE_17_03 "CAN_DET_RANGE_17_03";
BA_ "GenSigSendType" SG_ 304 CAN_DET_RANGE_RATE_17_03 0;
BA_ "GenSigCmt" SG_ 304 CAN_DET_RANGE_RATE_17_03 "CAN_DET_RANGE_RATE_17_03";
BA_ "GenSigSendType" SG_ 304 CAN_DET_AMPLITUDE_17_03 0;
BA_ "GenSigCmt" SG_ 304 CAN_DET_AMPLITUDE_17_03 "CAN_DET_AMPLITUDE_17_03";
BA_ "GenSigSendType" SG_ 304 CAN_SCAN_INDEX_2LSB_17_03 0;
BA_ "GenSigCmt" SG_ 304 CAN_SCAN_INDEX_2LSB_17_03 "CAN_SCAN_INDEX_2LSB_17_03";
BA_ "GenSigVtEn" SG_ 304 CAN_DET_CONFID_AZIMUTH_17_04 "CAN_DET_CONFID_AZIMUTH_17_04";
BA_ "GenSigVtName" SG_ 304 CAN_DET_CONFID_AZIMUTH_17_04 "CAN_DET_CONFID_AZIMUTH_17_04";
BA_ "GenSigSendType" SG_ 304 CAN_DET_CONFID_AZIMUTH_17_04 0;
BA_ "GenSigCmt" SG_ 304 CAN_DET_CONFID_AZIMUTH_17_04 "CAN_DET_CONFID_AZIMUTH_17_04";
BA_ "GenSigSendType" SG_ 304 CAN_DET_SUPER_RES_TARGET_17_04 0;
BA_ "GenSigCmt" SG_ 304 CAN_DET_SUPER_RES_TARGET_17_04 "CAN_DET_SUPER_RES_TARGET_17_04";
BA_ "GenSigSendType" SG_ 304 CAN_DET_ND_TARGET_17_04 0;
BA_ "GenSigCmt" SG_ 304 CAN_DET_ND_TARGET_17_04 "CAN_DET_ND_TARGET_17_04";
BA_ "GenSigSendType" SG_ 304 CAN_DET_HOST_VEH_CLUTTER_17_04 0;
BA_ "GenSigCmt" SG_ 304 CAN_DET_HOST_VEH_CLUTTER_17_04 "CAN_DET_HOST_VEH_CLUTTER_17_04";
BA_ "GenSigSendType" SG_ 304 CAN_DET_VALID_LEVEL_17_04 0;
BA_ "GenSigCmt" SG_ 304 CAN_DET_VALID_LEVEL_17_04 "CAN_DET_VALID_LEVEL_17_04";
BA_ "GenSigSendType" SG_ 304 CAN_DET_AZIMUTH_17_04 0;
BA_ "GenSigCmt" SG_ 304 CAN_DET_AZIMUTH_17_04 "CAN_DET_AZIMUTH_17_04";
BA_ "GenSigSendType" SG_ 304 CAN_DET_RANGE_17_04 0;
BA_ "GenSigCmt" SG_ 304 CAN_DET_RANGE_17_04 "CAN_DET_RANGE_17_04";
BA_ "GenSigSendType" SG_ 304 CAN_DET_RANGE_RATE_17_04 0;
BA_ "GenSigCmt" SG_ 304 CAN_DET_RANGE_RATE_17_04 "CAN_DET_RANGE_RATE_17_04";
BA_ "GenSigSendType" SG_ 304 CAN_DET_AMPLITUDE_17_04 0;
BA_ "GenSigCmt" SG_ 304 CAN_DET_AMPLITUDE_17_04 "CAN_DET_AMPLITUDE_17_04";
BA_ "GenSigSendType" SG_ 304 CAN_SCAN_INDEX_2LSB_17_04 0;
BA_ "GenSigCmt" SG_ 304 CAN_SCAN_INDEX_2LSB_17_04 "CAN_SCAN_INDEX_2LSB_17_04";
BA_ "GenSigVtEn" SG_ 304 CAN_DET_CONFID_AZIMUTH_17_05 "CAN_DET_CONFID_AZIMUTH_17_05";
BA_ "GenSigVtName" SG_ 304 CAN_DET_CONFID_AZIMUTH_17_05 "CAN_DET_CONFID_AZIMUTH_17_05";
BA_ "GenSigSendType" SG_ 304 CAN_DET_CONFID_AZIMUTH_17_05 0;
BA_ "GenSigCmt" SG_ 304 CAN_DET_CONFID_AZIMUTH_17_05 "CAN_DET_CONFID_AZIMUTH_17_05";
BA_ "GenSigSendType" SG_ 304 CAN_DET_SUPER_RES_TARGET_17_05 0;
BA_ "GenSigCmt" SG_ 304 CAN_DET_SUPER_RES_TARGET_17_05 "CAN_DET_SUPER_RES_TARGET_17_05";
BA_ "GenSigSendType" SG_ 304 CAN_DET_ND_TARGET_17_05 0;
BA_ "GenSigCmt" SG_ 304 CAN_DET_ND_TARGET_17_05 "CAN_DET_ND_TARGET_17_05";
BA_ "GenSigSendType" SG_ 304 CAN_DET_HOST_VEH_CLUTTER_17_05 0;
BA_ "GenSigCmt" SG_ 304 CAN_DET_HOST_VEH_CLUTTER_17_05 "CAN_DET_HOST_VEH_CLUTTER_17_05";
BA_ "GenSigSendType" SG_ 304 CAN_DET_VALID_LEVEL_17_05 0;
BA_ "GenSigCmt" SG_ 304 CAN_DET_VALID_LEVEL_17_05 "CAN_DET_VALID_LEVEL_17_05";
BA_ "GenSigSendType" SG_ 304 CAN_DET_AZIMUTH_17_05 0;
BA_ "GenSigCmt" SG_ 304 CAN_DET_AZIMUTH_17_05 "CAN_DET_AZIMUTH_17_05";
BA_ "GenSigSendType" SG_ 304 CAN_DET_RANGE_17_05 0;
BA_ "GenSigCmt" SG_ 304 CAN_DET_RANGE_17_05 "CAN_DET_RANGE_17_05";
BA_ "GenSigSendType" SG_ 304 CAN_DET_RANGE_RATE_17_05 0;
BA_ "GenSigCmt" SG_ 304 CAN_DET_RANGE_RATE_17_05 "CAN_DET_RANGE_RATE_17_05";
BA_ "GenSigSendType" SG_ 304 CAN_DET_AMPLITUDE_17_05 0;
BA_ "GenSigCmt" SG_ 304 CAN_DET_AMPLITUDE_17_05 "CAN_DET_AMPLITUDE_17_05";
BA_ "GenSigSendType" SG_ 304 CAN_SCAN_INDEX_2LSB_17_05 0;
BA_ "GenSigCmt" SG_ 304 CAN_SCAN_INDEX_2LSB_17_05 "CAN_SCAN_INDEX_2LSB_17_05";
BA_ "GenSigVtEn" SG_ 304 CAN_DET_CONFID_AZIMUTH_17_06 "CAN_DET_CONFID_AZIMUTH_17_06";
BA_ "GenSigVtName" SG_ 304 CAN_DET_CONFID_AZIMUTH_17_06 "CAN_DET_CONFID_AZIMUTH_17_06";
BA_ "GenSigSendType" SG_ 304 CAN_DET_CONFID_AZIMUTH_17_06 0;
BA_ "GenSigCmt" SG_ 304 CAN_DET_CONFID_AZIMUTH_17_06 "CAN_DET_CONFID_AZIMUTH_17_06";
BA_ "GenSigSendType" SG_ 304 CAN_DET_SUPER_RES_TARGET_17_06 0;
BA_ "GenSigCmt" SG_ 304 CAN_DET_SUPER_RES_TARGET_17_06 "CAN_DET_SUPER_RES_TARGET_17_06";
BA_ "GenSigSendType" SG_ 304 CAN_DET_ND_TARGET_17_06 0;
BA_ "GenSigCmt" SG_ 304 CAN_DET_ND_TARGET_17_06 "CAN_DET_ND_TARGET_17_06";
BA_ "GenSigSendType" SG_ 304 CAN_DET_HOST_VEH_CLUTTER_17_06 0;
BA_ "GenSigCmt" SG_ 304 CAN_DET_HOST_VEH_CLUTTER_17_06 "CAN_DET_HOST_VEH_CLUTTER_17_06";
BA_ "GenSigSendType" SG_ 304 CAN_DET_VALID_LEVEL_17_06 0;
BA_ "GenSigCmt" SG_ 304 CAN_DET_VALID_LEVEL_17_06 "CAN_DET_VALID_LEVEL_17_06";
BA_ "GenSigSendType" SG_ 304 CAN_DET_AZIMUTH_17_06 0;
BA_ "GenSigCmt" SG_ 304 CAN_DET_AZIMUTH_17_06 "CAN_DET_AZIMUTH_17_06";
BA_ "GenSigSendType" SG_ 304 CAN_DET_RANGE_17_06 0;
BA_ "GenSigCmt" SG_ 304 CAN_DET_RANGE_17_06 "CAN_DET_RANGE_17_06";
BA_ "GenSigSendType" SG_ 304 CAN_DET_RANGE_RATE_17_06 0;
BA_ "GenSigCmt" SG_ 304 CAN_DET_RANGE_RATE_17_06 "CAN_DET_RANGE_RATE_17_06";
BA_ "GenSigSendType" SG_ 304 CAN_DET_AMPLITUDE_17_06 0;
BA_ "GenSigCmt" SG_ 304 CAN_DET_AMPLITUDE_17_06 "CAN_DET_AMPLITUDE_17_06";
BA_ "GenSigSendType" SG_ 304 CAN_SCAN_INDEX_2LSB_17_06 0;
BA_ "GenSigCmt" SG_ 304 CAN_SCAN_INDEX_2LSB_17_06 "CAN_SCAN_INDEX_2LSB_17_06";
BA_ "GenMsgSendType" BO_ 303 1;
BA_ "GenSigVtEn" SG_ 303 CAN_DET_CONFID_AZIMUTH_16_01 "CAN_DET_CONFID_AZIMUTH_16_01";
BA_ "GenSigVtName" SG_ 303 CAN_DET_CONFID_AZIMUTH_16_01 "CAN_DET_CONFID_AZIMUTH_16_01";
BA_ "GenSigSendType" SG_ 303 CAN_DET_CONFID_AZIMUTH_16_01 0;
BA_ "GenSigCmt" SG_ 303 CAN_DET_CONFID_AZIMUTH_16_01 "CAN_DET_CONFID_AZIMUTH_16_01";
BA_ "GenSigSendType" SG_ 303 CAN_DET_SUPER_RES_TARGET_16_01 0;
BA_ "GenSigCmt" SG_ 303 CAN_DET_SUPER_RES_TARGET_16_01 "CAN_DET_SUPER_RES_TARGET_16_01";
BA_ "GenSigSendType" SG_ 303 CAN_DET_ND_TARGET_16_01 0;
BA_ "GenSigCmt" SG_ 303 CAN_DET_ND_TARGET_16_01 "CAN_DET_ND_TARGET_16_01";
BA_ "GenSigSendType" SG_ 303 CAN_DET_HOST_VEH_CLUTTER_16_01 0;
BA_ "GenSigCmt" SG_ 303 CAN_DET_HOST_VEH_CLUTTER_16_01 "CAN_DET_HOST_VEH_CLUTTER_16_01";
BA_ "GenSigSendType" SG_ 303 CAN_DET_VALID_LEVEL_16_01 0;
BA_ "GenSigCmt" SG_ 303 CAN_DET_VALID_LEVEL_16_01 "CAN_DET_VALID_LEVEL_16_01";
BA_ "GenSigSendType" SG_ 303 CAN_DET_AZIMUTH_16_01 0;
BA_ "GenSigCmt" SG_ 303 CAN_DET_AZIMUTH_16_01 "CAN_DET_AZIMUTH_16_01";
BA_ "GenSigSendType" SG_ 303 CAN_DET_RANGE_16_01 0;
BA_ "GenSigCmt" SG_ 303 CAN_DET_RANGE_16_01 "CAN_DET_RANGE_16_01";
BA_ "GenSigSendType" SG_ 303 CAN_DET_RANGE_RATE_16_01 0;
BA_ "GenSigCmt" SG_ 303 CAN_DET_RANGE_RATE_16_01 "CAN_DET_RANGE_RATE_16_01";
BA_ "GenSigSendType" SG_ 303 CAN_DET_AMPLITUDE_16_01 0;
BA_ "GenSigCmt" SG_ 303 CAN_DET_AMPLITUDE_16_01 "CAN_DET_AMPLITUDE_16_01";
BA_ "GenSigSendType" SG_ 303 CAN_SCAN_INDEX_2LSB_16_01 0;
BA_ "GenSigCmt" SG_ 303 CAN_SCAN_INDEX_2LSB_16_01 "CAN_SCAN_INDEX_2LSB_16_01";
BA_ "GenSigVtEn" SG_ 303 CAN_DET_CONFID_AZIMUTH_16_02 "CAN_DET_CONFID_AZIMUTH_16_02";
BA_ "GenSigVtName" SG_ 303 CAN_DET_CONFID_AZIMUTH_16_02 "CAN_DET_CONFID_AZIMUTH_16_02";
BA_ "GenSigSendType" SG_ 303 CAN_DET_CONFID_AZIMUTH_16_02 0;
BA_ "GenSigCmt" SG_ 303 CAN_DET_CONFID_AZIMUTH_16_02 "CAN_DET_CONFID_AZIMUTH_16_02";
BA_ "GenSigSendType" SG_ 303 CAN_DET_SUPER_RES_TARGET_16_02 0;
BA_ "GenSigCmt" SG_ 303 CAN_DET_SUPER_RES_TARGET_16_02 "CAN_DET_SUPER_RES_TARGET_16_02";
BA_ "GenSigSendType" SG_ 303 CAN_DET_ND_TARGET_16_02 0;
BA_ "GenSigCmt" SG_ 303 CAN_DET_ND_TARGET_16_02 "CAN_DET_ND_TARGET_16_02";
BA_ "GenSigSendType" SG_ 303 CAN_DET_HOST_VEH_CLUTTER_16_02 0;
BA_ "GenSigCmt" SG_ 303 CAN_DET_HOST_VEH_CLUTTER_16_02 "CAN_DET_HOST_VEH_CLUTTER_16_02";
BA_ "GenSigSendType" SG_ 303 CAN_DET_VALID_LEVEL_16_02 0;
BA_ "GenSigCmt" SG_ 303 CAN_DET_VALID_LEVEL_16_02 "CAN_DET_VALID_LEVEL_16_02";
BA_ "GenSigSendType" SG_ 303 CAN_DET_AZIMUTH_16_02 0;
BA_ "GenSigCmt" SG_ 303 CAN_DET_AZIMUTH_16_02 "CAN_DET_AZIMUTH_16_02";
BA_ "GenSigSendType" SG_ 303 CAN_DET_RANGE_16_02 0;
BA_ "GenSigCmt" SG_ 303 CAN_DET_RANGE_16_02 "CAN_DET_RANGE_16_02";
BA_ "GenSigSendType" SG_ 303 CAN_DET_RANGE_RATE_16_02 0;
BA_ "GenSigCmt" SG_ 303 CAN_DET_RANGE_RATE_16_02 "CAN_DET_RANGE_RATE_16_02";
BA_ "GenSigSendType" SG_ 303 CAN_DET_AMPLITUDE_16_02 0;
BA_ "GenSigCmt" SG_ 303 CAN_DET_AMPLITUDE_16_02 "CAN_DET_AMPLITUDE_16_02";
BA_ "GenSigSendType" SG_ 303 CAN_SCAN_INDEX_2LSB_16_02 0;
BA_ "GenSigCmt" SG_ 303 CAN_SCAN_INDEX_2LSB_16_02 "CAN_SCAN_INDEX_2LSB_16_02";
BA_ "GenSigVtEn" SG_ 303 CAN_DET_CONFID_AZIMUTH_16_03 "CAN_DET_CONFID_AZIMUTH_16_03";
BA_ "GenSigVtName" SG_ 303 CAN_DET_CONFID_AZIMUTH_16_03 "CAN_DET_CONFID_AZIMUTH_16_03";
BA_ "GenSigSendType" SG_ 303 CAN_DET_CONFID_AZIMUTH_16_03 0;
BA_ "GenSigCmt" SG_ 303 CAN_DET_CONFID_AZIMUTH_16_03 "CAN_DET_CONFID_AZIMUTH_16_03";
BA_ "GenSigSendType" SG_ 303 CAN_DET_SUPER_RES_TARGET_16_03 0;
BA_ "GenSigCmt" SG_ 303 CAN_DET_SUPER_RES_TARGET_16_03 "CAN_DET_SUPER_RES_TARGET_16_03";
BA_ "GenSigSendType" SG_ 303 CAN_DET_ND_TARGET_16_03 0;
BA_ "GenSigCmt" SG_ 303 CAN_DET_ND_TARGET_16_03 "CAN_DET_ND_TARGET_16_03";
BA_ "GenSigSendType" SG_ 303 CAN_DET_HOST_VEH_CLUTTER_16_03 0;
BA_ "GenSigCmt" SG_ 303 CAN_DET_HOST_VEH_CLUTTER_16_03 "CAN_DET_HOST_VEH_CLUTTER_16_03";
BA_ "GenSigSendType" SG_ 303 CAN_DET_VALID_LEVEL_16_03 0;
BA_ "GenSigCmt" SG_ 303 CAN_DET_VALID_LEVEL_16_03 "CAN_DET_VALID_LEVEL_16_03";
BA_ "GenSigSendType" SG_ 303 CAN_DET_AZIMUTH_16_03 0;
BA_ "GenSigCmt" SG_ 303 CAN_DET_AZIMUTH_16_03 "CAN_DET_AZIMUTH_16_03";
BA_ "GenSigSendType" SG_ 303 CAN_DET_RANGE_16_03 0;
BA_ "GenSigCmt" SG_ 303 CAN_DET_RANGE_16_03 "CAN_DET_RANGE_16_03";
BA_ "GenSigSendType" SG_ 303 CAN_DET_RANGE_RATE_16_03 0;
BA_ "GenSigCmt" SG_ 303 CAN_DET_RANGE_RATE_16_03 "CAN_DET_RANGE_RATE_16_03";
BA_ "GenSigSendType" SG_ 303 CAN_DET_AMPLITUDE_16_03 0;
BA_ "GenSigCmt" SG_ 303 CAN_DET_AMPLITUDE_16_03 "CAN_DET_AMPLITUDE_16_03";
BA_ "GenSigSendType" SG_ 303 CAN_SCAN_INDEX_2LSB_16_03 0;
BA_ "GenSigCmt" SG_ 303 CAN_SCAN_INDEX_2LSB_16_03 "CAN_SCAN_INDEX_2LSB_16_03";
BA_ "GenSigVtEn" SG_ 303 CAN_DET_CONFID_AZIMUTH_16_04 "CAN_DET_CONFID_AZIMUTH_16_04";
BA_ "GenSigVtName" SG_ 303 CAN_DET_CONFID_AZIMUTH_16_04 "CAN_DET_CONFID_AZIMUTH_16_04";
BA_ "GenSigSendType" SG_ 303 CAN_DET_CONFID_AZIMUTH_16_04 0;
BA_ "GenSigCmt" SG_ 303 CAN_DET_CONFID_AZIMUTH_16_04 "CAN_DET_CONFID_AZIMUTH_16_04";
BA_ "GenSigSendType" SG_ 303 CAN_DET_SUPER_RES_TARGET_16_04 0;
BA_ "GenSigCmt" SG_ 303 CAN_DET_SUPER_RES_TARGET_16_04 "CAN_DET_SUPER_RES_TARGET_16_04";
BA_ "GenSigSendType" SG_ 303 CAN_DET_ND_TARGET_16_04 0;
BA_ "GenSigCmt" SG_ 303 CAN_DET_ND_TARGET_16_04 "CAN_DET_ND_TARGET_16_04";
BA_ "GenSigSendType" SG_ 303 CAN_DET_HOST_VEH_CLUTTER_16_04 0;
BA_ "GenSigCmt" SG_ 303 CAN_DET_HOST_VEH_CLUTTER_16_04 "CAN_DET_HOST_VEH_CLUTTER_16_04";
BA_ "GenSigSendType" SG_ 303 CAN_DET_VALID_LEVEL_16_04 0;
BA_ "GenSigCmt" SG_ 303 CAN_DET_VALID_LEVEL_16_04 "CAN_DET_VALID_LEVEL_16_04";
BA_ "GenSigSendType" SG_ 303 CAN_DET_AZIMUTH_16_04 0;
BA_ "GenSigCmt" SG_ 303 CAN_DET_AZIMUTH_16_04 "CAN_DET_AZIMUTH_16_04";
BA_ "GenSigSendType" SG_ 303 CAN_DET_RANGE_16_04 0;
BA_ "GenSigCmt" SG_ 303 CAN_DET_RANGE_16_04 "CAN_DET_RANGE_16_04";
BA_ "GenSigSendType" SG_ 303 CAN_DET_RANGE_RATE_16_04 0;
BA_ "GenSigCmt" SG_ 303 CAN_DET_RANGE_RATE_16_04 "CAN_DET_RANGE_RATE_16_04";
BA_ "GenSigSendType" SG_ 303 CAN_DET_AMPLITUDE_16_04 0;
BA_ "GenSigCmt" SG_ 303 CAN_DET_AMPLITUDE_16_04 "CAN_DET_AMPLITUDE_16_04";
BA_ "GenSigSendType" SG_ 303 CAN_SCAN_INDEX_2LSB_16_04 0;
BA_ "GenSigCmt" SG_ 303 CAN_SCAN_INDEX_2LSB_16_04 "CAN_SCAN_INDEX_2LSB_16_04";
BA_ "GenSigVtEn" SG_ 303 CAN_DET_CONFID_AZIMUTH_16_05 "CAN_DET_CONFID_AZIMUTH_16_05";
BA_ "GenSigVtName" SG_ 303 CAN_DET_CONFID_AZIMUTH_16_05 "CAN_DET_CONFID_AZIMUTH_16_05";
BA_ "GenSigSendType" SG_ 303 CAN_DET_CONFID_AZIMUTH_16_05 0;
BA_ "GenSigCmt" SG_ 303 CAN_DET_CONFID_AZIMUTH_16_05 "CAN_DET_CONFID_AZIMUTH_16_05";
BA_ "GenSigSendType" SG_ 303 CAN_DET_SUPER_RES_TARGET_16_05 0;
BA_ "GenSigCmt" SG_ 303 CAN_DET_SUPER_RES_TARGET_16_05 "CAN_DET_SUPER_RES_TARGET_16_05";
BA_ "GenSigSendType" SG_ 303 CAN_DET_ND_TARGET_16_05 0;
BA_ "GenSigCmt" SG_ 303 CAN_DET_ND_TARGET_16_05 "CAN_DET_ND_TARGET_16_05";
BA_ "GenSigSendType" SG_ 303 CAN_DET_HOST_VEH_CLUTTER_16_05 0;
BA_ "GenSigCmt" SG_ 303 CAN_DET_HOST_VEH_CLUTTER_16_05 "CAN_DET_HOST_VEH_CLUTTER_16_05";
BA_ "GenSigSendType" SG_ 303 CAN_DET_VALID_LEVEL_16_05 0;
BA_ "GenSigCmt" SG_ 303 CAN_DET_VALID_LEVEL_16_05 "CAN_DET_VALID_LEVEL_16_05";
BA_ "GenSigSendType" SG_ 303 CAN_DET_AZIMUTH_16_05 0;
BA_ "GenSigCmt" SG_ 303 CAN_DET_AZIMUTH_16_05 "CAN_DET_AZIMUTH_16_05";
BA_ "GenSigSendType" SG_ 303 CAN_DET_RANGE_16_05 0;
BA_ "GenSigCmt" SG_ 303 CAN_DET_RANGE_16_05 "CAN_DET_RANGE_16_05";
BA_ "GenSigSendType" SG_ 303 CAN_DET_RANGE_RATE_16_05 0;
BA_ "GenSigCmt" SG_ 303 CAN_DET_RANGE_RATE_16_05 "CAN_DET_RANGE_RATE_16_05";
BA_ "GenSigSendType" SG_ 303 CAN_DET_AMPLITUDE_16_05 0;
BA_ "GenSigCmt" SG_ 303 CAN_DET_AMPLITUDE_16_05 "CAN_DET_AMPLITUDE_16_05";
BA_ "GenSigSendType" SG_ 303 CAN_SCAN_INDEX_2LSB_16_05 0;
BA_ "GenSigCmt" SG_ 303 CAN_SCAN_INDEX_2LSB_16_05 "CAN_SCAN_INDEX_2LSB_16_05";
BA_ "GenSigVtEn" SG_ 303 CAN_DET_CONFID_AZIMUTH_16_06 "CAN_DET_CONFID_AZIMUTH_16_06";
BA_ "GenSigVtName" SG_ 303 CAN_DET_CONFID_AZIMUTH_16_06 "CAN_DET_CONFID_AZIMUTH_16_06";
BA_ "GenSigSendType" SG_ 303 CAN_DET_CONFID_AZIMUTH_16_06 0;
BA_ "GenSigCmt" SG_ 303 CAN_DET_CONFID_AZIMUTH_16_06 "CAN_DET_CONFID_AZIMUTH_16_06";
BA_ "GenSigSendType" SG_ 303 CAN_DET_SUPER_RES_TARGET_16_06 0;
BA_ "GenSigCmt" SG_ 303 CAN_DET_SUPER_RES_TARGET_16_06 "CAN_DET_SUPER_RES_TARGET_16_06";
BA_ "GenSigSendType" SG_ 303 CAN_DET_ND_TARGET_16_06 0;
BA_ "GenSigCmt" SG_ 303 CAN_DET_ND_TARGET_16_06 "CAN_DET_ND_TARGET_16_06";
BA_ "GenSigSendType" SG_ 303 CAN_DET_HOST_VEH_CLUTTER_16_06 0;
BA_ "GenSigCmt" SG_ 303 CAN_DET_HOST_VEH_CLUTTER_16_06 "CAN_DET_HOST_VEH_CLUTTER_16_06";
BA_ "GenSigSendType" SG_ 303 CAN_DET_VALID_LEVEL_16_06 0;
BA_ "GenSigCmt" SG_ 303 CAN_DET_VALID_LEVEL_16_06 "CAN_DET_VALID_LEVEL_16_06";
BA_ "GenSigSendType" SG_ 303 CAN_DET_AZIMUTH_16_06 0;
BA_ "GenSigCmt" SG_ 303 CAN_DET_AZIMUTH_16_06 "CAN_DET_AZIMUTH_16_06";
BA_ "GenSigSendType" SG_ 303 CAN_DET_RANGE_16_06 0;
BA_ "GenSigCmt" SG_ 303 CAN_DET_RANGE_16_06 "CAN_DET_RANGE_16_06";
BA_ "GenSigSendType" SG_ 303 CAN_DET_RANGE_RATE_16_06 0;
BA_ "GenSigCmt" SG_ 303 CAN_DET_RANGE_RATE_16_06 "CAN_DET_RANGE_RATE_16_06";
BA_ "GenSigSendType" SG_ 303 CAN_DET_AMPLITUDE_16_06 0;
BA_ "GenSigCmt" SG_ 303 CAN_DET_AMPLITUDE_16_06 "CAN_DET_AMPLITUDE_16_06";
BA_ "GenSigSendType" SG_ 303 CAN_SCAN_INDEX_2LSB_16_06 0;
BA_ "GenSigCmt" SG_ 303 CAN_SCAN_INDEX_2LSB_16_06 "CAN_SCAN_INDEX_2LSB_16_06";
BA_ "GenMsgSendType" BO_ 302 1;
BA_ "GenSigVtEn" SG_ 302 CAN_DET_CONFID_AZIMUTH_15_01 "CAN_DET_CONFID_AZIMUTH_15_01";
BA_ "GenSigVtName" SG_ 302 CAN_DET_CONFID_AZIMUTH_15_01 "CAN_DET_CONFID_AZIMUTH_15_01";
BA_ "GenSigSendType" SG_ 302 CAN_DET_CONFID_AZIMUTH_15_01 0;
BA_ "GenSigCmt" SG_ 302 CAN_DET_CONFID_AZIMUTH_15_01 "CAN_DET_CONFID_AZIMUTH_15_01";
BA_ "GenSigSendType" SG_ 302 CAN_DET_SUPER_RES_TARGET_15_01 0;
BA_ "GenSigCmt" SG_ 302 CAN_DET_SUPER_RES_TARGET_15_01 "CAN_DET_SUPER_RES_TARGET_15_01";
BA_ "GenSigSendType" SG_ 302 CAN_DET_ND_TARGET_15_01 0;
BA_ "GenSigCmt" SG_ 302 CAN_DET_ND_TARGET_15_01 "CAN_DET_ND_TARGET_15_01";
BA_ "GenSigSendType" SG_ 302 CAN_DET_HOST_VEH_CLUTTER_15_01 0;
BA_ "GenSigCmt" SG_ 302 CAN_DET_HOST_VEH_CLUTTER_15_01 "CAN_DET_HOST_VEH_CLUTTER_15_01";
BA_ "GenSigSendType" SG_ 302 CAN_DET_VALID_LEVEL_15_01 0;
BA_ "GenSigCmt" SG_ 302 CAN_DET_VALID_LEVEL_15_01 "CAN_DET_VALID_LEVEL_15_01";
BA_ "GenSigSendType" SG_ 302 CAN_DET_AZIMUTH_15_01 0;
BA_ "GenSigCmt" SG_ 302 CAN_DET_AZIMUTH_15_01 "CAN_DET_AZIMUTH_15_01";
BA_ "GenSigSendType" SG_ 302 CAN_DET_RANGE_15_01 0;
BA_ "GenSigCmt" SG_ 302 CAN_DET_RANGE_15_01 "CAN_DET_RANGE_15_01";
BA_ "GenSigSendType" SG_ 302 CAN_DET_RANGE_RATE_15_01 0;
BA_ "GenSigCmt" SG_ 302 CAN_DET_RANGE_RATE_15_01 "CAN_DET_RANGE_RATE_15_01";
BA_ "GenSigSendType" SG_ 302 CAN_DET_AMPLITUDE_15_01 0;
BA_ "GenSigCmt" SG_ 302 CAN_DET_AMPLITUDE_15_01 "CAN_DET_AMPLITUDE_15_01";
BA_ "GenSigSendType" SG_ 302 CAN_SCAN_INDEX_2LSB_15_01 0;
BA_ "GenSigCmt" SG_ 302 CAN_SCAN_INDEX_2LSB_15_01 "CAN_SCAN_INDEX_2LSB_15_01";
BA_ "GenSigVtEn" SG_ 302 CAN_DET_CONFID_AZIMUTH_15_02 "CAN_DET_CONFID_AZIMUTH_15_02";
BA_ "GenSigVtName" SG_ 302 CAN_DET_CONFID_AZIMUTH_15_02 "CAN_DET_CONFID_AZIMUTH_15_02";
BA_ "GenSigSendType" SG_ 302 CAN_DET_CONFID_AZIMUTH_15_02 0;
BA_ "GenSigCmt" SG_ 302 CAN_DET_CONFID_AZIMUTH_15_02 "CAN_DET_CONFID_AZIMUTH_15_02";
BA_ "GenSigSendType" SG_ 302 CAN_DET_SUPER_RES_TARGET_15_02 0;
BA_ "GenSigCmt" SG_ 302 CAN_DET_SUPER_RES_TARGET_15_02 "CAN_DET_SUPER_RES_TARGET_15_02";
BA_ "GenSigSendType" SG_ 302 CAN_DET_ND_TARGET_15_02 0;
BA_ "GenSigCmt" SG_ 302 CAN_DET_ND_TARGET_15_02 "CAN_DET_ND_TARGET_15_02";
BA_ "GenSigSendType" SG_ 302 CAN_DET_HOST_VEH_CLUTTER_15_02 0;
BA_ "GenSigCmt" SG_ 302 CAN_DET_HOST_VEH_CLUTTER_15_02 "CAN_DET_HOST_VEH_CLUTTER_15_02";
BA_ "GenSigSendType" SG_ 302 CAN_DET_VALID_LEVEL_15_02 0;
BA_ "GenSigCmt" SG_ 302 CAN_DET_VALID_LEVEL_15_02 "CAN_DET_VALID_LEVEL_15_02";
BA_ "GenSigSendType" SG_ 302 CAN_DET_AZIMUTH_15_02 0;
BA_ "GenSigCmt" SG_ 302 CAN_DET_AZIMUTH_15_02 "CAN_DET_AZIMUTH_15_02";
BA_ "GenSigSendType" SG_ 302 CAN_DET_RANGE_15_02 0;
BA_ "GenSigCmt" SG_ 302 CAN_DET_RANGE_15_02 "CAN_DET_RANGE_15_02";
BA_ "GenSigSendType" SG_ 302 CAN_DET_RANGE_RATE_15_02 0;
BA_ "GenSigCmt" SG_ 302 CAN_DET_RANGE_RATE_15_02 "CAN_DET_RANGE_RATE_15_02";
BA_ "GenSigSendType" SG_ 302 CAN_DET_AMPLITUDE_15_02 0;
BA_ "GenSigCmt" SG_ 302 CAN_DET_AMPLITUDE_15_02 "CAN_DET_AMPLITUDE_15_02";
BA_ "GenSigSendType" SG_ 302 CAN_SCAN_INDEX_2LSB_15_02 0;
BA_ "GenSigCmt" SG_ 302 CAN_SCAN_INDEX_2LSB_15_02 "CAN_SCAN_INDEX_2LSB_15_02";
BA_ "GenSigVtEn" SG_ 302 CAN_DET_CONFID_AZIMUTH_15_03 "CAN_DET_CONFID_AZIMUTH_15_03";
BA_ "GenSigVtName" SG_ 302 CAN_DET_CONFID_AZIMUTH_15_03 "CAN_DET_CONFID_AZIMUTH_15_03";
BA_ "GenSigSendType" SG_ 302 CAN_DET_CONFID_AZIMUTH_15_03 0;
BA_ "GenSigCmt" SG_ 302 CAN_DET_CONFID_AZIMUTH_15_03 "CAN_DET_CONFID_AZIMUTH_15_03";
BA_ "GenSigSendType" SG_ 302 CAN_DET_SUPER_RES_TARGET_15_03 0;
BA_ "GenSigCmt" SG_ 302 CAN_DET_SUPER_RES_TARGET_15_03 "CAN_DET_SUPER_RES_TARGET_15_03";
BA_ "GenSigSendType" SG_ 302 CAN_DET_ND_TARGET_15_03 0;
BA_ "GenSigCmt" SG_ 302 CAN_DET_ND_TARGET_15_03 "CAN_DET_ND_TARGET_15_03";
BA_ "GenSigSendType" SG_ 302 CAN_DET_HOST_VEH_CLUTTER_15_03 0;
BA_ "GenSigCmt" SG_ 302 CAN_DET_HOST_VEH_CLUTTER_15_03 "CAN_DET_HOST_VEH_CLUTTER_15_03";
BA_ "GenSigSendType" SG_ 302 CAN_DET_VALID_LEVEL_15_03 0;
BA_ "GenSigCmt" SG_ 302 CAN_DET_VALID_LEVEL_15_03 "CAN_DET_VALID_LEVEL_15_03";
BA_ "GenSigSendType" SG_ 302 CAN_DET_AZIMUTH_15_03 0;
BA_ "GenSigCmt" SG_ 302 CAN_DET_AZIMUTH_15_03 "CAN_DET_AZIMUTH_15_03";
BA_ "GenSigSendType" SG_ 302 CAN_DET_RANGE_15_03 0;
BA_ "GenSigCmt" SG_ 302 CAN_DET_RANGE_15_03 "CAN_DET_RANGE_15_03";
BA_ "GenSigSendType" SG_ 302 CAN_DET_RANGE_RATE_15_03 0;
BA_ "GenSigCmt" SG_ 302 CAN_DET_RANGE_RATE_15_03 "CAN_DET_RANGE_RATE_15_03";
BA_ "GenSigSendType" SG_ 302 CAN_DET_AMPLITUDE_15_03 0;
BA_ "GenSigCmt" SG_ 302 CAN_DET_AMPLITUDE_15_03 "CAN_DET_AMPLITUDE_15_03";
BA_ "GenSigSendType" SG_ 302 CAN_SCAN_INDEX_2LSB_15_03 0;
BA_ "GenSigCmt" SG_ 302 CAN_SCAN_INDEX_2LSB_15_03 "CAN_SCAN_INDEX_2LSB_15_03";
BA_ "GenSigVtEn" SG_ 302 CAN_DET_CONFID_AZIMUTH_15_04 "CAN_DET_CONFID_AZIMUTH_15_04";
BA_ "GenSigVtName" SG_ 302 CAN_DET_CONFID_AZIMUTH_15_04 "CAN_DET_CONFID_AZIMUTH_15_04";
BA_ "GenSigSendType" SG_ 302 CAN_DET_CONFID_AZIMUTH_15_04 0;
BA_ "GenSigCmt" SG_ 302 CAN_DET_CONFID_AZIMUTH_15_04 "CAN_DET_CONFID_AZIMUTH_15_04";
BA_ "GenSigSendType" SG_ 302 CAN_DET_SUPER_RES_TARGET_15_04 0;
BA_ "GenSigCmt" SG_ 302 CAN_DET_SUPER_RES_TARGET_15_04 "CAN_DET_SUPER_RES_TARGET_15_04";
BA_ "GenSigSendType" SG_ 302 CAN_DET_ND_TARGET_15_04 0;
BA_ "GenSigCmt" SG_ 302 CAN_DET_ND_TARGET_15_04 "CAN_DET_ND_TARGET_15_04";
BA_ "GenSigSendType" SG_ 302 CAN_DET_HOST_VEH_CLUTTER_15_04 0;
BA_ "GenSigCmt" SG_ 302 CAN_DET_HOST_VEH_CLUTTER_15_04 "CAN_DET_HOST_VEH_CLUTTER_15_04";
BA_ "GenSigSendType" SG_ 302 CAN_DET_VALID_LEVEL_15_04 0;
BA_ "GenSigCmt" SG_ 302 CAN_DET_VALID_LEVEL_15_04 "CAN_DET_VALID_LEVEL_15_04";
BA_ "GenSigSendType" SG_ 302 CAN_DET_AZIMUTH_15_04 0;
BA_ "GenSigCmt" SG_ 302 CAN_DET_AZIMUTH_15_04 "CAN_DET_AZIMUTH_15_04";
BA_ "GenSigSendType" SG_ 302 CAN_DET_RANGE_15_04 0;
BA_ "GenSigCmt" SG_ 302 CAN_DET_RANGE_15_04 "CAN_DET_RANGE_15_04";
BA_ "GenSigSendType" SG_ 302 CAN_DET_RANGE_RATE_15_04 0;
BA_ "GenSigCmt" SG_ 302 CAN_DET_RANGE_RATE_15_04 "CAN_DET_RANGE_RATE_15_04";
BA_ "GenSigSendType" SG_ 302 CAN_DET_AMPLITUDE_15_04 0;
BA_ "GenSigCmt" SG_ 302 CAN_DET_AMPLITUDE_15_04 "CAN_DET_AMPLITUDE_15_04";
BA_ "GenSigSendType" SG_ 302 CAN_SCAN_INDEX_2LSB_15_04 0;
BA_ "GenSigCmt" SG_ 302 CAN_SCAN_INDEX_2LSB_15_04 "CAN_SCAN_INDEX_2LSB_15_04";
BA_ "GenSigVtEn" SG_ 302 CAN_DET_CONFID_AZIMUTH_15_05 "CAN_DET_CONFID_AZIMUTH_15_05";
BA_ "GenSigVtName" SG_ 302 CAN_DET_CONFID_AZIMUTH_15_05 "CAN_DET_CONFID_AZIMUTH_15_05";
BA_ "GenSigSendType" SG_ 302 CAN_DET_CONFID_AZIMUTH_15_05 0;
BA_ "GenSigCmt" SG_ 302 CAN_DET_CONFID_AZIMUTH_15_05 "CAN_DET_CONFID_AZIMUTH_15_05";
BA_ "GenSigSendType" SG_ 302 CAN_DET_SUPER_RES_TARGET_15_05 0;
BA_ "GenSigCmt" SG_ 302 CAN_DET_SUPER_RES_TARGET_15_05 "CAN_DET_SUPER_RES_TARGET_15_05";
BA_ "GenSigSendType" SG_ 302 CAN_DET_ND_TARGET_15_05 0;
BA_ "GenSigCmt" SG_ 302 CAN_DET_ND_TARGET_15_05 "CAN_DET_ND_TARGET_15_05";
BA_ "GenSigSendType" SG_ 302 CAN_DET_HOST_VEH_CLUTTER_15_05 0;
BA_ "GenSigCmt" SG_ 302 CAN_DET_HOST_VEH_CLUTTER_15_05 "CAN_DET_HOST_VEH_CLUTTER_15_05";
BA_ "GenSigSendType" SG_ 302 CAN_DET_VALID_LEVEL_15_05 0;
BA_ "GenSigCmt" SG_ 302 CAN_DET_VALID_LEVEL_15_05 "CAN_DET_VALID_LEVEL_15_05";
BA_ "GenSigSendType" SG_ 302 CAN_DET_AZIMUTH_15_05 0;
BA_ "GenSigCmt" SG_ 302 CAN_DET_AZIMUTH_15_05 "CAN_DET_AZIMUTH_15_05";
BA_ "GenSigSendType" SG_ 302 CAN_DET_RANGE_15_05 0;
BA_ "GenSigCmt" SG_ 302 CAN_DET_RANGE_15_05 "CAN_DET_RANGE_15_05";
BA_ "GenSigSendType" SG_ 302 CAN_DET_RANGE_RATE_15_05 0;
BA_ "GenSigCmt" SG_ 302 CAN_DET_RANGE_RATE_15_05 "CAN_DET_RANGE_RATE_15_05";
BA_ "GenSigSendType" SG_ 302 CAN_DET_AMPLITUDE_15_05 0;
BA_ "GenSigCmt" SG_ 302 CAN_DET_AMPLITUDE_15_05 "CAN_DET_AMPLITUDE_15_05";
BA_ "GenSigSendType" SG_ 302 CAN_SCAN_INDEX_2LSB_15_05 0;
BA_ "GenSigCmt" SG_ 302 CAN_SCAN_INDEX_2LSB_15_05 "CAN_SCAN_INDEX_2LSB_15_05";
BA_ "GenSigVtEn" SG_ 302 CAN_DET_CONFID_AZIMUTH_15_06 "CAN_DET_CONFID_AZIMUTH_15_06";
BA_ "GenSigVtName" SG_ 302 CAN_DET_CONFID_AZIMUTH_15_06 "CAN_DET_CONFID_AZIMUTH_15_06";
BA_ "GenSigSendType" SG_ 302 CAN_DET_CONFID_AZIMUTH_15_06 0;
BA_ "GenSigCmt" SG_ 302 CAN_DET_CONFID_AZIMUTH_15_06 "CAN_DET_CONFID_AZIMUTH_15_06";
BA_ "GenSigSendType" SG_ 302 CAN_DET_SUPER_RES_TARGET_15_06 0;
BA_ "GenSigCmt" SG_ 302 CAN_DET_SUPER_RES_TARGET_15_06 "CAN_DET_SUPER_RES_TARGET_15_06";
BA_ "GenSigSendType" SG_ 302 CAN_DET_ND_TARGET_15_06 0;
BA_ "GenSigCmt" SG_ 302 CAN_DET_ND_TARGET_15_06 "CAN_DET_ND_TARGET_15_06";
BA_ "GenSigSendType" SG_ 302 CAN_DET_HOST_VEH_CLUTTER_15_06 0;
BA_ "GenSigCmt" SG_ 302 CAN_DET_HOST_VEH_CLUTTER_15_06 "CAN_DET_HOST_VEH_CLUTTER_15_06";
BA_ "GenSigSendType" SG_ 302 CAN_DET_VALID_LEVEL_15_06 0;
BA_ "GenSigCmt" SG_ 302 CAN_DET_VALID_LEVEL_15_06 "CAN_DET_VALID_LEVEL_15_06";
BA_ "GenSigSendType" SG_ 302 CAN_DET_AZIMUTH_15_06 0;
BA_ "GenSigCmt" SG_ 302 CAN_DET_AZIMUTH_15_06 "CAN_DET_AZIMUTH_15_06";
BA_ "GenSigSendType" SG_ 302 CAN_DET_RANGE_15_06 0;
BA_ "GenSigCmt" SG_ 302 CAN_DET_RANGE_15_06 "CAN_DET_RANGE_15_06";
BA_ "GenSigSendType" SG_ 302 CAN_DET_RANGE_RATE_15_06 0;
BA_ "GenSigCmt" SG_ 302 CAN_DET_RANGE_RATE_15_06 "CAN_DET_RANGE_RATE_15_06";
BA_ "GenSigSendType" SG_ 302 CAN_DET_AMPLITUDE_15_06 0;
BA_ "GenSigCmt" SG_ 302 CAN_DET_AMPLITUDE_15_06 "CAN_DET_AMPLITUDE_15_06";
BA_ "GenSigSendType" SG_ 302 CAN_SCAN_INDEX_2LSB_15_06 0;
BA_ "GenSigCmt" SG_ 302 CAN_SCAN_INDEX_2LSB_15_06 "CAN_SCAN_INDEX_2LSB_15_06";
BA_ "GenMsgSendType" BO_ 301 1;
BA_ "GenSigVtEn" SG_ 301 CAN_DET_CONFID_AZIMUTH_14_01 "CAN_DET_CONFID_AZIMUTH_14_01";
BA_ "GenSigVtName" SG_ 301 CAN_DET_CONFID_AZIMUTH_14_01 "CAN_DET_CONFID_AZIMUTH_14_01";
BA_ "GenSigSendType" SG_ 301 CAN_DET_CONFID_AZIMUTH_14_01 0;
BA_ "GenSigCmt" SG_ 301 CAN_DET_CONFID_AZIMUTH_14_01 "CAN_DET_CONFID_AZIMUTH_14_01";
BA_ "GenSigSendType" SG_ 301 CAN_DET_SUPER_RES_TARGET_14_01 0;
BA_ "GenSigCmt" SG_ 301 CAN_DET_SUPER_RES_TARGET_14_01 "CAN_DET_SUPER_RES_TARGET_14_01";
BA_ "GenSigSendType" SG_ 301 CAN_DET_ND_TARGET_14_01 0;
BA_ "GenSigCmt" SG_ 301 CAN_DET_ND_TARGET_14_01 "CAN_DET_ND_TARGET_14_01";
BA_ "GenSigSendType" SG_ 301 CAN_DET_HOST_VEH_CLUTTER_14_01 0;
BA_ "GenSigCmt" SG_ 301 CAN_DET_HOST_VEH_CLUTTER_14_01 "CAN_DET_HOST_VEH_CLUTTER_14_01";
BA_ "GenSigSendType" SG_ 301 CAN_DET_VALID_LEVEL_14_01 0;
BA_ "GenSigCmt" SG_ 301 CAN_DET_VALID_LEVEL_14_01 "CAN_DET_VALID_LEVEL_14_01";
BA_ "GenSigSendType" SG_ 301 CAN_DET_AZIMUTH_14_01 0;
BA_ "GenSigCmt" SG_ 301 CAN_DET_AZIMUTH_14_01 "CAN_DET_AZIMUTH_14_01";
BA_ "GenSigSendType" SG_ 301 CAN_DET_RANGE_14_01 0;
BA_ "GenSigCmt" SG_ 301 CAN_DET_RANGE_14_01 "CAN_DET_RANGE_14_01";
BA_ "GenSigSendType" SG_ 301 CAN_DET_RANGE_RATE_14_01 0;
BA_ "GenSigCmt" SG_ 301 CAN_DET_RANGE_RATE_14_01 "CAN_DET_RANGE_RATE_14_01";
BA_ "GenSigSendType" SG_ 301 CAN_DET_AMPLITUDE_14_01 0;
BA_ "GenSigCmt" SG_ 301 CAN_DET_AMPLITUDE_14_01 "CAN_DET_AMPLITUDE_14_01";
BA_ "GenSigSendType" SG_ 301 CAN_SCAN_INDEX_2LSB_14_01 0;
BA_ "GenSigCmt" SG_ 301 CAN_SCAN_INDEX_2LSB_14_01 "CAN_SCAN_INDEX_2LSB_14_01";
BA_ "GenSigVtEn" SG_ 301 CAN_DET_CONFID_AZIMUTH_14_02 "CAN_DET_CONFID_AZIMUTH_14_02";
BA_ "GenSigVtName" SG_ 301 CAN_DET_CONFID_AZIMUTH_14_02 "CAN_DET_CONFID_AZIMUTH_14_02";
BA_ "GenSigSendType" SG_ 301 CAN_DET_CONFID_AZIMUTH_14_02 0;
BA_ "GenSigCmt" SG_ 301 CAN_DET_CONFID_AZIMUTH_14_02 "CAN_DET_CONFID_AZIMUTH_14_02";
BA_ "GenSigSendType" SG_ 301 CAN_DET_SUPER_RES_TARGET_14_02 0;
BA_ "GenSigCmt" SG_ 301 CAN_DET_SUPER_RES_TARGET_14_02 "CAN_DET_SUPER_RES_TARGET_14_02";
BA_ "GenSigSendType" SG_ 301 CAN_DET_ND_TARGET_14_02 0;
BA_ "GenSigCmt" SG_ 301 CAN_DET_ND_TARGET_14_02 "CAN_DET_ND_TARGET_14_02";
BA_ "GenSigSendType" SG_ 301 CAN_DET_HOST_VEH_CLUTTER_14_02 0;
BA_ "GenSigCmt" SG_ 301 CAN_DET_HOST_VEH_CLUTTER_14_02 "CAN_DET_HOST_VEH_CLUTTER_14_02";
BA_ "GenSigSendType" SG_ 301 CAN_DET_VALID_LEVEL_14_02 0;
BA_ "GenSigCmt" SG_ 301 CAN_DET_VALID_LEVEL_14_02 "CAN_DET_VALID_LEVEL_14_02";
BA_ "GenSigSendType" SG_ 301 CAN_DET_AZIMUTH_14_02 0;
BA_ "GenSigCmt" SG_ 301 CAN_DET_AZIMUTH_14_02 "CAN_DET_AZIMUTH_14_02";
BA_ "GenSigSendType" SG_ 301 CAN_DET_RANGE_14_02 0;
BA_ "GenSigCmt" SG_ 301 CAN_DET_RANGE_14_02 "CAN_DET_RANGE_14_02";
BA_ "GenSigSendType" SG_ 301 CAN_DET_RANGE_RATE_14_02 0;
BA_ "GenSigCmt" SG_ 301 CAN_DET_RANGE_RATE_14_02 "CAN_DET_RANGE_RATE_14_02";
BA_ "GenSigSendType" SG_ 301 CAN_DET_AMPLITUDE_14_02 0;
BA_ "GenSigCmt" SG_ 301 CAN_DET_AMPLITUDE_14_02 "CAN_DET_AMPLITUDE_14_02";
BA_ "GenSigSendType" SG_ 301 CAN_SCAN_INDEX_2LSB_14_02 0;
BA_ "GenSigCmt" SG_ 301 CAN_SCAN_INDEX_2LSB_14_02 "CAN_SCAN_INDEX_2LSB_14_02";
BA_ "GenSigVtEn" SG_ 301 CAN_DET_CONFID_AZIMUTH_14_03 "CAN_DET_CONFID_AZIMUTH_14_03";
BA_ "GenSigVtName" SG_ 301 CAN_DET_CONFID_AZIMUTH_14_03 "CAN_DET_CONFID_AZIMUTH_14_03";
BA_ "GenSigSendType" SG_ 301 CAN_DET_CONFID_AZIMUTH_14_03 0;
BA_ "GenSigCmt" SG_ 301 CAN_DET_CONFID_AZIMUTH_14_03 "CAN_DET_CONFID_AZIMUTH_14_03";
BA_ "GenSigSendType" SG_ 301 CAN_DET_SUPER_RES_TARGET_14_03 0;
BA_ "GenSigCmt" SG_ 301 CAN_DET_SUPER_RES_TARGET_14_03 "CAN_DET_SUPER_RES_TARGET_14_03";
BA_ "GenSigSendType" SG_ 301 CAN_DET_ND_TARGET_14_03 0;
BA_ "GenSigCmt" SG_ 301 CAN_DET_ND_TARGET_14_03 "CAN_DET_ND_TARGET_14_03";
BA_ "GenSigSendType" SG_ 301 CAN_DET_HOST_VEH_CLUTTER_14_03 0;
BA_ "GenSigCmt" SG_ 301 CAN_DET_HOST_VEH_CLUTTER_14_03 "CAN_DET_HOST_VEH_CLUTTER_14_03";
BA_ "GenSigSendType" SG_ 301 CAN_DET_VALID_LEVEL_14_03 0;
BA_ "GenSigCmt" SG_ 301 CAN_DET_VALID_LEVEL_14_03 "CAN_DET_VALID_LEVEL_14_03";
BA_ "GenSigSendType" SG_ 301 CAN_DET_AZIMUTH_14_03 0;
BA_ "GenSigCmt" SG_ 301 CAN_DET_AZIMUTH_14_03 "CAN_DET_AZIMUTH_14_03";
BA_ "GenSigSendType" SG_ 301 CAN_DET_RANGE_14_03 0;
BA_ "GenSigCmt" SG_ 301 CAN_DET_RANGE_14_03 "CAN_DET_RANGE_14_03";
BA_ "GenSigSendType" SG_ 301 CAN_DET_RANGE_RATE_14_03 0;
BA_ "GenSigCmt" SG_ 301 CAN_DET_RANGE_RATE_14_03 "CAN_DET_RANGE_RATE_14_03";
BA_ "GenSigSendType" SG_ 301 CAN_DET_AMPLITUDE_14_03 0;
BA_ "GenSigCmt" SG_ 301 CAN_DET_AMPLITUDE_14_03 "CAN_DET_AMPLITUDE_14_03";
BA_ "GenSigSendType" SG_ 301 CAN_SCAN_INDEX_2LSB_14_03 0;
BA_ "GenSigCmt" SG_ 301 CAN_SCAN_INDEX_2LSB_14_03 "CAN_SCAN_INDEX_2LSB_14_03";
BA_ "GenSigVtEn" SG_ 301 CAN_DET_CONFID_AZIMUTH_14_04 "CAN_DET_CONFID_AZIMUTH_14_04";
BA_ "GenSigVtName" SG_ 301 CAN_DET_CONFID_AZIMUTH_14_04 "CAN_DET_CONFID_AZIMUTH_14_04";
BA_ "GenSigSendType" SG_ 301 CAN_DET_CONFID_AZIMUTH_14_04 0;
BA_ "GenSigCmt" SG_ 301 CAN_DET_CONFID_AZIMUTH_14_04 "CAN_DET_CONFID_AZIMUTH_14_04";
BA_ "GenSigSendType" SG_ 301 CAN_DET_SUPER_RES_TARGET_14_04 0;
BA_ "GenSigCmt" SG_ 301 CAN_DET_SUPER_RES_TARGET_14_04 "CAN_DET_SUPER_RES_TARGET_14_04";
BA_ "GenSigSendType" SG_ 301 CAN_DET_ND_TARGET_14_04 0;
BA_ "GenSigCmt" SG_ 301 CAN_DET_ND_TARGET_14_04 "CAN_DET_ND_TARGET_14_04";
BA_ "GenSigSendType" SG_ 301 CAN_DET_HOST_VEH_CLUTTER_14_04 0;
BA_ "GenSigCmt" SG_ 301 CAN_DET_HOST_VEH_CLUTTER_14_04 "CAN_DET_HOST_VEH_CLUTTER_14_04";
BA_ "GenSigSendType" SG_ 301 CAN_DET_VALID_LEVEL_14_04 0;
BA_ "GenSigCmt" SG_ 301 CAN_DET_VALID_LEVEL_14_04 "CAN_DET_VALID_LEVEL_14_04";
BA_ "GenSigSendType" SG_ 301 CAN_DET_AZIMUTH_14_04 0;
BA_ "GenSigCmt" SG_ 301 CAN_DET_AZIMUTH_14_04 "CAN_DET_AZIMUTH_14_04";
BA_ "GenSigSendType" SG_ 301 CAN_DET_RANGE_14_04 0;
BA_ "GenSigCmt" SG_ 301 CAN_DET_RANGE_14_04 "CAN_DET_RANGE_14_04";
BA_ "GenSigSendType" SG_ 301 CAN_DET_RANGE_RATE_14_04 0;
BA_ "GenSigCmt" SG_ 301 CAN_DET_RANGE_RATE_14_04 "CAN_DET_RANGE_RATE_14_04";
BA_ "GenSigSendType" SG_ 301 CAN_DET_AMPLITUDE_14_04 0;
BA_ "GenSigCmt" SG_ 301 CAN_DET_AMPLITUDE_14_04 "CAN_DET_AMPLITUDE_14_04";
BA_ "GenSigSendType" SG_ 301 CAN_SCAN_INDEX_2LSB_14_04 0;
BA_ "GenSigCmt" SG_ 301 CAN_SCAN_INDEX_2LSB_14_04 "CAN_SCAN_INDEX_2LSB_14_04";
BA_ "GenSigVtEn" SG_ 301 CAN_DET_CONFID_AZIMUTH_14_05 "CAN_DET_CONFID_AZIMUTH_14_05";
BA_ "GenSigVtName" SG_ 301 CAN_DET_CONFID_AZIMUTH_14_05 "CAN_DET_CONFID_AZIMUTH_14_05";
BA_ "GenSigSendType" SG_ 301 CAN_DET_CONFID_AZIMUTH_14_05 0;
BA_ "GenSigCmt" SG_ 301 CAN_DET_CONFID_AZIMUTH_14_05 "CAN_DET_CONFID_AZIMUTH_14_05";
BA_ "GenSigSendType" SG_ 301 CAN_DET_SUPER_RES_TARGET_14_05 0;
BA_ "GenSigCmt" SG_ 301 CAN_DET_SUPER_RES_TARGET_14_05 "CAN_DET_SUPER_RES_TARGET_14_05";
BA_ "GenSigSendType" SG_ 301 CAN_DET_ND_TARGET_14_05 0;
BA_ "GenSigCmt" SG_ 301 CAN_DET_ND_TARGET_14_05 "CAN_DET_ND_TARGET_14_05";
BA_ "GenSigSendType" SG_ 301 CAN_DET_HOST_VEH_CLUTTER_14_05 0;
BA_ "GenSigCmt" SG_ 301 CAN_DET_HOST_VEH_CLUTTER_14_05 "CAN_DET_HOST_VEH_CLUTTER_14_05";
BA_ "GenSigSendType" SG_ 301 CAN_DET_VALID_LEVEL_14_05 0;
BA_ "GenSigCmt" SG_ 301 CAN_DET_VALID_LEVEL_14_05 "CAN_DET_VALID_LEVEL_14_05";
BA_ "GenSigSendType" SG_ 301 CAN_DET_AZIMUTH_14_05 0;
BA_ "GenSigCmt" SG_ 301 CAN_DET_AZIMUTH_14_05 "CAN_DET_AZIMUTH_14_05";
BA_ "GenSigSendType" SG_ 301 CAN_DET_RANGE_14_05 0;
BA_ "GenSigCmt" SG_ 301 CAN_DET_RANGE_14_05 "CAN_DET_RANGE_14_05";
BA_ "GenSigSendType" SG_ 301 CAN_DET_RANGE_RATE_14_05 0;
BA_ "GenSigCmt" SG_ 301 CAN_DET_RANGE_RATE_14_05 "CAN_DET_RANGE_RATE_14_05";
BA_ "GenSigSendType" SG_ 301 CAN_DET_AMPLITUDE_14_05 0;
BA_ "GenSigCmt" SG_ 301 CAN_DET_AMPLITUDE_14_05 "CAN_DET_AMPLITUDE_14_05";
BA_ "GenSigSendType" SG_ 301 CAN_SCAN_INDEX_2LSB_14_05 0;
BA_ "GenSigCmt" SG_ 301 CAN_SCAN_INDEX_2LSB_14_05 "CAN_SCAN_INDEX_2LSB_14_05";
BA_ "GenSigVtEn" SG_ 301 CAN_DET_CONFID_AZIMUTH_14_06 "CAN_DET_CONFID_AZIMUTH_14_06";
BA_ "GenSigVtName" SG_ 301 CAN_DET_CONFID_AZIMUTH_14_06 "CAN_DET_CONFID_AZIMUTH_14_06";
BA_ "GenSigSendType" SG_ 301 CAN_DET_CONFID_AZIMUTH_14_06 0;
BA_ "GenSigCmt" SG_ 301 CAN_DET_CONFID_AZIMUTH_14_06 "CAN_DET_CONFID_AZIMUTH_14_06";
BA_ "GenSigSendType" SG_ 301 CAN_DET_SUPER_RES_TARGET_14_06 0;
BA_ "GenSigCmt" SG_ 301 CAN_DET_SUPER_RES_TARGET_14_06 "CAN_DET_SUPER_RES_TARGET_14_06";
BA_ "GenSigSendType" SG_ 301 CAN_DET_ND_TARGET_14_06 0;
BA_ "GenSigCmt" SG_ 301 CAN_DET_ND_TARGET_14_06 "CAN_DET_ND_TARGET_14_06";
BA_ "GenSigSendType" SG_ 301 CAN_DET_HOST_VEH_CLUTTER_14_06 0;
BA_ "GenSigCmt" SG_ 301 CAN_DET_HOST_VEH_CLUTTER_14_06 "CAN_DET_HOST_VEH_CLUTTER_14_06";
BA_ "GenSigSendType" SG_ 301 CAN_DET_VALID_LEVEL_14_06 0;
BA_ "GenSigCmt" SG_ 301 CAN_DET_VALID_LEVEL_14_06 "CAN_DET_VALID_LEVEL_14_06";
BA_ "GenSigSendType" SG_ 301 CAN_DET_AZIMUTH_14_06 0;
BA_ "GenSigCmt" SG_ 301 CAN_DET_AZIMUTH_14_06 "CAN_DET_AZIMUTH_14_06";
BA_ "GenSigSendType" SG_ 301 CAN_DET_RANGE_14_06 0;
BA_ "GenSigCmt" SG_ 301 CAN_DET_RANGE_14_06 "CAN_DET_RANGE_14_06";
BA_ "GenSigSendType" SG_ 301 CAN_DET_RANGE_RATE_14_06 0;
BA_ "GenSigCmt" SG_ 301 CAN_DET_RANGE_RATE_14_06 "CAN_DET_RANGE_RATE_14_06";
BA_ "GenSigSendType" SG_ 301 CAN_DET_AMPLITUDE_14_06 0;
BA_ "GenSigCmt" SG_ 301 CAN_DET_AMPLITUDE_14_06 "CAN_DET_AMPLITUDE_14_06";
BA_ "GenSigSendType" SG_ 301 CAN_SCAN_INDEX_2LSB_14_06 0;
BA_ "GenSigCmt" SG_ 301 CAN_SCAN_INDEX_2LSB_14_06 "CAN_SCAN_INDEX_2LSB_14_06";
BA_ "GenMsgSendType" BO_ 300 1;
BA_ "GenSigVtEn" SG_ 300 CAN_DET_CONFID_AZIMUTH_13_01 "CAN_DET_CONFID_AZIMUTH_13_01";
BA_ "GenSigVtName" SG_ 300 CAN_DET_CONFID_AZIMUTH_13_01 "CAN_DET_CONFID_AZIMUTH_13_01";
BA_ "GenSigSendType" SG_ 300 CAN_DET_CONFID_AZIMUTH_13_01 0;
BA_ "GenSigCmt" SG_ 300 CAN_DET_CONFID_AZIMUTH_13_01 "CAN_DET_CONFID_AZIMUTH_13_01";
BA_ "GenSigSendType" SG_ 300 CAN_DET_SUPER_RES_TARGET_13_01 0;
BA_ "GenSigCmt" SG_ 300 CAN_DET_SUPER_RES_TARGET_13_01 "CAN_DET_SUPER_RES_TARGET_13_01";
BA_ "GenSigSendType" SG_ 300 CAN_DET_ND_TARGET_13_01 0;
BA_ "GenSigCmt" SG_ 300 CAN_DET_ND_TARGET_13_01 "CAN_DET_ND_TARGET_13_01";
BA_ "GenSigSendType" SG_ 300 CAN_DET_HOST_VEH_CLUTTER_13_01 0;
BA_ "GenSigCmt" SG_ 300 CAN_DET_HOST_VEH_CLUTTER_13_01 "CAN_DET_HOST_VEH_CLUTTER_13_01";
BA_ "GenSigSendType" SG_ 300 CAN_DET_VALID_LEVEL_13_01 0;
BA_ "GenSigCmt" SG_ 300 CAN_DET_VALID_LEVEL_13_01 "CAN_DET_VALID_LEVEL_13_01";
BA_ "GenSigSendType" SG_ 300 CAN_DET_AZIMUTH_13_01 0;
BA_ "GenSigCmt" SG_ 300 CAN_DET_AZIMUTH_13_01 "CAN_DET_AZIMUTH_13_01";
BA_ "GenSigSendType" SG_ 300 CAN_DET_RANGE_13_01 0;
BA_ "GenSigCmt" SG_ 300 CAN_DET_RANGE_13_01 "CAN_DET_RANGE_13_01";
BA_ "GenSigSendType" SG_ 300 CAN_DET_RANGE_RATE_13_01 0;
BA_ "GenSigCmt" SG_ 300 CAN_DET_RANGE_RATE_13_01 "CAN_DET_RANGE_RATE_13_01";
BA_ "GenSigSendType" SG_ 300 CAN_DET_AMPLITUDE_13_01 0;
BA_ "GenSigCmt" SG_ 300 CAN_DET_AMPLITUDE_13_01 "CAN_DET_AMPLITUDE_13_01";
BA_ "GenSigSendType" SG_ 300 CAN_SCAN_INDEX_2LSB_13_01 0;
BA_ "GenSigCmt" SG_ 300 CAN_SCAN_INDEX_2LSB_13_01 "CAN_SCAN_INDEX_2LSB_13_01";
BA_ "GenSigVtEn" SG_ 300 CAN_DET_CONFID_AZIMUTH_13_02 "CAN_DET_CONFID_AZIMUTH_13_02";
BA_ "GenSigVtName" SG_ 300 CAN_DET_CONFID_AZIMUTH_13_02 "CAN_DET_CONFID_AZIMUTH_13_02";
BA_ "GenSigSendType" SG_ 300 CAN_DET_CONFID_AZIMUTH_13_02 0;
BA_ "GenSigCmt" SG_ 300 CAN_DET_CONFID_AZIMUTH_13_02 "CAN_DET_CONFID_AZIMUTH_13_02";
BA_ "GenSigSendType" SG_ 300 CAN_DET_SUPER_RES_TARGET_13_02 0;
BA_ "GenSigCmt" SG_ 300 CAN_DET_SUPER_RES_TARGET_13_02 "CAN_DET_SUPER_RES_TARGET_13_02";
BA_ "GenSigSendType" SG_ 300 CAN_DET_ND_TARGET_13_02 0;
BA_ "GenSigCmt" SG_ 300 CAN_DET_ND_TARGET_13_02 "CAN_DET_ND_TARGET_13_02";
BA_ "GenSigSendType" SG_ 300 CAN_DET_HOST_VEH_CLUTTER_13_02 0;
BA_ "GenSigCmt" SG_ 300 CAN_DET_HOST_VEH_CLUTTER_13_02 "CAN_DET_HOST_VEH_CLUTTER_13_02";
BA_ "GenSigSendType" SG_ 300 CAN_DET_VALID_LEVEL_13_02 0;
BA_ "GenSigCmt" SG_ 300 CAN_DET_VALID_LEVEL_13_02 "CAN_DET_VALID_LEVEL_13_02";
BA_ "GenSigSendType" SG_ 300 CAN_DET_AZIMUTH_13_02 0;
BA_ "GenSigCmt" SG_ 300 CAN_DET_AZIMUTH_13_02 "CAN_DET_AZIMUTH_13_02";
BA_ "GenSigSendType" SG_ 300 CAN_DET_RANGE_13_02 0;
BA_ "GenSigCmt" SG_ 300 CAN_DET_RANGE_13_02 "CAN_DET_RANGE_13_02";
BA_ "GenSigSendType" SG_ 300 CAN_DET_RANGE_RATE_13_02 0;
BA_ "GenSigCmt" SG_ 300 CAN_DET_RANGE_RATE_13_02 "CAN_DET_RANGE_RATE_13_02";
BA_ "GenSigSendType" SG_ 300 CAN_DET_AMPLITUDE_13_02 0;
BA_ "GenSigCmt" SG_ 300 CAN_DET_AMPLITUDE_13_02 "CAN_DET_AMPLITUDE_13_02";
BA_ "GenSigSendType" SG_ 300 CAN_SCAN_INDEX_2LSB_13_02 0;
BA_ "GenSigCmt" SG_ 300 CAN_SCAN_INDEX_2LSB_13_02 "CAN_SCAN_INDEX_2LSB_13_02";
BA_ "GenSigVtEn" SG_ 300 CAN_DET_CONFID_AZIMUTH_13_03 "CAN_DET_CONFID_AZIMUTH_13_03";
BA_ "GenSigVtName" SG_ 300 CAN_DET_CONFID_AZIMUTH_13_03 "CAN_DET_CONFID_AZIMUTH_13_03";
BA_ "GenSigSendType" SG_ 300 CAN_DET_CONFID_AZIMUTH_13_03 0;
BA_ "GenSigCmt" SG_ 300 CAN_DET_CONFID_AZIMUTH_13_03 "CAN_DET_CONFID_AZIMUTH_13_03";
BA_ "GenSigSendType" SG_ 300 CAN_DET_SUPER_RES_TARGET_13_03 0;
BA_ "GenSigCmt" SG_ 300 CAN_DET_SUPER_RES_TARGET_13_03 "CAN_DET_SUPER_RES_TARGET_13_03";
BA_ "GenSigSendType" SG_ 300 CAN_DET_ND_TARGET_13_03 0;
BA_ "GenSigCmt" SG_ 300 CAN_DET_ND_TARGET_13_03 "CAN_DET_ND_TARGET_13_03";
BA_ "GenSigSendType" SG_ 300 CAN_DET_HOST_VEH_CLUTTER_13_03 0;
BA_ "GenSigCmt" SG_ 300 CAN_DET_HOST_VEH_CLUTTER_13_03 "CAN_DET_HOST_VEH_CLUTTER_13_03";
BA_ "GenSigSendType" SG_ 300 CAN_DET_VALID_LEVEL_13_03 0;
BA_ "GenSigCmt" SG_ 300 CAN_DET_VALID_LEVEL_13_03 "CAN_DET_VALID_LEVEL_13_03";
BA_ "GenSigSendType" SG_ 300 CAN_DET_AZIMUTH_13_03 0;
BA_ "GenSigCmt" SG_ 300 CAN_DET_AZIMUTH_13_03 "CAN_DET_AZIMUTH_13_03";
BA_ "GenSigSendType" SG_ 300 CAN_DET_RANGE_13_03 0;
BA_ "GenSigCmt" SG_ 300 CAN_DET_RANGE_13_03 "CAN_DET_RANGE_13_03";
BA_ "GenSigSendType" SG_ 300 CAN_DET_RANGE_RATE_13_03 0;
BA_ "GenSigCmt" SG_ 300 CAN_DET_RANGE_RATE_13_03 "CAN_DET_RANGE_RATE_13_03";
BA_ "GenSigSendType" SG_ 300 CAN_DET_AMPLITUDE_13_03 0;
BA_ "GenSigCmt" SG_ 300 CAN_DET_AMPLITUDE_13_03 "CAN_DET_AMPLITUDE_13_03";
BA_ "GenSigSendType" SG_ 300 CAN_SCAN_INDEX_2LSB_13_03 0;
BA_ "GenSigCmt" SG_ 300 CAN_SCAN_INDEX_2LSB_13_03 "CAN_SCAN_INDEX_2LSB_13_03";
BA_ "GenSigVtEn" SG_ 300 CAN_DET_CONFID_AZIMUTH_13_04 "CAN_DET_CONFID_AZIMUTH_13_04";
BA_ "GenSigVtName" SG_ 300 CAN_DET_CONFID_AZIMUTH_13_04 "CAN_DET_CONFID_AZIMUTH_13_04";
BA_ "GenSigSendType" SG_ 300 CAN_DET_CONFID_AZIMUTH_13_04 0;
BA_ "GenSigCmt" SG_ 300 CAN_DET_CONFID_AZIMUTH_13_04 "CAN_DET_CONFID_AZIMUTH_13_04";
BA_ "GenSigSendType" SG_ 300 CAN_DET_SUPER_RES_TARGET_13_04 0;
BA_ "GenSigCmt" SG_ 300 CAN_DET_SUPER_RES_TARGET_13_04 "CAN_DET_SUPER_RES_TARGET_13_04";
BA_ "GenSigSendType" SG_ 300 CAN_DET_ND_TARGET_13_04 0;
BA_ "GenSigCmt" SG_ 300 CAN_DET_ND_TARGET_13_04 "CAN_DET_ND_TARGET_13_04";
BA_ "GenSigSendType" SG_ 300 CAN_DET_HOST_VEH_CLUTTER_13_04 0;
BA_ "GenSigCmt" SG_ 300 CAN_DET_HOST_VEH_CLUTTER_13_04 "CAN_DET_HOST_VEH_CLUTTER_13_04";
BA_ "GenSigSendType" SG_ 300 CAN_DET_VALID_LEVEL_13_04 0;
BA_ "GenSigCmt" SG_ 300 CAN_DET_VALID_LEVEL_13_04 "CAN_DET_VALID_LEVEL_13_04";
BA_ "GenSigSendType" SG_ 300 CAN_DET_AZIMUTH_13_04 0;
BA_ "GenSigCmt" SG_ 300 CAN_DET_AZIMUTH_13_04 "CAN_DET_AZIMUTH_13_04";
BA_ "GenSigSendType" SG_ 300 CAN_DET_RANGE_13_04 0;
BA_ "GenSigCmt" SG_ 300 CAN_DET_RANGE_13_04 "CAN_DET_RANGE_13_04";
BA_ "GenSigSendType" SG_ 300 CAN_DET_RANGE_RATE_13_04 0;
BA_ "GenSigCmt" SG_ 300 CAN_DET_RANGE_RATE_13_04 "CAN_DET_RANGE_RATE_13_04";
BA_ "GenSigSendType" SG_ 300 CAN_DET_AMPLITUDE_13_04 0;
BA_ "GenSigCmt" SG_ 300 CAN_DET_AMPLITUDE_13_04 "CAN_DET_AMPLITUDE_13_04";
BA_ "GenSigSendType" SG_ 300 CAN_SCAN_INDEX_2LSB_13_04 0;
BA_ "GenSigCmt" SG_ 300 CAN_SCAN_INDEX_2LSB_13_04 "CAN_SCAN_INDEX_2LSB_13_04";
BA_ "GenSigVtEn" SG_ 300 CAN_DET_CONFID_AZIMUTH_13_05 "CAN_DET_CONFID_AZIMUTH_13_05";
BA_ "GenSigVtName" SG_ 300 CAN_DET_CONFID_AZIMUTH_13_05 "CAN_DET_CONFID_AZIMUTH_13_05";
BA_ "GenSigSendType" SG_ 300 CAN_DET_CONFID_AZIMUTH_13_05 0;
BA_ "GenSigCmt" SG_ 300 CAN_DET_CONFID_AZIMUTH_13_05 "CAN_DET_CONFID_AZIMUTH_13_05";
BA_ "GenSigSendType" SG_ 300 CAN_DET_SUPER_RES_TARGET_13_05 0;
BA_ "GenSigCmt" SG_ 300 CAN_DET_SUPER_RES_TARGET_13_05 "CAN_DET_SUPER_RES_TARGET_13_05";
BA_ "GenSigSendType" SG_ 300 CAN_DET_ND_TARGET_13_05 0;
BA_ "GenSigCmt" SG_ 300 CAN_DET_ND_TARGET_13_05 "CAN_DET_ND_TARGET_13_05";
BA_ "GenSigSendType" SG_ 300 CAN_DET_HOST_VEH_CLUTTER_13_05 0;
BA_ "GenSigCmt" SG_ 300 CAN_DET_HOST_VEH_CLUTTER_13_05 "CAN_DET_HOST_VEH_CLUTTER_13_05";
BA_ "GenSigSendType" SG_ 300 CAN_DET_VALID_LEVEL_13_05 0;
BA_ "GenSigCmt" SG_ 300 CAN_DET_VALID_LEVEL_13_05 "CAN_DET_VALID_LEVEL_13_05";
BA_ "GenSigSendType" SG_ 300 CAN_DET_AZIMUTH_13_05 0;
BA_ "GenSigCmt" SG_ 300 CAN_DET_AZIMUTH_13_05 "CAN_DET_AZIMUTH_13_05";
BA_ "GenSigSendType" SG_ 300 CAN_DET_RANGE_13_05 0;
BA_ "GenSigCmt" SG_ 300 CAN_DET_RANGE_13_05 "CAN_DET_RANGE_13_05";
BA_ "GenSigSendType" SG_ 300 CAN_DET_RANGE_RATE_13_05 0;
BA_ "GenSigCmt" SG_ 300 CAN_DET_RANGE_RATE_13_05 "CAN_DET_RANGE_RATE_13_05";
BA_ "GenSigSendType" SG_ 300 CAN_DET_AMPLITUDE_13_05 0;
BA_ "GenSigCmt" SG_ 300 CAN_DET_AMPLITUDE_13_05 "CAN_DET_AMPLITUDE_13_05";
BA_ "GenSigSendType" SG_ 300 CAN_SCAN_INDEX_2LSB_13_05 0;
BA_ "GenSigCmt" SG_ 300 CAN_SCAN_INDEX_2LSB_13_05 "CAN_SCAN_INDEX_2LSB_13_05";
BA_ "GenSigVtEn" SG_ 300 CAN_DET_CONFID_AZIMUTH_13_06 "CAN_DET_CONFID_AZIMUTH_13_06";
BA_ "GenSigVtName" SG_ 300 CAN_DET_CONFID_AZIMUTH_13_06 "CAN_DET_CONFID_AZIMUTH_13_06";
BA_ "GenSigSendType" SG_ 300 CAN_DET_CONFID_AZIMUTH_13_06 0;
BA_ "GenSigCmt" SG_ 300 CAN_DET_CONFID_AZIMUTH_13_06 "CAN_DET_CONFID_AZIMUTH_13_06";
BA_ "GenSigSendType" SG_ 300 CAN_DET_SUPER_RES_TARGET_13_06 0;
BA_ "GenSigCmt" SG_ 300 CAN_DET_SUPER_RES_TARGET_13_06 "CAN_DET_SUPER_RES_TARGET_13_06";
BA_ "GenSigSendType" SG_ 300 CAN_DET_ND_TARGET_13_06 0;
BA_ "GenSigCmt" SG_ 300 CAN_DET_ND_TARGET_13_06 "CAN_DET_ND_TARGET_13_06";
BA_ "GenSigSendType" SG_ 300 CAN_DET_HOST_VEH_CLUTTER_13_06 0;
BA_ "GenSigCmt" SG_ 300 CAN_DET_HOST_VEH_CLUTTER_13_06 "CAN_DET_HOST_VEH_CLUTTER_13_06";
BA_ "GenSigSendType" SG_ 300 CAN_DET_VALID_LEVEL_13_06 0;
BA_ "GenSigCmt" SG_ 300 CAN_DET_VALID_LEVEL_13_06 "CAN_DET_VALID_LEVEL_13_06";
BA_ "GenSigSendType" SG_ 300 CAN_DET_AZIMUTH_13_06 0;
BA_ "GenSigCmt" SG_ 300 CAN_DET_AZIMUTH_13_06 "CAN_DET_AZIMUTH_13_06";
BA_ "GenSigSendType" SG_ 300 CAN_DET_RANGE_13_06 0;
BA_ "GenSigCmt" SG_ 300 CAN_DET_RANGE_13_06 "CAN_DET_RANGE_13_06";
BA_ "GenSigSendType" SG_ 300 CAN_DET_RANGE_RATE_13_06 0;
BA_ "GenSigCmt" SG_ 300 CAN_DET_RANGE_RATE_13_06 "CAN_DET_RANGE_RATE_13_06";
BA_ "GenSigSendType" SG_ 300 CAN_DET_AMPLITUDE_13_06 0;
BA_ "GenSigCmt" SG_ 300 CAN_DET_AMPLITUDE_13_06 "CAN_DET_AMPLITUDE_13_06";
BA_ "GenSigSendType" SG_ 300 CAN_SCAN_INDEX_2LSB_13_06 0;
BA_ "GenSigCmt" SG_ 300 CAN_SCAN_INDEX_2LSB_13_06 "CAN_SCAN_INDEX_2LSB_13_06";
BA_ "GenMsgSendType" BO_ 299 1;
BA_ "GenSigVtEn" SG_ 299 CAN_DET_CONFID_AZIMUTH_12_01 "CAN_DET_CONFID_AZIMUTH_12_01";
BA_ "GenSigVtName" SG_ 299 CAN_DET_CONFID_AZIMUTH_12_01 "CAN_DET_CONFID_AZIMUTH_12_01";
BA_ "GenSigSendType" SG_ 299 CAN_DET_CONFID_AZIMUTH_12_01 0;
BA_ "GenSigCmt" SG_ 299 CAN_DET_CONFID_AZIMUTH_12_01 "CAN_DET_CONFID_AZIMUTH_12_01";
BA_ "GenSigSendType" SG_ 299 CAN_DET_SUPER_RES_TARGET_12_01 0;
BA_ "GenSigCmt" SG_ 299 CAN_DET_SUPER_RES_TARGET_12_01 "CAN_DET_SUPER_RES_TARGET_12_01";
BA_ "GenSigSendType" SG_ 299 CAN_DET_ND_TARGET_12_01 0;
BA_ "GenSigCmt" SG_ 299 CAN_DET_ND_TARGET_12_01 "CAN_DET_ND_TARGET_12_01";
BA_ "GenSigSendType" SG_ 299 CAN_DET_HOST_VEH_CLUTTER_12_01 0;
BA_ "GenSigCmt" SG_ 299 CAN_DET_HOST_VEH_CLUTTER_12_01 "CAN_DET_HOST_VEH_CLUTTER_12_01";
BA_ "GenSigSendType" SG_ 299 CAN_DET_VALID_LEVEL_12_01 0;
BA_ "GenSigCmt" SG_ 299 CAN_DET_VALID_LEVEL_12_01 "CAN_DET_VALID_LEVEL_12_01";
BA_ "GenSigSendType" SG_ 299 CAN_DET_AZIMUTH_12_01 0;
BA_ "GenSigCmt" SG_ 299 CAN_DET_AZIMUTH_12_01 "CAN_DET_AZIMUTH_12_01";
BA_ "GenSigSendType" SG_ 299 CAN_DET_RANGE_12_01 0;
BA_ "GenSigCmt" SG_ 299 CAN_DET_RANGE_12_01 "CAN_DET_RANGE_12_01";
BA_ "GenSigSendType" SG_ 299 CAN_DET_RANGE_RATE_12_01 0;
BA_ "GenSigCmt" SG_ 299 CAN_DET_RANGE_RATE_12_01 "CAN_DET_RANGE_RATE_12_01";
BA_ "GenSigSendType" SG_ 299 CAN_DET_AMPLITUDE_12_01 0;
BA_ "GenSigCmt" SG_ 299 CAN_DET_AMPLITUDE_12_01 "CAN_DET_AMPLITUDE_12_01";
BA_ "GenSigSendType" SG_ 299 CAN_SCAN_INDEX_2LSB_12_01 0;
BA_ "GenSigCmt" SG_ 299 CAN_SCAN_INDEX_2LSB_12_01 "CAN_SCAN_INDEX_2LSB_12_01";
BA_ "GenSigVtEn" SG_ 299 CAN_DET_CONFID_AZIMUTH_12_02 "CAN_DET_CONFID_AZIMUTH_12_02";
BA_ "GenSigVtName" SG_ 299 CAN_DET_CONFID_AZIMUTH_12_02 "CAN_DET_CONFID_AZIMUTH_12_02";
BA_ "GenSigSendType" SG_ 299 CAN_DET_CONFID_AZIMUTH_12_02 0;
BA_ "GenSigCmt" SG_ 299 CAN_DET_CONFID_AZIMUTH_12_02 "CAN_DET_CONFID_AZIMUTH_12_02";
BA_ "GenSigSendType" SG_ 299 CAN_DET_SUPER_RES_TARGET_12_02 0;
BA_ "GenSigCmt" SG_ 299 CAN_DET_SUPER_RES_TARGET_12_02 "CAN_DET_SUPER_RES_TARGET_12_02";
BA_ "GenSigSendType" SG_ 299 CAN_DET_ND_TARGET_12_02 0;
BA_ "GenSigCmt" SG_ 299 CAN_DET_ND_TARGET_12_02 "CAN_DET_ND_TARGET_12_02";
BA_ "GenSigSendType" SG_ 299 CAN_DET_HOST_VEH_CLUTTER_12_02 0;
BA_ "GenSigCmt" SG_ 299 CAN_DET_HOST_VEH_CLUTTER_12_02 "CAN_DET_HOST_VEH_CLUTTER_12_02";
BA_ "GenSigSendType" SG_ 299 CAN_DET_VALID_LEVEL_12_02 0;
BA_ "GenSigCmt" SG_ 299 CAN_DET_VALID_LEVEL_12_02 "CAN_DET_VALID_LEVEL_12_02";
BA_ "GenSigSendType" SG_ 299 CAN_DET_AZIMUTH_12_02 0;
BA_ "GenSigCmt" SG_ 299 CAN_DET_AZIMUTH_12_02 "CAN_DET_AZIMUTH_12_02";
BA_ "GenSigSendType" SG_ 299 CAN_DET_RANGE_12_02 0;
BA_ "GenSigCmt" SG_ 299 CAN_DET_RANGE_12_02 "CAN_DET_RANGE_12_02";
BA_ "GenSigSendType" SG_ 299 CAN_DET_RANGE_RATE_12_02 0;
BA_ "GenSigCmt" SG_ 299 CAN_DET_RANGE_RATE_12_02 "CAN_DET_RANGE_RATE_12_02";
BA_ "GenSigSendType" SG_ 299 CAN_DET_AMPLITUDE_12_02 0;
BA_ "GenSigCmt" SG_ 299 CAN_DET_AMPLITUDE_12_02 "CAN_DET_AMPLITUDE_12_02";
BA_ "GenSigSendType" SG_ 299 CAN_SCAN_INDEX_2LSB_12_02 0;
BA_ "GenSigCmt" SG_ 299 CAN_SCAN_INDEX_2LSB_12_02 "CAN_SCAN_INDEX_2LSB_12_02";
BA_ "GenSigVtEn" SG_ 299 CAN_DET_CONFID_AZIMUTH_12_03 "CAN_DET_CONFID_AZIMUTH_12_03";
BA_ "GenSigVtName" SG_ 299 CAN_DET_CONFID_AZIMUTH_12_03 "CAN_DET_CONFID_AZIMUTH_12_03";
BA_ "GenSigSendType" SG_ 299 CAN_DET_CONFID_AZIMUTH_12_03 0;
BA_ "GenSigCmt" SG_ 299 CAN_DET_CONFID_AZIMUTH_12_03 "CAN_DET_CONFID_AZIMUTH_12_03";
BA_ "GenSigSendType" SG_ 299 CAN_DET_SUPER_RES_TARGET_12_03 0;
BA_ "GenSigCmt" SG_ 299 CAN_DET_SUPER_RES_TARGET_12_03 "CAN_DET_SUPER_RES_TARGET_12_03";
BA_ "GenSigSendType" SG_ 299 CAN_DET_ND_TARGET_12_03 0;
BA_ "GenSigCmt" SG_ 299 CAN_DET_ND_TARGET_12_03 "CAN_DET_ND_TARGET_12_03";
BA_ "GenSigSendType" SG_ 299 CAN_DET_HOST_VEH_CLUTTER_12_03 0;
BA_ "GenSigCmt" SG_ 299 CAN_DET_HOST_VEH_CLUTTER_12_03 "CAN_DET_HOST_VEH_CLUTTER_12_03";
BA_ "GenSigSendType" SG_ 299 CAN_DET_VALID_LEVEL_12_03 0;
BA_ "GenSigCmt" SG_ 299 CAN_DET_VALID_LEVEL_12_03 "CAN_DET_VALID_LEVEL_12_03";
BA_ "GenSigSendType" SG_ 299 CAN_DET_AZIMUTH_12_03 0;
BA_ "GenSigCmt" SG_ 299 CAN_DET_AZIMUTH_12_03 "CAN_DET_AZIMUTH_12_03";
BA_ "GenSigSendType" SG_ 299 CAN_DET_RANGE_12_03 0;
BA_ "GenSigCmt" SG_ 299 CAN_DET_RANGE_12_03 "CAN_DET_RANGE_12_03";
BA_ "GenSigSendType" SG_ 299 CAN_DET_RANGE_RATE_12_03 0;
BA_ "GenSigCmt" SG_ 299 CAN_DET_RANGE_RATE_12_03 "CAN_DET_RANGE_RATE_12_03";
BA_ "GenSigSendType" SG_ 299 CAN_DET_AMPLITUDE_12_03 0;
BA_ "GenSigCmt" SG_ 299 CAN_DET_AMPLITUDE_12_03 "CAN_DET_AMPLITUDE_12_03";
BA_ "GenSigSendType" SG_ 299 CAN_SCAN_INDEX_2LSB_12_03 0;
BA_ "GenSigCmt" SG_ 299 CAN_SCAN_INDEX_2LSB_12_03 "CAN_SCAN_INDEX_2LSB_12_03";
BA_ "GenSigVtEn" SG_ 299 CAN_DET_CONFID_AZIMUTH_12_04 "CAN_DET_CONFID_AZIMUTH_12_04";
BA_ "GenSigVtName" SG_ 299 CAN_DET_CONFID_AZIMUTH_12_04 "CAN_DET_CONFID_AZIMUTH_12_04";
BA_ "GenSigSendType" SG_ 299 CAN_DET_CONFID_AZIMUTH_12_04 0;
BA_ "GenSigCmt" SG_ 299 CAN_DET_CONFID_AZIMUTH_12_04 "CAN_DET_CONFID_AZIMUTH_12_04";
BA_ "GenSigSendType" SG_ 299 CAN_DET_SUPER_RES_TARGET_12_04 0;
BA_ "GenSigCmt" SG_ 299 CAN_DET_SUPER_RES_TARGET_12_04 "CAN_DET_SUPER_RES_TARGET_12_04";
BA_ "GenSigSendType" SG_ 299 CAN_DET_ND_TARGET_12_04 0;
BA_ "GenSigCmt" SG_ 299 CAN_DET_ND_TARGET_12_04 "CAN_DET_ND_TARGET_12_04";
BA_ "GenSigSendType" SG_ 299 CAN_DET_HOST_VEH_CLUTTER_12_04 0;
BA_ "GenSigCmt" SG_ 299 CAN_DET_HOST_VEH_CLUTTER_12_04 "CAN_DET_HOST_VEH_CLUTTER_12_04";
BA_ "GenSigSendType" SG_ 299 CAN_DET_VALID_LEVEL_12_04 0;
BA_ "GenSigCmt" SG_ 299 CAN_DET_VALID_LEVEL_12_04 "CAN_DET_VALID_LEVEL_12_04";
BA_ "GenSigSendType" SG_ 299 CAN_DET_AZIMUTH_12_04 0;
BA_ "GenSigCmt" SG_ 299 CAN_DET_AZIMUTH_12_04 "CAN_DET_AZIMUTH_12_04";
BA_ "GenSigSendType" SG_ 299 CAN_DET_RANGE_12_04 0;
BA_ "GenSigCmt" SG_ 299 CAN_DET_RANGE_12_04 "CAN_DET_RANGE_12_04";
BA_ "GenSigSendType" SG_ 299 CAN_DET_RANGE_RATE_12_04 0;
BA_ "GenSigCmt" SG_ 299 CAN_DET_RANGE_RATE_12_04 "CAN_DET_RANGE_RATE_12_04";
BA_ "GenSigSendType" SG_ 299 CAN_DET_AMPLITUDE_12_04 0;
BA_ "GenSigCmt" SG_ 299 CAN_DET_AMPLITUDE_12_04 "CAN_DET_AMPLITUDE_12_04";
BA_ "GenSigSendType" SG_ 299 CAN_SCAN_INDEX_2LSB_12_04 0;
BA_ "GenSigCmt" SG_ 299 CAN_SCAN_INDEX_2LSB_12_04 "CAN_SCAN_INDEX_2LSB_12_04";
BA_ "GenSigVtEn" SG_ 299 CAN_DET_CONFID_AZIMUTH_12_05 "CAN_DET_CONFID_AZIMUTH_12_05";
BA_ "GenSigVtName" SG_ 299 CAN_DET_CONFID_AZIMUTH_12_05 "CAN_DET_CONFID_AZIMUTH_12_05";
BA_ "GenSigSendType" SG_ 299 CAN_DET_CONFID_AZIMUTH_12_05 0;
BA_ "GenSigCmt" SG_ 299 CAN_DET_CONFID_AZIMUTH_12_05 "CAN_DET_CONFID_AZIMUTH_12_05";
BA_ "GenSigSendType" SG_ 299 CAN_DET_SUPER_RES_TARGET_12_05 0;
BA_ "GenSigCmt" SG_ 299 CAN_DET_SUPER_RES_TARGET_12_05 "CAN_DET_SUPER_RES_TARGET_12_05";
BA_ "GenSigSendType" SG_ 299 CAN_DET_ND_TARGET_12_05 0;
BA_ "GenSigCmt" SG_ 299 CAN_DET_ND_TARGET_12_05 "CAN_DET_ND_TARGET_12_05";
BA_ "GenSigSendType" SG_ 299 CAN_DET_HOST_VEH_CLUTTER_12_05 0;
BA_ "GenSigCmt" SG_ 299 CAN_DET_HOST_VEH_CLUTTER_12_05 "CAN_DET_HOST_VEH_CLUTTER_12_05";
BA_ "GenSigSendType" SG_ 299 CAN_DET_VALID_LEVEL_12_05 0;
BA_ "GenSigCmt" SG_ 299 CAN_DET_VALID_LEVEL_12_05 "CAN_DET_VALID_LEVEL_12_05";
BA_ "GenSigSendType" SG_ 299 CAN_DET_AZIMUTH_12_05 0;
BA_ "GenSigCmt" SG_ 299 CAN_DET_AZIMUTH_12_05 "CAN_DET_AZIMUTH_12_05";
BA_ "GenSigSendType" SG_ 299 CAN_DET_RANGE_12_05 0;
BA_ "GenSigCmt" SG_ 299 CAN_DET_RANGE_12_05 "CAN_DET_RANGE_12_05";
BA_ "GenSigSendType" SG_ 299 CAN_DET_RANGE_RATE_12_05 0;
BA_ "GenSigCmt" SG_ 299 CAN_DET_RANGE_RATE_12_05 "CAN_DET_RANGE_RATE_12_05";
BA_ "GenSigSendType" SG_ 299 CAN_DET_AMPLITUDE_12_05 0;
BA_ "GenSigCmt" SG_ 299 CAN_DET_AMPLITUDE_12_05 "CAN_DET_AMPLITUDE_12_05";
BA_ "GenSigSendType" SG_ 299 CAN_SCAN_INDEX_2LSB_12_05 0;
BA_ "GenSigCmt" SG_ 299 CAN_SCAN_INDEX_2LSB_12_05 "CAN_SCAN_INDEX_2LSB_12_05";
BA_ "GenSigVtEn" SG_ 299 CAN_DET_CONFID_AZIMUTH_12_06 "CAN_DET_CONFID_AZIMUTH_12_06";
BA_ "GenSigVtName" SG_ 299 CAN_DET_CONFID_AZIMUTH_12_06 "CAN_DET_CONFID_AZIMUTH_12_06";
BA_ "GenSigSendType" SG_ 299 CAN_DET_CONFID_AZIMUTH_12_06 0;
BA_ "GenSigCmt" SG_ 299 CAN_DET_CONFID_AZIMUTH_12_06 "CAN_DET_CONFID_AZIMUTH_12_06";
BA_ "GenSigSendType" SG_ 299 CAN_DET_SUPER_RES_TARGET_12_06 0;
BA_ "GenSigCmt" SG_ 299 CAN_DET_SUPER_RES_TARGET_12_06 "CAN_DET_SUPER_RES_TARGET_12_06";
BA_ "GenSigSendType" SG_ 299 CAN_DET_ND_TARGET_12_06 0;
BA_ "GenSigCmt" SG_ 299 CAN_DET_ND_TARGET_12_06 "CAN_DET_ND_TARGET_12_06";
BA_ "GenSigSendType" SG_ 299 CAN_DET_HOST_VEH_CLUTTER_12_06 0;
BA_ "GenSigCmt" SG_ 299 CAN_DET_HOST_VEH_CLUTTER_12_06 "CAN_DET_HOST_VEH_CLUTTER_12_06";
BA_ "GenSigSendType" SG_ 299 CAN_DET_VALID_LEVEL_12_06 0;
BA_ "GenSigCmt" SG_ 299 CAN_DET_VALID_LEVEL_12_06 "CAN_DET_VALID_LEVEL_12_06";
BA_ "GenSigSendType" SG_ 299 CAN_DET_AZIMUTH_12_06 0;
BA_ "GenSigCmt" SG_ 299 CAN_DET_AZIMUTH_12_06 "CAN_DET_AZIMUTH_12_06";
BA_ "GenSigSendType" SG_ 299 CAN_DET_RANGE_12_06 0;
BA_ "GenSigCmt" SG_ 299 CAN_DET_RANGE_12_06 "CAN_DET_RANGE_12_06";
BA_ "GenSigSendType" SG_ 299 CAN_DET_RANGE_RATE_12_06 0;
BA_ "GenSigCmt" SG_ 299 CAN_DET_RANGE_RATE_12_06 "CAN_DET_RANGE_RATE_12_06";
BA_ "GenSigSendType" SG_ 299 CAN_DET_AMPLITUDE_12_06 0;
BA_ "GenSigCmt" SG_ 299 CAN_DET_AMPLITUDE_12_06 "CAN_DET_AMPLITUDE_12_06";
BA_ "GenSigSendType" SG_ 299 CAN_SCAN_INDEX_2LSB_12_06 0;
BA_ "GenSigCmt" SG_ 299 CAN_SCAN_INDEX_2LSB_12_06 "CAN_SCAN_INDEX_2LSB_12_06";
BA_DEF_DEF_ "UsedOnPgmDBC" "Yes";
BA_DEF_DEF_ "DiagResponse" "No";
BA_DEF_DEF_ "EventRateOfChange" 10000;
BA_DEF_DEF_ "GenSigVtName" "";
BA_DEF_DEF_ "GenSigVtEn" "";
BA_DEF_DEF_ "GenSigCmt" "";
BA_DEF_DEF_ "GenSigSendType" "NoSigSendType";
BA_DEF_DEF_ "GenSigStartValue" 0;
BA_DEF_DEF_ "GenMsgILSupport" "Yes";
BA_DEF_DEF_ "GenMsgSendType" "NoMsgSendType";
BA_DEF_DEF_ "GenMsgCycleTime" 0;
BA_DEF_DEF_ "GenMsgDelayTime" 0;
BA_DEF_DEF_ "GenMsgNrOfRepetition" 0;
BA_DEF_DEF_ "NetworkInitialization" "No";
BA_DEF_DEF_ "GenMsgBackgroundColor" "#ffffff";
BA_DEF_DEF_ "GenMsgForegroundColor" "#000000";
VAL_ 307 CAN_DET_CONFID_AZIMUTH_20_01 3 "Low" 2 "Medium_Low" 1 "Medium_High" 0 "High";
VAL_ 307 CAN_DET_CONFID_AZIMUTH_20_02 3 "Low" 2 "Medium_Low" 1 "Medium_High" 0 "High";
VAL_ 307 CAN_DET_CONFID_AZIMUTH_20_03 3 "Low" 2 "Medium_Low" 1 "Medium_High" 0 "High";
VAL_ 307 CAN_DET_CONFID_AZIMUTH_20_04 3 "Low" 2 "Medium_Low" 1 "Medium_High" 0 "High";
VAL_ 307 CAN_DET_CONFID_AZIMUTH_20_05 3 "Low" 2 "Medium_Low" 1 "Medium_High" 0 "High";
VAL_ 307 CAN_DET_CONFID_AZIMUTH_20_06 3 "Low" 2 "Medium_Low" 1 "Medium_High" 0 "High";
VAL_ 306 CAN_DET_CONFID_AZIMUTH_19_01 3 "Low" 2 "Medium_Low" 1 "Medium_High" 0 "High";
VAL_ 306 CAN_DET_CONFID_AZIMUTH_19_02 3 "Low" 2 "Medium_Low" 1 "Medium_High" 0 "High";
VAL_ 306 CAN_DET_CONFID_AZIMUTH_19_03 3 "Low" 2 "Medium_Low" 1 "Medium_High" 0 "High";
VAL_ 306 CAN_DET_CONFID_AZIMUTH_19_04 3 "Low" 2 "Medium_Low" 1 "Medium_High" 0 "High";
VAL_ 306 CAN_DET_CONFID_AZIMUTH_19_05 3 "Low" 2 "Medium_Low" 1 "Medium_High" 0 "High";
VAL_ 306 CAN_DET_CONFID_AZIMUTH_19_06 3 "Low" 2 "Medium_Low" 1 "Medium_High" 0 "High";
VAL_ 305 CAN_DET_CONFID_AZIMUTH_18_01 3 "Low" 2 "Medium_Low" 1 "Medium_High" 0 "High";
VAL_ 305 CAN_DET_CONFID_AZIMUTH_18_02 3 "Low" 2 "Medium_Low" 1 "Medium_High" 0 "High";
VAL_ 305 CAN_DET_CONFID_AZIMUTH_18_03 3 "Low" 2 "Medium_Low" 1 "Medium_High" 0 "High";
VAL_ 305 CAN_DET_CONFID_AZIMUTH_18_04 3 "Low" 2 "Medium_Low" 1 "Medium_High" 0 "High";
VAL_ 305 CAN_DET_CONFID_AZIMUTH_18_05 3 "Low" 2 "Medium_Low" 1 "Medium_High" 0 "High";
VAL_ 305 CAN_DET_CONFID_AZIMUTH_18_06 3 "Low" 2 "Medium_Low" 1 "Medium_High" 0 "High";
VAL_ 341 CAN_DET_CONFID_AZIMUTH_54 3 "Low" 2 "Medium_Low" 1 "Medium_High" 0 "High";
VAL_ 340 CAN_DET_CONFID_AZIMUTH_53 3 "Low" 2 "Medium_Low" 1 "Medium_High" 0 "High";
VAL_ 339 CAN_DET_CONFID_AZIMUTH_52 3 "Low" 2 "Medium_Low" 1 "Medium_High" 0 "High";
VAL_ 338 CAN_DET_CONFID_AZIMUTH_51 3 "Low" 2 "Medium_Low" 1 "Medium_High" 0 "High";
VAL_ 337 CAN_DET_CONFID_AZIMUTH_50 3 "Low" 2 "Medium_Low" 1 "Medium_High" 0 "High";
VAL_ 336 CAN_DET_CONFID_AZIMUTH_49 3 "Low" 2 "Medium_Low" 1 "Medium_High" 0 "High";
VAL_ 326 CAN_DET_CONFID_AZIMUTH_39 3 "Low" 2 "Medium_Low" 1 "Medium_High" 0 "High";
VAL_ 315 CAN_DET_CONFID_AZIMUTH_28 3 "Low" 2 "Medium_Low" 1 "Medium_High" 0 "High";
VAL_ 304 CAN_DET_CONFID_AZIMUTH_17_01 3 "Low" 2 "Medium_Low" 1 "Medium_High" 0 "High";
VAL_ 304 CAN_DET_CONFID_AZIMUTH_17_02 3 "Low" 2 "Medium_Low" 1 "Medium_High" 0 "High";
VAL_ 304 CAN_DET_CONFID_AZIMUTH_17_03 3 "Low" 2 "Medium_Low" 1 "Medium_High" 0 "High";
VAL_ 304 CAN_DET_CONFID_AZIMUTH_17_04 3 "Low" 2 "Medium_Low" 1 "Medium_High" 0 "High";
VAL_ 304 CAN_DET_CONFID_AZIMUTH_17_05 3 "Low" 2 "Medium_Low" 1 "Medium_High" 0 "High";
VAL_ 304 CAN_DET_CONFID_AZIMUTH_17_06 3 "Low" 2 "Medium_Low" 1 "Medium_High" 0 "High";
VAL_ 303 CAN_DET_CONFID_AZIMUTH_16_01 3 "Low" 2 "Medium_Low" 1 "Medium_High" 0 "High";
VAL_ 303 CAN_DET_CONFID_AZIMUTH_16_02 3 "Low" 2 "Medium_Low" 1 "Medium_High" 0 "High";
VAL_ 303 CAN_DET_CONFID_AZIMUTH_16_03 3 "Low" 2 "Medium_Low" 1 "Medium_High" 0 "High";
VAL_ 303 CAN_DET_CONFID_AZIMUTH_16_04 3 "Low" 2 "Medium_Low" 1 "Medium_High" 0 "High";
VAL_ 303 CAN_DET_CONFID_AZIMUTH_16_05 3 "Low" 2 "Medium_Low" 1 "Medium_High" 0 "High";
VAL_ 303 CAN_DET_CONFID_AZIMUTH_16_06 3 "Low" 2 "Medium_Low" 1 "Medium_High" 0 "High";
VAL_ 302 CAN_DET_CONFID_AZIMUTH_15_01 3 "Low" 2 "Medium_Low" 1 "Medium_High" 0 "High";
VAL_ 302 CAN_DET_CONFID_AZIMUTH_15_02 3 "Low" 2 "Medium_Low" 1 "Medium_High" 0 "High";
VAL_ 302 CAN_DET_CONFID_AZIMUTH_15_03 3 "Low" 2 "Medium_Low" 1 "Medium_High" 0 "High";
VAL_ 302 CAN_DET_CONFID_AZIMUTH_15_04 3 "Low" 2 "Medium_Low" 1 "Medium_High" 0 "High";
VAL_ 302 CAN_DET_CONFID_AZIMUTH_15_05 3 "Low" 2 "Medium_Low" 1 "Medium_High" 0 "High";
VAL_ 302 CAN_DET_CONFID_AZIMUTH_15_06 3 "Low" 2 "Medium_Low" 1 "Medium_High" 0 "High";
VAL_ 301 CAN_DET_CONFID_AZIMUTH_14_01 3 "Low" 2 "Medium_Low" 1 "Medium_High" 0 "High";
VAL_ 301 CAN_DET_CONFID_AZIMUTH_14_02 3 "Low" 2 "Medium_Low" 1 "Medium_High" 0 "High";
VAL_ 301 CAN_DET_CONFID_AZIMUTH_14_03 3 "Low" 2 "Medium_Low" 1 "Medium_High" 0 "High";
VAL_ 301 CAN_DET_CONFID_AZIMUTH_14_04 3 "Low" 2 "Medium_Low" 1 "Medium_High" 0 "High";
VAL_ 301 CAN_DET_CONFID_AZIMUTH_14_05 3 "Low" 2 "Medium_Low" 1 "Medium_High" 0 "High";
VAL_ 301 CAN_DET_CONFID_AZIMUTH_14_06 3 "Low" 2 "Medium_Low" 1 "Medium_High" 0 "High";
VAL_ 300 CAN_DET_CONFID_AZIMUTH_13_01 3 "Low" 2 "Medium_Low" 1 "Medium_High" 0 "High";
VAL_ 300 CAN_DET_CONFID_AZIMUTH_13_02 3 "Low" 2 "Medium_Low" 1 "Medium_High" 0 "High";
VAL_ 300 CAN_DET_CONFID_AZIMUTH_13_03 3 "Low" 2 "Medium_Low" 1 "Medium_High" 0 "High";
VAL_ 300 CAN_DET_CONFID_AZIMUTH_13_04 3 "Low" 2 "Medium_Low" 1 "Medium_High" 0 "High";
VAL_ 300 CAN_DET_CONFID_AZIMUTH_13_05 3 "Low" 2 "Medium_Low" 1 "Medium_High" 0 "High";
VAL_ 300 CAN_DET_CONFID_AZIMUTH_13_06 3 "Low" 2 "Medium_Low" 1 "Medium_High" 0 "High";
VAL_ 299 CAN_DET_CONFID_AZIMUTH_12_01 3 "Low" 2 "Medium_Low" 1 "Medium_High" 0 "High";
VAL_ 299 CAN_DET_CONFID_AZIMUTH_12_02 3 "Low" 2 "Medium_Low" 1 "Medium_High" 0 "High";
VAL_ 299 CAN_DET_CONFID_AZIMUTH_12_03 3 "Low" 2 "Medium_Low" 1 "Medium_High" 0 "High";
VAL_ 299 CAN_DET_CONFID_AZIMUTH_12_04 3 "Low" 2 "Medium_Low" 1 "Medium_High" 0 "High";
VAL_ 299 CAN_DET_CONFID_AZIMUTH_12_05 3 "Low" 2 "Medium_Low" 1 "Medium_High" 0 "High";
VAL_ 299 CAN_DET_CONFID_AZIMUTH_12_06 3 "Low" 2 "Medium_Low" 1 "Medium_High" 0 "High";
